VERSION "dbc-export 1 2026.26.6.5"

NS_ :

BS_:

BU_: ADSP APB APP APS APSB BB BMS CC CMP CMPD CP DAS DI DIF DIR DPB EPAS3P EPAS3S EPASTP EPASTS EPBL EPBR ESP EVSE FC GTW HCML HCMR HVP IBST ICR IDB LS OCS1P ODIN PARK PCS PCS2 PLG PM PMF PMR PNCD PTC RADC RCM RCM2 RCM3 RCU SCCM SCM SCS SDCR TAS TCU TCU2 TPMS TRCM UDS UI UIS UMC USM V2G VC VCBATT VCBATT0 VCBATT1 VCBATT2 VCCC VCFRONT VCFRONT1 VCFRONT2 VCLEFT VCRIGHT VCSEAT2L VCSEAT2R VCSEC VEH

BO_ 1513 APP_alertLog: 8 APP
 SG_ APP_alertID M : 0|14@1+ (1,0) [0|16383] "" Vector__XXX
 SG_ APP_sw456_reason1 m456 : 16|9@1+ (1,0) [0|511] "" Vector__XXX
 SG_ APP_sw456_reason2 m456 : 25|9@1+ (1,0) [0|511] "" Vector__XXX
 SG_ APP_sw456_reason3 m456 : 34|9@1+ (1,0) [0|511] "" Vector__XXX
 SG_ APP_sw457_reason1 m457 : 16|9@1+ (1,0) [0|511] "" Vector__XXX
 SG_ APP_sw457_reason2 m457 : 25|9@1+ (1,0) [0|511] "" Vector__XXX
 SG_ APP_sw457_reason3 m457 : 34|9@1+ (1,0) [0|511] "" Vector__XXX
 SG_ APP_sw457_safeStateManeuver m457 : 43|2@1+ (1,0) [0|3] "" Vector__XXX
 SG_ APP_sw458_fsdCollisionValue m458 : 16|7@1+ (1,0) [0|127] "%" Vector__XXX
 SG_ APP_sw458_aebCollisionValue m458 : 24|7@1+ (1,0) [0|127] "%" Vector__XXX
 SG_ APP_sw458_aebDurationAtAceOnset m458 : 32|7@1+ (0.05,0) [0|6.35] "s" Vector__XXX
 SG_ APP_sw458_targetDistance m458 : 40|8@1+ (0.5,0) [0|127.5] "m" Vector__XXX
 SG_ APP_sw458_targetRelativeSpeed m458 : 48|8@1+ (0.4,-51.2) [-51.2|50.8] "m/s" Vector__XXX
 SG_ APP_sw458_egoVehicleSpeed m458 : 56|8@1+ (0.25,0) [0|63.75] "m/s" Vector__XXX
 SG_ APP_sw459_status m459 : 16|1@1+ (1,0) [0|1] "" Vector__XXX
 SG_ APP_sw460_status m460 : 16|1@1+ (1,0) [0|1] "" Vector__XXX
 SG_ APP_sw461_rerouteRequest m461 : 16|2@1+ (1,0) [0|3] "" Vector__XXX
 SG_ APP_sw461_rerouteReason m461 : 18|9@1+ (1,0) [0|511] "" Vector__XXX
 SG_ APP_sw465_reason1 m465 : 16|9@1+ (1,0) [0|511] "" Vector__XXX
 SG_ APP_sw465_reason2 m465 : 25|9@1+ (1,0) [0|511] "" Vector__XXX
 SG_ APP_sw465_reason3 m465 : 34|9@1+ (1,0) [0|511] "" Vector__XXX
 SG_ APP_sw465_safeStateManeuver m465 : 43|2@1+ (1,0) [0|3] "" Vector__XXX

BO_ 1045 APP_backupDashCamStatus: 1 APP
 SG_ APP_backupDashCamFeedGood : 0|1@1+ (1,0) [0|1] "" Vector__XXX
 SG_ APP_backupDashCamFrameRate : 1|7@1+ (1,0) [0|127] "" Vector__XXX

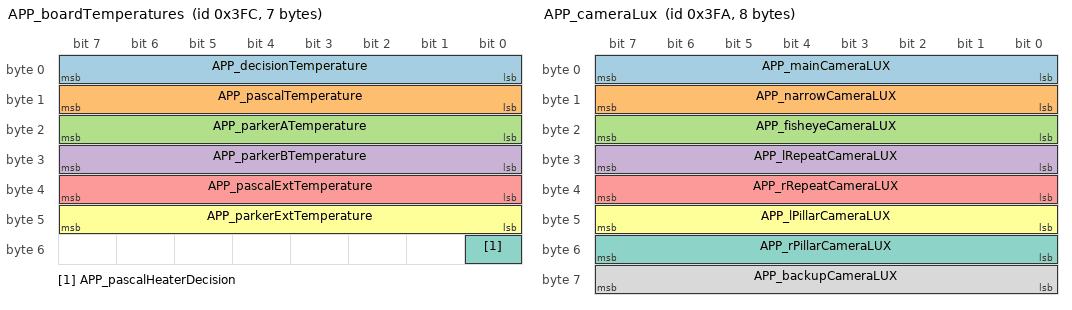
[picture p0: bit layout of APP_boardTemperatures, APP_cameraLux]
BO_ 1020 APP_boardTemperatures: 7 APP
 SG_ APP_decisionTemperature : 0|8@1+ (1,-128) [-128|127] "C" Vector__XXX
 SG_ APP_pascalTemperature : 8|8@1+ (1,-128) [-128|127] "C" Vector__XXX
 SG_ APP_parkerATemperature : 16|8@1+ (1,-128) [-128|127] "C" Vector__XXX
 SG_ APP_parkerBTemperature : 24|8@1+ (1,-128) [-128|127] "C" Vector__XXX
 SG_ APP_pascalExtTemperature : 32|8@1+ (1,-128) [-128|127] "C" Vector__XXX
 SG_ APP_parkerExtTemperature : 40|8@1+ (1,-128) [-128|127] "C" Vector__XXX
 SG_ APP_pascalHeaterDecision : 48|1@1+ (1,0) [0|1] "" Vector__XXX

BO_ 2046 APP_camCalibrationStatus: 6 APP
 SG_ APP_cameraPosition M : 0|4@1+ (1,0) [0|15] "" Vector__XXX
 SG_ APP_mainCamExtPitchCal m1 : 8|9@1+ (0.05,-12.5) [-12.5|12.5] "deg" Vector__XXX
 SG_ APP_mainCamExtYawCal m1 : 17|9@1+ (0.05,-12.5) [-12.5|12.5] "deg" Vector__XXX
 SG_ APP_mainCalibTime m1 : 26|7@1+ (1,0) [0|126] "min" Vector__XXX
 SG_ APP_mainCalibProgress m1 : 33|7@1+ (1,0) [0|100] "percent" Vector__XXX
 SG_ APP_mainCalibrated m1 : 40|1@1+ (1,0) [0|1] "" Vector__XXX
 SG_ APP_narrowCamExtPitchCal m2 : 8|9@1+ (0.05,-12.5) [-12.5|12.5] "deg" Vector__XXX
 SG_ APP_narrowCamExtYawCal m2 : 17|9@1+ (0.05,-12.5) [-12.5|12.5] "deg" Vector__XXX
 SG_ APP_narrowCalibTime m2 : 26|7@1+ (1,0) [0|126] "min" Vector__XXX
 SG_ APP_narrowCalibProgress m2 : 33|7@1+ (1,0) [0|100] "percent" Vector__XXX
 SG_ APP_narrowCalibrated m2 : 40|1@1+ (1,0) [0|1] "" Vector__XXX
 SG_ APP_fisheyeCamExtPitchCal m3 : 8|9@1+ (0.05,-12.5) [-12.5|12.5] "deg" Vector__XXX
 SG_ APP_fisheyeCamExtYawCal m3 : 17|9@1+ (0.05,-12.5) [-12.5|12.5] "deg" Vector__XXX
 SG_ APP_fisheyeCalibTime m3 : 26|7@1+ (1,0) [0|126] "min" Vector__XXX
 SG_ APP_fisheyeCalibProgress m3 : 33|7@1+ (1,0) [0|100] "percent" Vector__XXX
 SG_ APP_fisheyeCalibrated m3 : 40|1@1+ (1,0) [0|1] "" Vector__XXX
 SG_ APP_lPillarCamExtPitchCal m4 : 8|9@1+ (0.05,-12.5) [-12.5|12.5] "deg" Vector__XXX
 SG_ APP_lPillarCamExtYawCal m4 : 17|9@1+ (0.05,-12.5) [-12.5|12.5] "deg" Vector__XXX
 SG_ APP_lPillarCalibTime m4 : 26|7@1+ (1,0) [0|126] "min" Vector__XXX
 SG_ APP_lPillarCalibProgress m4 : 33|7@1+ (1,0) [0|100] "percent" Vector__XXX
 SG_ APP_lPillarCalibrated m4 : 40|1@1+ (1,0) [0|1] "" Vector__XXX
 SG_ APP_rPillarCamExtPitchCal m5 : 8|9@1+ (0.05,-12.5) [-12.5|12.5] "deg" Vector__XXX
 SG_ APP_rPillarCamExtYawCal m5 : 17|9@1+ (0.05,-12.5) [-12.5|12.5] "deg" Vector__XXX
 SG_ APP_rPillarCalibTime m5 : 26|7@1+ (1,0) [0|126] "min" Vector__XXX
 SG_ APP_rPillarCalibProgress m5 : 33|7@1+ (1,0) [0|100] "percent" Vector__XXX
 SG_ APP_rPillarCalibrated m5 : 40|1@1+ (1,0) [0|1] "" Vector__XXX
 SG_ APP_lRepeatCamExtPitchCal m6 : 8|9@1+ (0.05,-12.5) [-12.5|12.5] "deg" Vector__XXX
 SG_ APP_lRepeatCamExtYawCal m6 : 17|9@1+ (0.05,-12.5) [-12.5|12.5] "deg" Vector__XXX
 SG_ APP_lRepeatCalibTime m6 : 26|7@1+ (1,0) [0|126] "min" Vector__XXX
 SG_ APP_lRepeatCalibProgress m6 : 33|7@1+ (1,0) [0|100] "percent" Vector__XXX
 SG_ APP_lRepeatCalibrated m6 : 40|1@1+ (1,0) [0|1] "" Vector__XXX
 SG_ APP_rRepeatCamExtPitchCal m7 : 8|9@1+ (0.05,-12.5) [-12.5|12.5] "deg" Vector__XXX
 SG_ APP_rRepeatCamExtYawCal m7 : 17|9@1+ (0.05,-12.5) [-12.5|12.5] "deg" Vector__XXX
 SG_ APP_rRepeatCalibTime m7 : 26|7@1+ (1,0) [0|126] "min" Vector__XXX
 SG_ APP_rRepeatCalibProgress m7 : 33|7@1+ (1,0) [0|100] "percent" Vector__XXX
 SG_ APP_rRepeatCalibrated m7 : 40|1@1+ (1,0) [0|1] "" Vector__XXX
 SG_ APP_backupCamExtPitchCal m8 : 8|9@1+ (0.05,-12.5) [-12.5|12.5] "deg" Vector__XXX
 SG_ APP_backupCamExtYawCal m8 : 17|9@1+ (0.05,-12.5) [-12.5|12.5] "deg" Vector__XXX
 SG_ APP_backupCalibTime m8 : 26|7@1+ (1,0) [0|126] "min" Vector__XXX
 SG_ APP_backupCalibProgress m8 : 33|7@1+ (1,0) [0|100] "percent" Vector__XXX
 SG_ APP_backupCalibrated m8 : 40|1@1+ (1,0) [0|1] "" Vector__XXX
 SG_ APP_fasciaCamExtPitchCal m10 : 8|9@1+ (0.05,-12.5) [-12.5|12.5] "deg" Vector__XXX
 SG_ APP_fasciaCamExtYawCal m10 : 17|9@1+ (0.05,-12.5) [-12.5|12.5] "deg" Vector__XXX
 SG_ APP_fasciaCalibTime m10 : 26|7@1+ (1,0) [0|126] "min" Vector__XXX
 SG_ APP_fasciaCalibProgress m10 : 33|7@1+ (1,0) [0|100] "percent" Vector__XXX
 SG_ APP_fasciaCalibrated m10 : 40|1@1+ (1,0) [0|1] "" Vector__XXX

BO_ 1018 APP_cameraLux: 8 APP
 SG_ APP_mainCameraLUX : 0|8@1+ (0.5,0) [0|127] "lux^0.5" Vector__XXX
 SG_ APP_narrowCameraLUX : 8|8@1+ (0.5,0) [0|127] "lux^0.5" Vector__XXX
 SG_ APP_fisheyeCameraLUX : 16|8@1+ (0.5,0) [0|127] "lux^0.5" Vector__XXX
 SG_ APP_lRepeatCameraLUX : 24|8@1+ (0.5,0) [0|127] "lux^0.5" Vector__XXX
 SG_ APP_rRepeatCameraLUX : 32|8@1+ (0.5,0) [0|127] "lux^0.5" Vector__XXX
 SG_ APP_lPillarCameraLUX : 40|8@1+ (0.5,0) [0|127] "lux^0.5" Vector__XXX
 SG_ APP_rPillarCameraLUX : 48|8@1+ (0.5,0) [0|127] "lux^0.5" Vector__XXX
 SG_ APP_backupCameraLUX : 56|8@1+ (0.5,0) [0|127] "lux^0.5" Vector__XXX

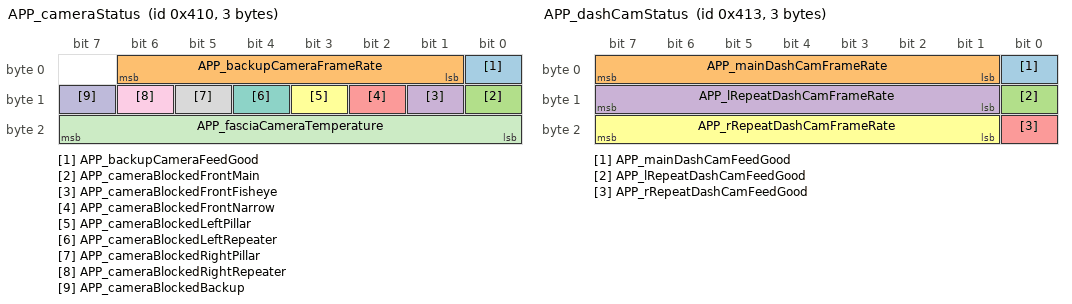
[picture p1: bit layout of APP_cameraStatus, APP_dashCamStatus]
BO_ 1040 APP_cameraStatus: 3 APP
 SG_ APP_backupCameraFeedGood : 0|1@1+ (1,0) [0|1] "" Vector__XXX
 SG_ APP_backupCameraFrameRate : 1|6@1+ (1,0) [0|63] "" Vector__XXX
 SG_ APP_cameraBlockedFrontMain : 8|1@1+ (1,0) [0|1] "" Vector__XXX
 SG_ APP_cameraBlockedFrontFisheye : 9|1@1+ (1,0) [0|1] "" Vector__XXX
 SG_ APP_cameraBlockedFrontNarrow : 10|1@1+ (1,0) [0|1] "" Vector__XXX
 SG_ APP_cameraBlockedLeftPillar : 11|1@1+ (1,0) [0|1] "" Vector__XXX
 SG_ APP_cameraBlockedLeftRepeater : 12|1@1+ (1,0) [0|1] "" Vector__XXX
 SG_ APP_cameraBlockedRightPillar : 13|1@1+ (1,0) [0|1] "" Vector__XXX
 SG_ APP_cameraBlockedRightRepeater : 14|1@1+ (1,0) [0|1] "" Vector__XXX
 SG_ APP_cameraBlockedBackup : 15|1@1+ (1,0) [0|1] "" Vector__XXX
 SG_ APP_fasciaCameraTemperature : 16|8@1+ (1,-60) [-60|194] "C" Vector__XXX

BO_ 1177 APP_cameraTemperatures: 8 APP
 SG_ APP_rRepeaterCameraTemperature : 24|8@1+ (1,-60) [-60|195] "C" Vector__XXX
 SG_ APP_lRepeaterCameraTemperature : 32|8@1+ (1,-60) [-60|195] "C" Vector__XXX

BO_ 1043 APP_dashCamStatus: 3 APP
 SG_ APP_mainDashCamFeedGood : 0|1@1+ (1,0) [0|1] "" Vector__XXX
 SG_ APP_mainDashCamFrameRate : 1|7@1+ (1,0) [0|127] "" Vector__XXX
 SG_ APP_lRepeatDashCamFeedGood : 8|1@1+ (1,0) [0|1] "" Vector__XXX
 SG_ APP_lRepeatDashCamFrameRate : 9|7@1+ (1,0) [0|127] "" Vector__XXX
 SG_ APP_rRepeatDashCamFeedGood : 16|1@1+ (1,0) [0|1] "" Vector__XXX
 SG_ APP_rRepeatDashCamFrameRate : 17|7@1+ (1,0) [0|127] "" Vector__XXX

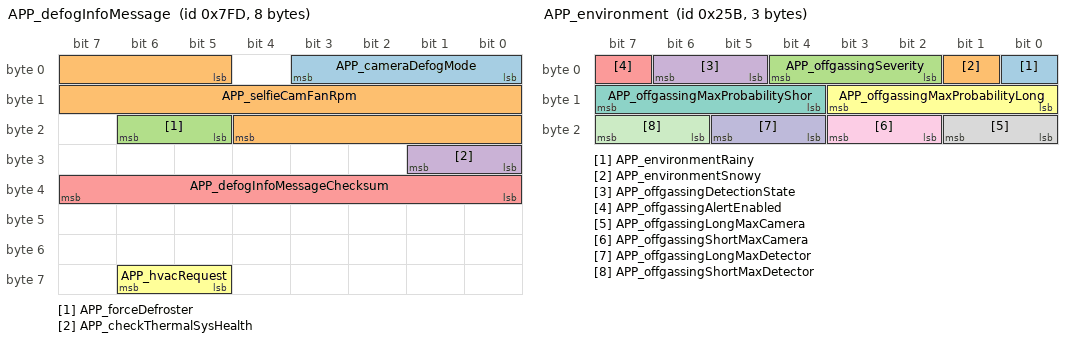
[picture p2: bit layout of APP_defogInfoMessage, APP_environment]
BO_ 2045 APP_defogInfoMessage: 8 APP
 SG_ APP_cameraDefogMode : 0|4@1+ (1,0) [1|15] "" Vector__XXX
 SG_ APP_selfieCamFanRpm : 5|16@1+ (1,0) [0|65534] "rpm" Vector__XXX
 SG_ APP_forceDefroster : 21|2@1+ (1,0) [1|3] "" Vector__XXX
 SG_ APP_checkThermalSysHealth : 24|2@1+ (1,0) [1|3] "" Vector__XXX
 SG_ APP_defogInfoMessageChecksum : 32|8@1+ (1,0) [0|255] "" Vector__XXX
 SG_ APP_hvacRequest : 61|2@1+ (1,0) [1|3] "" Vector__XXX

BO_ 939 APP_driverMonitorStatus: 5 APP
 SG_ APP_cabinCamTelemetryOn : 0|1@1+ (1,0) [0|1] "" Vector__XXX
 SG_ APP_attnMonitorVersion : 1|3@1+ (1,0) [0|6] "" Vector__XXX
 SG_ APP_attnBasedDriverMonitorOn : 4|1@1+ (1,0) [0|1] "" Vector__XXX
 SG_ APP_handsOnDetected : 5|1@1+ (1,0) [0|1] "" Vector__XXX
 SG_ APP_handsOnDetectedSource : 8|3@1+ (1,0) [0|6] "" Vector__XXX
 SG_ APP_cabinCamBlinded : 11|1@1+ (1,0) [0|1] "" Vector__XXX
 SG_ APP_cabinCamDark : 12|1@1+ (1,0) [0|1] "" Vector__XXX
 SG_ APP_driverStateUnknown : 13|1@1+ (1,0) [0|1] "" Vector__XXX
 SG_ APP_driverNotLively : 14|1@1+ (1,0) [0|1] "" Vector__XXX
 SG_ APP_driverStateUnknownHyst : 15|1@1+ (1,0) [0|1] "" Vector__XXX
 SG_ APP_driverLowNominal : 16|1@1+ (1,0) [0|1] "" Vector__XXX
 SG_ APP_driverHeadCappedHyst : 17|1@1+ (1,0) [0|1] "" Vector__XXX
 SG_ APP_driverSunglassesUseHyst : 18|1@1+ (1,0) [0|1] "" Vector__XXX
 SG_ APP_cabinLowLux : 19|1@1+ (1,0) [0|1] "" Vector__XXX
 SG_ APP_cabinCamInconsistent : 20|1@1+ (1,0) [0|1] "" Vector__XXX
 SG_ APP_driverLeaningBack : 21|1@1+ (1,0) [0|1] "" Vector__XXX
 SG_ APP_driverLowEyeVisibility : 22|1@1+ (1,0) [0|1] "" Vector__XXX
 SG_ APP_driverHandsNotReady : 23|1@1+ (1,0) [0|1] "" Vector__XXX
 SG_ APP_driverSeatUnoccupied : 24|1@1+ (1,0) [0|1] "" Vector__XXX
 SG_ APP_handsOnInputRequired : 25|1@1+ (1,0) [0|1] "" Vector__XXX
 SG_ APP_cabinCamDarkHyst : 26|1@1+ (1,0) [0|1] "" Vector__XXX
 SG_ APP_cabinLowLuxHyst : 27|1@1+ (1,0) [0|1] "" Vector__XXX
 SG_ APP_ADDWSystemStatus : 28|2@1+ (1,0) [0|3] "" Vector__XXX
 SG_ APP_dmStrictness : 30|2@1+ (1,0) [1|3] "" Vector__XXX
 SG_ APP_dmStrictnessReason : 32|6@1+ (1,0) [1|63] "" Vector__XXX

BO_ 603 APP_environment: 3 APP
 SG_ APP_environmentRainy : 0|1@1+ (1,0) [0|1] "" Vector__XXX
 SG_ APP_environmentSnowy : 1|1@1+ (1,0) [0|1] "" Vector__XXX
 SG_ APP_offgassingSeverity : 2|3@1+ (1,0) [1|7] "" Vector__XXX
 SG_ APP_offgassingDetectionState : 5|2@1+ (1,0) [1|3] "" Vector__XXX
 SG_ APP_offgassingAlertEnabled : 7|1@1+ (1,0) [0|1] "" Vector__XXX
 SG_ APP_offgassingMaxProbabilityLong : 8|4@1+ (1,0) [1|15] "" Vector__XXX
 SG_ APP_offgassingMaxProbabilityShor : 12|4@1+ (1,0) [1|15] "" Vector__XXX
 SG_ APP_offgassingLongMaxCamera : 16|2@1+ (1,0) [1|3] "" Vector__XXX
 SG_ APP_offgassingShortMaxCamera : 18|2@1+ (1,0) [1|3] "" Vector__XXX
 SG_ APP_offgassingLongMaxDetector : 20|2@1+ (1,0) [1|3] "" Vector__XXX
 SG_ APP_offgassingShortMaxDetector : 22|2@1+ (1,0) [1|3] "" Vector__XXX

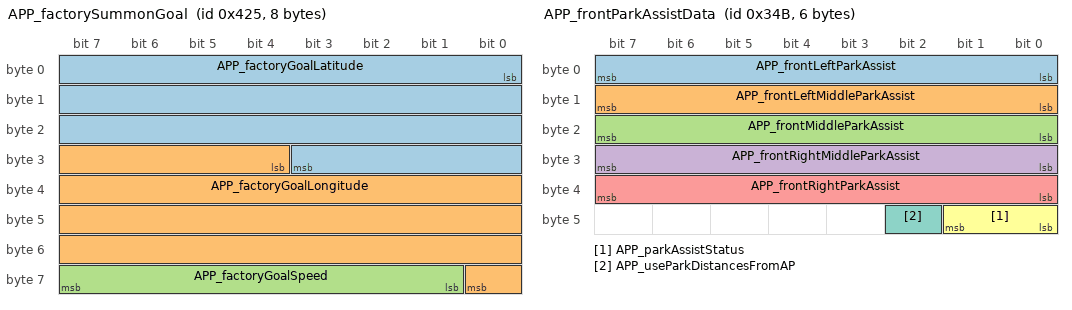
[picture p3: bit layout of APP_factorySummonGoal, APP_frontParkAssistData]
BO_ 1061 APP_factorySummonGoal: 8 APP
 SG_ APP_factoryGoalLatitude : 0|28@1- (1.0e-06,0) [-134.217728|134.217727] "deg" Vector__XXX
 SG_ APP_factoryGoalLongitude : 28|29@1- (1.0e-06,0) [-268.435456|268.435454] "deg" Vector__XXX
 SG_ APP_factoryGoalSpeed : 57|7@1+ (1,0) [0|100] "mph" Vector__XXX

BO_ 843 APP_frontParkAssistData: 6 APP
 SG_ APP_frontLeftParkAssist : 0|8@1+ (1,0) [0|254] "cm" Vector__XXX
 SG_ APP_frontLeftMiddleParkAssist : 8|8@1+ (1,0) [0|254] "cm" Vector__XXX
 SG_ APP_frontMiddleParkAssist : 16|8@1+ (1,0) [0|254] "cm" Vector__XXX
 SG_ APP_frontRightMiddleParkAssist : 24|8@1+ (1,0) [0|254] "cm" Vector__XXX
 SG_ APP_frontRightParkAssist : 32|8@1+ (1,0) [0|254] "cm" Vector__XXX
 SG_ APP_parkAssistStatus : 40|2@1+ (1,0) [0|2] "" Vector__XXX
 SG_ APP_useParkDistancesFromAP : 42|1@1+ (1,0) [0|1] "" Vector__XXX

BO_ 1353 APP_info: 8 APP
 SG_ APP_infoIndex M : 0|8@1+ (1,0) [0|255] "" Vector__XXX
 SG_ APP_buildType m0 : 8|8@1+ (1,0) [0|255] "" Vector__XXX

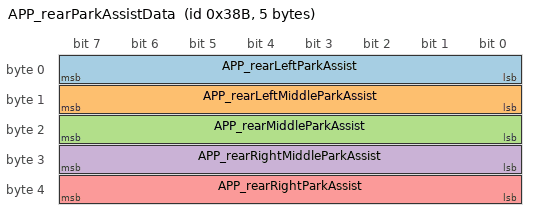
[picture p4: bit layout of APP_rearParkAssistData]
BO_ 907 APP_rearParkAssistData: 5 APP
 SG_ APP_rearLeftParkAssist : 0|8@1+ (1,0) [0|254] "cm" Vector__XXX
 SG_ APP_rearLeftMiddleParkAssist : 8|8@1+ (1,0) [0|254] "cm" Vector__XXX
 SG_ APP_rearMiddleParkAssist : 16|8@1+ (1,0) [0|254] "cm" Vector__XXX
 SG_ APP_rearRightMiddleParkAssist : 24|8@1+ (1,0) [0|254] "cm" Vector__XXX
 SG_ APP_rearRightParkAssist : 32|8@1+ (1,0) [0|254] "cm" Vector__XXX

BO_TX_BU_ 1045 : APP;
BO_TX_BU_ 1020 : APP;
BO_TX_BU_ 2046 : APP;
BO_TX_BU_ 1018 : APP;
BO_TX_BU_ 1040 : APP;
BO_TX_BU_ 1177 : APP;
BO_TX_BU_ 1043 : APP;
BO_TX_BU_ 2045 : APP;
BO_TX_BU_ 939 : APP;
BO_TX_BU_ 603 : APP;
BO_TX_BU_ 1061 : APP;
BO_TX_BU_ 843 : APP;
BO_TX_BU_ 1353 : APP;
BO_TX_BU_ 907 : APP;
CM_ SG_ 1513 APP_sw456_reason1 "Driver assistance computer (primary): sw456 reason1";
CM_ SG_ 1513 APP_sw456_reason2 "Driver assistance computer (primary): sw456 reason2";
CM_ SG_ 1513 APP_sw456_reason3 "Driver assistance computer (primary): sw456 reason3";
CM_ SG_ 1513 APP_sw457_reason1 "Driver assistance computer (primary): sw457 reason1";
CM_ SG_ 1513 APP_sw457_reason2 "Driver assistance computer (primary): sw457 reason2";
CM_ SG_ 1513 APP_sw457_reason3 "Driver assistance computer (primary): sw457 reason3";
CM_ SG_ 1513 APP_sw457_safeStateManeuver "Driver assistance computer (primary): sw457 safe state maneuver";
CM_ SG_ 1513 APP_sw458_fsdCollisionValue "Driver assistance computer (primary): sw458 fsd collision value";
CM_ SG_ 1513 APP_sw458_aebCollisionValue "Driver assistance computer (primary): sw458 aeb collision value";
CM_ SG_ 1513 APP_sw458_aebDurationAtAceOnset "Driver assistance computer (primary): sw458 aeb duration at ace onset";
CM_ SG_ 1513 APP_sw458_targetDistance "Driver assistance computer (primary): sw458 target distance";
CM_ SG_ 1513 APP_sw458_targetRelativeSpeed "Driver assistance computer (primary): sw458 target relative speed";
CM_ SG_ 1513 APP_sw458_egoVehicleSpeed "Driver assistance computer (primary): sw458 ego vehicle speed";
CM_ SG_ 1513 APP_sw459_status "Driver assistance computer (primary): sw459 status";
CM_ SG_ 1513 APP_sw460_status "Driver assistance computer (primary): sw460 status";
CM_ SG_ 1513 APP_sw461_rerouteRequest "Driver assistance computer (primary): sw461 reroute request";
CM_ SG_ 1513 APP_sw461_rerouteReason "Driver assistance computer (primary): sw461 reroute reason";
CM_ SG_ 1513 APP_sw465_reason1 "Driver assistance computer (primary): sw465 reason1";
CM_ SG_ 1513 APP_sw465_reason2 "Driver assistance computer (primary): sw465 reason2";
CM_ SG_ 1513 APP_sw465_reason3 "Driver assistance computer (primary): sw465 reason3";
CM_ SG_ 1513 APP_sw465_safeStateManeuver "Driver assistance computer (primary): sw465 safe state maneuver";
CM_ BO_ 1045 "Driver assistance computer (primary) message: backup dash cam status";
CM_ SG_ 1045 APP_backupDashCamFeedGood "Indicates if the backup dash cam stream is healthy.";
CM_ SG_ 1045 APP_backupDashCamFrameRate "The backup dash cam frame rate.";
CM_ BO_ 1020 "Driver assistance computer (primary) message: board temperatures";
CM_ SG_ 1020 APP_decisionTemperature "Rolling average of Parker and Pascal temperature.";
CM_ SG_ 1020 APP_pascalTemperature "Temperature of Autopilot GPU";
CM_ SG_ 1020 APP_parkerATemperature "Temperature of Autopilot CPU(1)";
CM_ SG_ 1020 APP_parkerBTemperature "Temperature of Autopilot CPU(1)";
CM_ SG_ 1020 APP_pascalExtTemperature "External temperature of Autopilot GPU";
CM_ SG_ 1020 APP_parkerExtTemperature "External temperature of Parker";
CM_ SG_ 1020 APP_pascalHeaterDecision "Pascal heater descision on/off";
CM_ BO_ 2046 "Driver assistance computer (primary) message: cam calibration status";
CM_ SG_ 2046 APP_cameraPosition "Driver assistance computer (primary): camera position";
CM_ SG_ 2046 APP_mainCamExtPitchCal "The calibration, pitch or yaw offset of a camera; raw 511 = signal not available (SNA)";
CM_ SG_ 2046 APP_mainCamExtYawCal "The calibration, pitch or yaw offset of a camera; raw 511 = signal not available (SNA)";
CM_ SG_ 2046 APP_mainCalibTime "Driver assistance computer (primary): main calib time; raw 127 = signal not available (SNA)";
CM_ SG_ 2046 APP_mainCalibProgress "The percent progress of the main camera calibration; raw 127 = signal not available (SNA)";
CM_ SG_ 2046 APP_mainCalibrated "Whether or not the main camera is calibrated.";
CM_ SG_ 2046 APP_narrowCamExtPitchCal "The calibration, pitch or yaw offset of a camera; raw 511 = signal not available (SNA)";
CM_ SG_ 2046 APP_narrowCamExtYawCal "The calibration, pitch or yaw offset of a camera; raw 511 = signal not available (SNA)";
CM_ SG_ 2046 APP_narrowCalibTime "Driver assistance computer (primary): narrow calib time; raw 127 = signal not available (SNA)";
CM_ SG_ 2046 APP_narrowCalibProgress "The percent progress of the narrow camera calibration; raw 127 = signal not available (SNA)";
CM_ SG_ 2046 APP_narrowCalibrated "Whether or not the narrow camera is calibrated.";
CM_ SG_ 2046 APP_fisheyeCamExtPitchCal "The calibration, pitch or yaw offset of a camera; raw 511 = signal not available (SNA)";
CM_ SG_ 2046 APP_fisheyeCamExtYawCal "The calibration, pitch or yaw offset of a camera; raw 511 = signal not available (SNA)";
CM_ SG_ 2046 APP_fisheyeCalibTime "Driver assistance computer (primary): fisheye calib time; raw 127 = signal not available (SNA)";
CM_ SG_ 2046 APP_fisheyeCalibProgress "The percent progress of the fisheye camera calibration; raw 127 = signal not available (SNA)";
CM_ SG_ 2046 APP_fisheyeCalibrated "Whether or not the fisheye camera is calibrated.";
CM_ SG_ 2046 APP_lPillarCamExtPitchCal "The calibration, pitch or yaw offset of a camera; raw 511 = signal not available (SNA)";
CM_ SG_ 2046 APP_lPillarCamExtYawCal "The calibration, pitch or yaw offset of a camera; raw 511 = signal not available (SNA)";
CM_ SG_ 2046 APP_lPillarCalibTime "Driver assistance computer (primary): l pillar calib time; raw 127 = signal not available (SNA)";
CM_ SG_ 2046 APP_lPillarCalibProgress "The percent progress of the left pillar camera calibration; raw 127 = signal not available (SNA)";
CM_ SG_ 2046 APP_lPillarCalibrated "Whether or not the left pillar camera is calibrated.";
CM_ SG_ 2046 APP_rPillarCamExtPitchCal "The calibration, pitch or yaw offset of a camera; raw 511 = signal not available (SNA)";
CM_ SG_ 2046 APP_rPillarCamExtYawCal "The calibration, pitch or yaw offset of a camera; raw 511 = signal not available (SNA)";
CM_ SG_ 2046 APP_rPillarCalibTime "Driver assistance computer (primary): r pillar calib time; raw 127 = signal not available (SNA)";
CM_ SG_ 2046 APP_rPillarCalibProgress "The percent progress of the right pillar camera calibration; raw 127 = signal not available (SNA)";
CM_ SG_ 2046 APP_rPillarCalibrated "Whether or not the right pillar camera is calibrated.";
CM_ SG_ 2046 APP_lRepeatCamExtPitchCal "The calibration, pitch or yaw offset of a camera; raw 511 = signal not available (SNA)";
CM_ SG_ 2046 APP_lRepeatCamExtYawCal "The calibration, pitch or yaw offset of a camera; raw 511 = signal not available (SNA)";
CM_ SG_ 2046 APP_lRepeatCalibTime "Driver assistance computer (primary): l repeat calib time; raw 127 = signal not available (SNA)";
CM_ SG_ 2046 APP_lRepeatCalibProgress "The percent progress of the left repeater camera calibration; raw 127 = signal not available (SNA)";
CM_ SG_ 2046 APP_lRepeatCalibrated "Whether or not the left repeater camera is calibrated.";
CM_ SG_ 2046 APP_rRepeatCamExtPitchCal "The calibration, pitch or yaw offset of a camera; raw 511 = signal not available (SNA)";
CM_ SG_ 2046 APP_rRepeatCamExtYawCal "The calibration, pitch or yaw offset of a camera; raw 511 = signal not available (SNA)";
CM_ SG_ 2046 APP_rRepeatCalibTime "Driver assistance computer (primary): r repeat calib time; raw 127 = signal not available (SNA)";
CM_ SG_ 2046 APP_rRepeatCalibProgress "The percent progress of the right repeater camera calibration; raw 127 = signal not available (SNA)";
CM_ SG_ 2046 APP_rRepeatCalibrated "Whether or not the right repeater camera is calibrated.";
CM_ SG_ 2046 APP_backupCamExtPitchCal "The calibration, pitch or yaw offset of a camera; raw 511 = signal not available (SNA)";
CM_ SG_ 2046 APP_backupCamExtYawCal "The calibration, pitch or yaw offset of a camera; raw 511 = signal not available (SNA)";
CM_ SG_ 2046 APP_backupCalibTime "Driver assistance computer (primary): backup calib time; raw 127 = signal not available (SNA)";
CM_ SG_ 2046 APP_backupCalibProgress "The percent progress of the backup calibration; raw 127 = signal not available (SNA)";
CM_ SG_ 2046 APP_backupCalibrated "Whether or not the backup camera is calibrated.";
CM_ SG_ 2046 APP_fasciaCamExtPitchCal "The calibration, pitch or yaw offset of a camera; raw 511 = signal not available (SNA)";
CM_ SG_ 2046 APP_fasciaCamExtYawCal "The calibration, pitch or yaw offset of a camera; raw 511 = signal not available (SNA)";
CM_ SG_ 2046 APP_fasciaCalibTime "Driver assistance computer (primary): fascia calib time; raw 127 = signal not available (SNA)";
CM_ SG_ 2046 APP_fasciaCalibProgress "The percent progress of the fascia calibration; raw 127 = signal not available (SNA)";
CM_ SG_ 2046 APP_fasciaCalibrated "Whether or not the fascia camera is calibrated.";
CM_ BO_ 1018 "Driver assistance computer (primary) message: camera lux";
CM_ SG_ 1018 APP_mainCameraLUX "Amount of illuminance seen by the main camera; raw 255 = signal not available (SNA)";
CM_ SG_ 1018 APP_narrowCameraLUX "Driver assistance computer (primary): narrow camera LUX; raw 255 = signal not available (SNA)";
CM_ SG_ 1018 APP_fisheyeCameraLUX "Driver assistance computer (primary): fisheye camera LUX; raw 255 = signal not available (SNA)";
CM_ SG_ 1018 APP_lRepeatCameraLUX "Driver assistance computer (primary): l repeat camera LUX; raw 255 = signal not available (SNA)";
CM_ SG_ 1018 APP_rRepeatCameraLUX "Driver assistance computer (primary): r repeat camera LUX; raw 255 = signal not available (SNA)";
CM_ SG_ 1018 APP_lPillarCameraLUX "Driver assistance computer (primary): l pillar camera LUX; raw 255 = signal not available (SNA)";
CM_ SG_ 1018 APP_rPillarCameraLUX "Driver assistance computer (primary): r pillar camera LUX; raw 255 = signal not available (SNA)";
CM_ SG_ 1018 APP_backupCameraLUX "Driver assistance computer (primary): backup camera LUX; raw 255 = signal not available (SNA)";
CM_ BO_ 1040 "Driver assistance computer (primary) message: camera status";
CM_ SG_ 1040 APP_backupCameraFeedGood "Indicates if the backup camera stream is healthy.";
CM_ SG_ 1040 APP_backupCameraFrameRate "The backup camera frame rate.";
CM_ SG_ 1040 APP_cameraBlockedFrontMain "Indicates that a blockage was detected by the main forward camera.";
CM_ SG_ 1040 APP_cameraBlockedFrontFisheye "Indicates that a blockage was detected by the fisheye camera.";
CM_ SG_ 1040 APP_cameraBlockedFrontNarrow "Indicates that a blockage was detected by the narrow camera.";
CM_ SG_ 1040 APP_cameraBlockedLeftPillar "Indicates that a blockage was detected by the left pillar camera.";
CM_ SG_ 1040 APP_cameraBlockedLeftRepeater "Indicates that a blockage was detected by the left repeater camera.";
CM_ SG_ 1040 APP_cameraBlockedRightPillar "Indicates that a blockage was detected by the right pillar camera.";
CM_ SG_ 1040 APP_cameraBlockedRightRepeater "Indicates that a blockage was detected by the right repeater camera.";
CM_ SG_ 1040 APP_cameraBlockedBackup "Indicates that a blockage was detected by the backup camera.";
CM_ SG_ 1040 APP_fasciaCameraTemperature "Die temperature of camera image sensor; raw 255 = signal not available (SNA)";
CM_ BO_ 1177 "Driver assistance computer (primary) message: camera temperatures";
CM_ SG_ 1177 APP_rRepeaterCameraTemperature "Driver assistance computer (primary): r repeater camera temperature";
CM_ SG_ 1177 APP_lRepeaterCameraTemperature "Driver assistance computer (primary): l repeater camera temperature";
CM_ BO_ 1043 "Driver assistance computer (primary) message: dash cam status";
CM_ SG_ 1043 APP_mainDashCamFeedGood "Indicates if the main dash cam stream is healthy.";
CM_ SG_ 1043 APP_mainDashCamFrameRate "The main dash cam frame rate.";
CM_ SG_ 1043 APP_lRepeatDashCamFeedGood "Indicates if the left repeater dash cam stream is healthy.";
CM_ SG_ 1043 APP_lRepeatDashCamFrameRate "The left repeater dash cam frame rate.";
CM_ SG_ 1043 APP_rRepeatDashCamFeedGood "Indicates if the right repeater dash cam stream is healthy.";
CM_ SG_ 1043 APP_rRepeatDashCamFrameRate "The right repeater dash cam frame rate.";
CM_ BO_ 2045 "Driver assistance computer (primary) message: defog info message";
CM_ SG_ 2045 APP_cameraDefogMode "Instructs SGK to activate or deactivate cameras when the vehicle is in a parked state; raw 0 = signal not available (SNA)";
CM_ SG_ 2045 APP_selfieCamFanRpm "Indicates the selfie camera fan rpm; raw 65535 = signal not available (SNA)";
CM_ SG_ 2045 APP_forceDefroster "Force Front Defroster mode instructs VC to activate defog/defrost when AP detects dew/fog; raw 0 = signal not available (SNA)";
CM_ SG_ 2045 APP_checkThermalSysHealth "Driver assistance computer (primary): check thermal sys health; raw 0 = signal not available (SNA)";
CM_ SG_ 2045 APP_defogInfoMessageChecksum "Driver assistance computer (primary): defog info message checksum";
CM_ SG_ 2045 APP_hvacRequest "Das request to turn on HVAC; raw 0 = signal not available (SNA)";
CM_ BO_ 939 "Driver assistance computer (primary) message: driver monitor status";
CM_ SG_ 939 APP_cabinCamTelemetryOn "Driver assistance computer (primary): cabin cam telemetry on";
CM_ SG_ 939 APP_attnMonitorVersion "Driver assistance computer (primary): attn monitor version; raw 7 = signal not available (SNA)";
CM_ SG_ 939 APP_attnBasedDriverMonitorOn "Indicates whether attention based Driver Monitor is currently enabled during Autosteer/Full Self-Driving (FSD).";
CM_ SG_ 939 APP_handsOnDetected "Indicates whether Driver Monitor detects that a user has their hands on the wheel during Autosteer/Full Self-Driving (FSD).";
CM_ SG_ 939 APP_handsOnDetectedSource "Reports the source of the hands on detection output from driver monitor; raw 7 = signal not available (SNA)";
CM_ SG_ 939 APP_cabinCamBlinded "Indicates that the cabin camera is detected as blinded.";
CM_ SG_ 939 APP_cabinCamDark "Indicates that the cabin camera is detected as dark.";
CM_ SG_ 939 APP_driverStateUnknown "Indicates that the cabin camera detects the driver state as unknown.";
CM_ SG_ 939 APP_driverNotLively "Reports that the cabin camera detects the driver as not lively.";
CM_ SG_ 939 APP_driverStateUnknownHyst "Indicates that the cabin camera detects the driver state as unknown, with a logging lag to reduce excess signal noise by briefly indicating 'unknown' even if 'unknown' is no longer detected.";
CM_ SG_ 939 APP_driverLowNominal "Indicates that the cabin camera detects the driver's forward eye gaze is low.";
CM_ SG_ 939 APP_driverHeadCappedHyst "Indicates that the cabin camera detects a driver head obstruction.";
CM_ SG_ 939 APP_driverSunglassesUseHyst "Indicates that the cabin camera detects driver is wearing sunglasses.";
CM_ SG_ 939 APP_cabinLowLux "Indicates that the cabin camera detects cabin illumination is low.";
CM_ SG_ 939 APP_cabinCamInconsistent "Indicates that Driver Monitor detects inconsistencies in cabin camera network signals.";
CM_ SG_ 939 APP_driverLeaningBack "Indicates that the cabin camera detects driver may be leaning back and not ready to take over.";
CM_ SG_ 939 APP_driverLowEyeVisibility "Indicates that the cabin camera detects degraded driver eye visibility.";
CM_ SG_ 939 APP_driverHandsNotReady "Indicates that the cabin camera detects driver hands may not be near steering wheel/yoke.";
CM_ SG_ 939 APP_driverSeatUnoccupied "Reports that the cabin camera detects that driver seat may not be occupied.";
CM_ SG_ 939 APP_handsOnInputRequired "Indicates that driver monitoring requires driver hands-on acknowledgement.";
CM_ SG_ 939 APP_cabinCamDarkHyst "Indicates that the cabin camera is detected as dark, with a logging lag to reduce excess signal noise by briefly indicating 'dark' even if 'dark' is no longer detected.";
CM_ SG_ 939 APP_cabinLowLuxHyst "Indicates that the cabin camera detects cabin illumination low, with a logging lag to reduce excess signal noise by briefly indicating 'low' even if 'low' is no longer detected.";
CM_ SG_ 939 APP_ADDWSystemStatus "Reports the Advanced Distracted Driver Warning (ADDW) system status.";
CM_ SG_ 939 APP_dmStrictness "Driver assistance computer (primary): dm strictness; raw 0 = signal not available (SNA)";
CM_ SG_ 939 APP_dmStrictnessReason "Driver assistance computer (primary): dm strictness reason; raw 0 = signal not available (SNA)";
CM_ BO_ 603 "Driver assistance computer (primary) message: environment";
CM_ SG_ 603 APP_environmentRainy "Driver assistance computer (primary): environment rainy";
CM_ SG_ 603 APP_environmentSnowy "Driver assistance computer (primary): environment snowy";
CM_ SG_ 603 APP_offgassingSeverity "Driver assistance computer (primary): offgassing severity; raw 0 = signal not available (SNA)";
CM_ SG_ 603 APP_offgassingDetectionState "Driver assistance computer (primary): offgassing detection state; raw 0 = signal not available (SNA)";
CM_ SG_ 603 APP_offgassingAlertEnabled "Driver assistance computer (primary): offgassing alert enabled";
CM_ SG_ 603 APP_offgassingMaxProbabilityLong "Driver assistance computer (primary): offgassing max probability long; raw 0 = signal not available (SNA)";
CM_ SG_ 603 APP_offgassingMaxProbabilityShor "Driver assistance computer (primary): offgassing max probability short; raw 0 = signal not available (SNA)";
CM_ SG_ 603 APP_offgassingLongMaxCamera "Driver assistance computer (primary): offgassing long max camera; raw 0 = signal not available (SNA)";
CM_ SG_ 603 APP_offgassingShortMaxCamera "Driver assistance computer (primary): offgassing short max camera; raw 0 = signal not available (SNA)";
CM_ SG_ 603 APP_offgassingLongMaxDetector "Driver assistance computer (primary): offgassing long max detector; raw 0 = signal not available (SNA)";
CM_ SG_ 603 APP_offgassingShortMaxDetector "Driver assistance computer (primary): offgassing short max detector; raw 0 = signal not available (SNA)";
CM_ BO_ 1061 "Driver assistance computer (primary) message: factory summon goal";
CM_ SG_ 1061 APP_factoryGoalLatitude "Driver assistance computer (primary): factory goal latitude";
CM_ SG_ 1061 APP_factoryGoalLongitude "Driver assistance computer (primary): factory goal longitude";
CM_ SG_ 1061 APP_factoryGoalSpeed "Driver assistance computer (primary): factory goal speed";
CM_ BO_ 843 "Driver assistance computer (primary) message: front park assist data";
CM_ SG_ 843 APP_frontLeftParkAssist "Driver assistance computer (primary): front left park assist; raw 255 = signal not available (SNA)";
CM_ SG_ 843 APP_frontLeftMiddleParkAssist "Driver assistance computer (primary): front left middle park assist; raw 255 = signal not available (SNA)";
CM_ SG_ 843 APP_frontMiddleParkAssist "Driver assistance computer (primary): front middle park assist; raw 255 = signal not available (SNA)";
CM_ SG_ 843 APP_frontRightMiddleParkAssist "Driver assistance computer (primary): front right middle park assist; raw 255 = signal not available (SNA)";
CM_ SG_ 843 APP_frontRightParkAssist "Driver assistance computer (primary): front right park assist; raw 255 = signal not available (SNA)";
CM_ SG_ 843 APP_parkAssistStatus "Driver assistance computer (primary): park assist status; raw 3 = signal not available (SNA)";
CM_ SG_ 843 APP_useParkDistancesFromAP "Driver assistance computer (primary): use park distances from AP";
CM_ BO_ 1353 "Driver assistance computer (primary) message: info";
CM_ SG_ 1353 APP_infoIndex "Driver assistance computer (primary): info index";
CM_ SG_ 1353 APP_buildType "Driver assistance computer (primary): build type";
CM_ BO_ 907 "Driver assistance computer (primary) message: rear park assist data";
CM_ SG_ 907 APP_rearLeftParkAssist "Driver assistance computer (primary): rear left park assist; raw 255 = signal not available (SNA)";
CM_ SG_ 907 APP_rearLeftMiddleParkAssist "Driver assistance computer (primary): rear left middle park assist; raw 255 = signal not available (SNA)";
CM_ SG_ 907 APP_rearMiddleParkAssist "Driver assistance computer (primary): rear middle park assist; raw 255 = signal not available (SNA)";
CM_ SG_ 907 APP_rearRightMiddleParkAssist "Driver assistance computer (primary): rear right middle park assist; raw 255 = signal not available (SNA)";
CM_ SG_ 907 APP_rearRightParkAssist "Driver assistance computer (primary): rear right park assist; raw 255 = signal not available (SNA)";
BA_DEF_ BO_ "GenMsgCycleTime" INT 0 3600000;
BA_DEF_ BO_ "GenMsgSendType" ENUM "Cyclic","NotUsed","NotUsed","NotUsed","NotUsed","NotUsed","NotUsed","IfActive","NoMsgSendType","NotUsed";
BA_DEF_ BO_ "VFrameFormat" ENUM "StandardCAN","ExtendedCAN","reserved","J1939PG","reserved","reserved","reserved","reserved","reserved","reserved","reserved","reserved","reserved","reserved","StandardCAN_FD","ExtendedCAN_FD";
BA_DEF_ BO_ "CANFD_BRS" ENUM "0","1";
BA_DEF_ SG_ "GenSigSNA" STRING;
BA_DEF_ SG_ "SystemSignalLongSymbol" STRING;
BA_DEF_ SG_ "Confidence" ENUM "validated","plausible","layout-only","contradicted";
BA_DEF_DEF_ "GenMsgCycleTime" 0;
BA_DEF_DEF_ "GenMsgSendType" "NoMsgSendType";
BA_DEF_DEF_ "VFrameFormat" "StandardCAN";
BA_DEF_DEF_ "CANFD_BRS" "1";
BA_DEF_DEF_ "GenSigSNA" "";
BA_DEF_DEF_ "SystemSignalLongSymbol" "";
BA_DEF_DEF_ "Confidence" "layout-only";
BA_ "GenMsgCycleTime" BO_ 1045 500;
BA_ "GenMsgSendType" BO_ 1045 0;
BA_ "GenMsgCycleTime" BO_ 1020 1000;
BA_ "GenMsgSendType" BO_ 1020 0;
BA_ "GenMsgCycleTime" BO_ 2046 1000;
BA_ "GenMsgSendType" BO_ 2046 0;
BA_ "GenMsgCycleTime" BO_ 1018 500;
BA_ "GenMsgSendType" BO_ 1018 0;
BA_ "GenMsgCycleTime" BO_ 1040 500;
BA_ "GenMsgSendType" BO_ 1040 0;
BA_ "GenMsgCycleTime" BO_ 1177 1000;
BA_ "GenMsgSendType" BO_ 1177 0;
BA_ "GenMsgCycleTime" BO_ 1043 500;
BA_ "GenMsgSendType" BO_ 1043 0;
BA_ "GenMsgCycleTime" BO_ 2045 1000;
BA_ "GenMsgSendType" BO_ 2045 0;
BA_ "GenMsgCycleTime" BO_ 939 500;
BA_ "GenMsgSendType" BO_ 939 0;
BA_ "GenMsgCycleTime" BO_ 603 1000;
BA_ "GenMsgSendType" BO_ 603 0;
BA_ "GenMsgCycleTime" BO_ 1061 1000;
BA_ "GenMsgSendType" BO_ 1061 0;
BA_ "GenMsgCycleTime" BO_ 843 100;
BA_ "GenMsgSendType" BO_ 843 0;
BA_ "GenMsgCycleTime" BO_ 1353 1000;
BA_ "GenMsgSendType" BO_ 1353 0;
BA_ "GenMsgCycleTime" BO_ 907 100;
BA_ "GenMsgSendType" BO_ 907 0;
BA_ "Confidence" SG_ 1513 APP_sw456_reason1 1;
BA_ "Confidence" SG_ 1513 APP_sw456_reason2 1;
BA_ "Confidence" SG_ 1513 APP_sw456_reason3 1;
BA_ "Confidence" SG_ 1513 APP_sw457_reason1 1;
BA_ "Confidence" SG_ 1513 APP_sw457_reason2 1;
BA_ "Confidence" SG_ 1513 APP_sw457_reason3 1;
BA_ "Confidence" SG_ 1513 APP_sw457_safeStateManeuver 1;
BA_ "Confidence" SG_ 1513 APP_sw458_fsdCollisionValue 1;
BA_ "Confidence" SG_ 1513 APP_sw458_aebCollisionValue 1;
BA_ "Confidence" SG_ 1513 APP_sw458_aebDurationAtAceOnset 1;
BA_ "Confidence" SG_ 1513 APP_sw458_targetDistance 1;
BA_ "Confidence" SG_ 1513 APP_sw458_targetRelativeSpeed 1;
BA_ "Confidence" SG_ 1513 APP_sw458_egoVehicleSpeed 1;
BA_ "Confidence" SG_ 1513 APP_sw461_rerouteRequest 1;
BA_ "Confidence" SG_ 1513 APP_sw461_rerouteReason 1;
BA_ "Confidence" SG_ 1513 APP_sw465_reason1 1;
BA_ "Confidence" SG_ 1513 APP_sw465_reason2 1;
BA_ "Confidence" SG_ 1513 APP_sw465_reason3 1;
BA_ "Confidence" SG_ 1513 APP_sw465_safeStateManeuver 1;
BA_ "Confidence" SG_ 1045 APP_backupDashCamFeedGood 0;
BA_ "Confidence" SG_ 1045 APP_backupDashCamFrameRate 0;
BA_ "Confidence" SG_ 1020 APP_decisionTemperature 0;
BA_ "Confidence" SG_ 1020 APP_pascalTemperature 0;
BA_ "Confidence" SG_ 1020 APP_parkerATemperature 0;
BA_ "Confidence" SG_ 1020 APP_parkerBTemperature 0;
BA_ "Confidence" SG_ 1020 APP_pascalExtTemperature 0;
BA_ "Confidence" SG_ 1020 APP_parkerExtTemperature 0;
BA_ "Confidence" SG_ 1020 APP_pascalHeaterDecision 0;
BA_ "Confidence" SG_ 2046 APP_cameraPosition 1;
BA_ "Confidence" SG_ 2046 APP_mainCamExtPitchCal 0;
BA_ "GenSigSNA" SG_ 2046 APP_mainCamExtPitchCal "511";
BA_ "Confidence" SG_ 2046 APP_mainCamExtYawCal 0;
BA_ "GenSigSNA" SG_ 2046 APP_mainCamExtYawCal "511";
BA_ "Confidence" SG_ 2046 APP_mainCalibTime 0;
BA_ "GenSigSNA" SG_ 2046 APP_mainCalibTime "127";
BA_ "Confidence" SG_ 2046 APP_mainCalibProgress 0;
BA_ "GenSigSNA" SG_ 2046 APP_mainCalibProgress "127";
BA_ "Confidence" SG_ 2046 APP_mainCalibrated 0;
BA_ "Confidence" SG_ 2046 APP_narrowCamExtPitchCal 0;
BA_ "GenSigSNA" SG_ 2046 APP_narrowCamExtPitchCal "511";
BA_ "Confidence" SG_ 2046 APP_narrowCamExtYawCal 0;
BA_ "GenSigSNA" SG_ 2046 APP_narrowCamExtYawCal "511";
BA_ "Confidence" SG_ 2046 APP_narrowCalibTime 0;
BA_ "GenSigSNA" SG_ 2046 APP_narrowCalibTime "127";
BA_ "Confidence" SG_ 2046 APP_narrowCalibProgress 0;
BA_ "GenSigSNA" SG_ 2046 APP_narrowCalibProgress "127";
BA_ "Confidence" SG_ 2046 APP_narrowCalibrated 0;
BA_ "Confidence" SG_ 2046 APP_fisheyeCamExtPitchCal 0;
BA_ "GenSigSNA" SG_ 2046 APP_fisheyeCamExtPitchCal "511";
BA_ "Confidence" SG_ 2046 APP_fisheyeCamExtYawCal 0;
BA_ "GenSigSNA" SG_ 2046 APP_fisheyeCamExtYawCal "511";
BA_ "Confidence" SG_ 2046 APP_fisheyeCalibTime 0;
BA_ "GenSigSNA" SG_ 2046 APP_fisheyeCalibTime "127";
BA_ "Confidence" SG_ 2046 APP_fisheyeCalibProgress 0;
BA_ "GenSigSNA" SG_ 2046 APP_fisheyeCalibProgress "127";
BA_ "Confidence" SG_ 2046 APP_fisheyeCalibrated 0;
BA_ "Confidence" SG_ 2046 APP_lPillarCamExtPitchCal 0;
BA_ "GenSigSNA" SG_ 2046 APP_lPillarCamExtPitchCal "511";
BA_ "Confidence" SG_ 2046 APP_lPillarCamExtYawCal 0;
BA_ "GenSigSNA" SG_ 2046 APP_lPillarCamExtYawCal "511";
BA_ "Confidence" SG_ 2046 APP_lPillarCalibTime 0;
BA_ "GenSigSNA" SG_ 2046 APP_lPillarCalibTime "127";
BA_ "Confidence" SG_ 2046 APP_lPillarCalibProgress 0;
BA_ "GenSigSNA" SG_ 2046 APP_lPillarCalibProgress "127";
BA_ "Confidence" SG_ 2046 APP_lPillarCalibrated 0;
BA_ "Confidence" SG_ 2046 APP_rPillarCamExtPitchCal 0;
BA_ "GenSigSNA" SG_ 2046 APP_rPillarCamExtPitchCal "511";
BA_ "Confidence" SG_ 2046 APP_rPillarCamExtYawCal 0;
BA_ "GenSigSNA" SG_ 2046 APP_rPillarCamExtYawCal "511";
BA_ "Confidence" SG_ 2046 APP_rPillarCalibTime 0;
BA_ "GenSigSNA" SG_ 2046 APP_rPillarCalibTime "127";
BA_ "Confidence" SG_ 2046 APP_rPillarCalibProgress 0;
BA_ "GenSigSNA" SG_ 2046 APP_rPillarCalibProgress "127";
BA_ "Confidence" SG_ 2046 APP_rPillarCalibrated 0;
BA_ "Confidence" SG_ 2046 APP_lRepeatCamExtPitchCal 0;
BA_ "GenSigSNA" SG_ 2046 APP_lRepeatCamExtPitchCal "511";
BA_ "Confidence" SG_ 2046 APP_lRepeatCamExtYawCal 0;
BA_ "GenSigSNA" SG_ 2046 APP_lRepeatCamExtYawCal "511";
BA_ "Confidence" SG_ 2046 APP_lRepeatCalibTime 0;
BA_ "GenSigSNA" SG_ 2046 APP_lRepeatCalibTime "127";
BA_ "Confidence" SG_ 2046 APP_lRepeatCalibProgress 0;
BA_ "GenSigSNA" SG_ 2046 APP_lRepeatCalibProgress "127";
BA_ "Confidence" SG_ 2046 APP_lRepeatCalibrated 0;
BA_ "Confidence" SG_ 2046 APP_rRepeatCamExtPitchCal 0;
BA_ "GenSigSNA" SG_ 2046 APP_rRepeatCamExtPitchCal "511";
BA_ "Confidence" SG_ 2046 APP_rRepeatCamExtYawCal 0;
BA_ "GenSigSNA" SG_ 2046 APP_rRepeatCamExtYawCal "511";
BA_ "Confidence" SG_ 2046 APP_rRepeatCalibTime 0;
BA_ "GenSigSNA" SG_ 2046 APP_rRepeatCalibTime "127";
BA_ "Confidence" SG_ 2046 APP_rRepeatCalibProgress 0;
BA_ "GenSigSNA" SG_ 2046 APP_rRepeatCalibProgress "127";
BA_ "Confidence" SG_ 2046 APP_rRepeatCalibrated 0;
BA_ "Confidence" SG_ 2046 APP_backupCamExtPitchCal 0;
BA_ "GenSigSNA" SG_ 2046 APP_backupCamExtPitchCal "511";
BA_ "Confidence" SG_ 2046 APP_backupCamExtYawCal 0;
BA_ "GenSigSNA" SG_ 2046 APP_backupCamExtYawCal "511";
BA_ "Confidence" SG_ 2046 APP_backupCalibTime 0;
BA_ "GenSigSNA" SG_ 2046 APP_backupCalibTime "127";
BA_ "Confidence" SG_ 2046 APP_backupCalibProgress 0;
BA_ "GenSigSNA" SG_ 2046 APP_backupCalibProgress "127";
BA_ "Confidence" SG_ 2046 APP_backupCalibrated 0;
BA_ "Confidence" SG_ 2046 APP_fasciaCamExtPitchCal 0;
BA_ "GenSigSNA" SG_ 2046 APP_fasciaCamExtPitchCal "511";
BA_ "Confidence" SG_ 2046 APP_fasciaCamExtYawCal 0;
BA_ "GenSigSNA" SG_ 2046 APP_fasciaCamExtYawCal "511";
BA_ "Confidence" SG_ 2046 APP_fasciaCalibTime 0;
BA_ "GenSigSNA" SG_ 2046 APP_fasciaCalibTime "127";
BA_ "Confidence" SG_ 2046 APP_fasciaCalibProgress 0;
BA_ "GenSigSNA" SG_ 2046 APP_fasciaCalibProgress "127";
BA_ "Confidence" SG_ 2046 APP_fasciaCalibrated 0;
BA_ "Confidence" SG_ 1018 APP_mainCameraLUX 0;
BA_ "GenSigSNA" SG_ 1018 APP_mainCameraLUX "255";
BA_ "Confidence" SG_ 1018 APP_narrowCameraLUX 0;
BA_ "GenSigSNA" SG_ 1018 APP_narrowCameraLUX "255";
BA_ "Confidence" SG_ 1018 APP_fisheyeCameraLUX 0;
BA_ "GenSigSNA" SG_ 1018 APP_fisheyeCameraLUX "255";
BA_ "Confidence" SG_ 1018 APP_lRepeatCameraLUX 0;
BA_ "GenSigSNA" SG_ 1018 APP_lRepeatCameraLUX "255";
BA_ "Confidence" SG_ 1018 APP_rRepeatCameraLUX 0;
BA_ "GenSigSNA" SG_ 1018 APP_rRepeatCameraLUX "255";
BA_ "Confidence" SG_ 1018 APP_lPillarCameraLUX 0;
BA_ "GenSigSNA" SG_ 1018 APP_lPillarCameraLUX "255";
BA_ "Confidence" SG_ 1018 APP_rPillarCameraLUX 0;
BA_ "GenSigSNA" SG_ 1018 APP_rPillarCameraLUX "255";
BA_ "Confidence" SG_ 1018 APP_backupCameraLUX 0;
BA_ "GenSigSNA" SG_ 1018 APP_backupCameraLUX "255";
BA_ "Confidence" SG_ 1040 APP_backupCameraFeedGood 0;
BA_ "Confidence" SG_ 1040 APP_backupCameraFrameRate 0;
BA_ "Confidence" SG_ 1040 APP_cameraBlockedFrontMain 0;
BA_ "Confidence" SG_ 1040 APP_cameraBlockedFrontFisheye 0;
BA_ "Confidence" SG_ 1040 APP_cameraBlockedFrontNarrow 0;
BA_ "Confidence" SG_ 1040 APP_cameraBlockedLeftPillar 0;
BA_ "Confidence" SG_ 1040 APP_cameraBlockedLeftRepeater 0;
BA_ "Confidence" SG_ 1040 APP_cameraBlockedRightPillar 0;
BA_ "Confidence" SG_ 1040 APP_cameraBlockedRightRepeater 0;
BA_ "Confidence" SG_ 1040 APP_cameraBlockedBackup 0;
BA_ "Confidence" SG_ 1040 APP_fasciaCameraTemperature 0;
BA_ "GenSigSNA" SG_ 1040 APP_fasciaCameraTemperature "255";
BA_ "Confidence" SG_ 1177 APP_rRepeaterCameraTemperature 1;
BA_ "Confidence" SG_ 1177 APP_lRepeaterCameraTemperature 1;
BA_ "Confidence" SG_ 1043 APP_mainDashCamFeedGood 0;
BA_ "Confidence" SG_ 1043 APP_mainDashCamFrameRate 0;
BA_ "Confidence" SG_ 1043 APP_lRepeatDashCamFeedGood 0;
BA_ "Confidence" SG_ 1043 APP_lRepeatDashCamFrameRate 0;
BA_ "Confidence" SG_ 1043 APP_rRepeatDashCamFeedGood 0;
BA_ "Confidence" SG_ 1043 APP_rRepeatDashCamFrameRate 0;
BA_ "Confidence" SG_ 2045 APP_cameraDefogMode 0;
BA_ "GenSigSNA" SG_ 2045 APP_cameraDefogMode "0";
BA_ "Confidence" SG_ 2045 APP_selfieCamFanRpm 0;
BA_ "GenSigSNA" SG_ 2045 APP_selfieCamFanRpm "65535";
BA_ "Confidence" SG_ 2045 APP_forceDefroster 0;
BA_ "GenSigSNA" SG_ 2045 APP_forceDefroster "0";
BA_ "Confidence" SG_ 2045 APP_checkThermalSysHealth 0;
BA_ "GenSigSNA" SG_ 2045 APP_checkThermalSysHealth "0";
BA_ "Confidence" SG_ 2045 APP_defogInfoMessageChecksum 0;
BA_ "Confidence" SG_ 2045 APP_hvacRequest 0;
BA_ "GenSigSNA" SG_ 2045 APP_hvacRequest "0";
BA_ "Confidence" SG_ 939 APP_cabinCamTelemetryOn 0;
BA_ "Confidence" SG_ 939 APP_attnMonitorVersion 0;
BA_ "GenSigSNA" SG_ 939 APP_attnMonitorVersion "7";
BA_ "Confidence" SG_ 939 APP_attnBasedDriverMonitorOn 0;
BA_ "Confidence" SG_ 939 APP_handsOnDetected 0;
BA_ "Confidence" SG_ 939 APP_handsOnDetectedSource 0;
BA_ "GenSigSNA" SG_ 939 APP_handsOnDetectedSource "7";
BA_ "Confidence" SG_ 939 APP_cabinCamBlinded 0;
BA_ "Confidence" SG_ 939 APP_cabinCamDark 0;
BA_ "Confidence" SG_ 939 APP_driverStateUnknown 0;
BA_ "Confidence" SG_ 939 APP_driverNotLively 0;
BA_ "Confidence" SG_ 939 APP_driverStateUnknownHyst 0;
BA_ "Confidence" SG_ 939 APP_driverLowNominal 0;
BA_ "Confidence" SG_ 939 APP_driverHeadCappedHyst 0;
BA_ "Confidence" SG_ 939 APP_driverSunglassesUseHyst 0;
BA_ "Confidence" SG_ 939 APP_cabinLowLux 0;
BA_ "Confidence" SG_ 939 APP_cabinCamInconsistent 0;
BA_ "Confidence" SG_ 939 APP_driverLeaningBack 0;
BA_ "Confidence" SG_ 939 APP_driverLowEyeVisibility 0;
BA_ "Confidence" SG_ 939 APP_driverHandsNotReady 0;
BA_ "Confidence" SG_ 939 APP_driverSeatUnoccupied 0;
BA_ "Confidence" SG_ 939 APP_handsOnInputRequired 0;
BA_ "Confidence" SG_ 939 APP_cabinCamDarkHyst 0;
BA_ "Confidence" SG_ 939 APP_cabinLowLuxHyst 0;
BA_ "Confidence" SG_ 939 APP_ADDWSystemStatus 0;
BA_ "Confidence" SG_ 939 APP_dmStrictness 0;
BA_ "GenSigSNA" SG_ 939 APP_dmStrictness "0";
BA_ "Confidence" SG_ 939 APP_dmStrictnessReason 0;
BA_ "GenSigSNA" SG_ 939 APP_dmStrictnessReason "0";
BA_ "Confidence" SG_ 603 APP_environmentRainy 0;
BA_ "Confidence" SG_ 603 APP_environmentSnowy 0;
BA_ "Confidence" SG_ 603 APP_offgassingSeverity 0;
BA_ "GenSigSNA" SG_ 603 APP_offgassingSeverity "0";
BA_ "Confidence" SG_ 603 APP_offgassingDetectionState 0;
BA_ "GenSigSNA" SG_ 603 APP_offgassingDetectionState "0";
BA_ "Confidence" SG_ 603 APP_offgassingAlertEnabled 0;
BA_ "Confidence" SG_ 603 APP_offgassingMaxProbabilityLong 0;
BA_ "GenSigSNA" SG_ 603 APP_offgassingMaxProbabilityLong "0";
BA_ "Confidence" SG_ 603 APP_offgassingMaxProbabilityShor 0;
BA_ "GenSigSNA" SG_ 603 APP_offgassingMaxProbabilityShor "0";
BA_ "SystemSignalLongSymbol" SG_ 603 APP_offgassingMaxProbabilityShor "APP_offgassingMaxProbabilityShort";
BA_ "Confidence" SG_ 603 APP_offgassingLongMaxCamera 0;
BA_ "GenSigSNA" SG_ 603 APP_offgassingLongMaxCamera "0";
BA_ "Confidence" SG_ 603 APP_offgassingShortMaxCamera 0;
BA_ "GenSigSNA" SG_ 603 APP_offgassingShortMaxCamera "0";
BA_ "Confidence" SG_ 603 APP_offgassingLongMaxDetector 0;
BA_ "GenSigSNA" SG_ 603 APP_offgassingLongMaxDetector "0";
BA_ "Confidence" SG_ 603 APP_offgassingShortMaxDetector 0;
BA_ "GenSigSNA" SG_ 603 APP_offgassingShortMaxDetector "0";
BA_ "Confidence" SG_ 1061 APP_factoryGoalLatitude 0;
BA_ "Confidence" SG_ 1061 APP_factoryGoalLongitude 0;
BA_ "Confidence" SG_ 1061 APP_factoryGoalSpeed 0;
BA_ "Confidence" SG_ 843 APP_frontLeftParkAssist 0;
BA_ "GenSigSNA" SG_ 843 APP_frontLeftParkAssist "255";
BA_ "Confidence" SG_ 843 APP_frontLeftMiddleParkAssist 0;
BA_ "GenSigSNA" SG_ 843 APP_frontLeftMiddleParkAssist "255";
BA_ "Confidence" SG_ 843 APP_frontMiddleParkAssist 0;
BA_ "GenSigSNA" SG_ 843 APP_frontMiddleParkAssist "255";
BA_ "Confidence" SG_ 843 APP_frontRightMiddleParkAssist 0;
BA_ "GenSigSNA" SG_ 843 APP_frontRightMiddleParkAssist "255";
BA_ "Confidence" SG_ 843 APP_frontRightParkAssist 0;
BA_ "GenSigSNA" SG_ 843 APP_frontRightParkAssist "255";
BA_ "Confidence" SG_ 843 APP_parkAssistStatus 0;
BA_ "GenSigSNA" SG_ 843 APP_parkAssistStatus "3";
BA_ "Confidence" SG_ 843 APP_useParkDistancesFromAP 0;
BA_ "Confidence" SG_ 1353 APP_infoIndex 1;
BA_ "Confidence" SG_ 1353 APP_buildType 0;
BA_ "Confidence" SG_ 907 APP_rearLeftParkAssist 0;
BA_ "GenSigSNA" SG_ 907 APP_rearLeftParkAssist "255";
BA_ "Confidence" SG_ 907 APP_rearLeftMiddleParkAssist 0;
BA_ "GenSigSNA" SG_ 907 APP_rearLeftMiddleParkAssist "255";
BA_ "Confidence" SG_ 907 APP_rearMiddleParkAssist 0;
BA_ "GenSigSNA" SG_ 907 APP_rearMiddleParkAssist "255";
BA_ "Confidence" SG_ 907 APP_rearRightMiddleParkAssist 0;
BA_ "GenSigSNA" SG_ 907 APP_rearRightMiddleParkAssist "255";
BA_ "Confidence" SG_ 907 APP_rearRightParkAssist 0;
BA_ "GenSigSNA" SG_ 907 APP_rearRightParkAssist "255";
VAL_ 1513 APP_sw456_reason1 414 "TRAJECTORY_ON_PUBLIC_ROAD_NOT_INDOORS" 413 "STOP_IN_LANE_NOT_HONORED" 412 "SIMPLE_SUMMON_OBSTACLE_BLOCKED" 411 "SEVERE_SINGLE_FRONT_VISION_OCCLUSION_AFTER_WIPE" 410 "PHONE_TOO_FAR_TO_START" 409 "MAX_SPEED_LIMIT_FOR_MODE_EXCEEDED" 408 "EPB_REDUNDANT_BRAKING_UNAVAILABLE" 407 "EGO_GEAR_NOT_ALLOWED" 406 "EGO_EXCEEDED_MAX_SUMMON_DISTANCE" 405 "DUAL_EPB_UNAVAILABLE" 404 "COMPRESSOR_FRAME_DROP_RATE_HIGH" 403 "CAN_RX_VALIDATION_ERROR" 402 "BRAKE_APPLIED_PARKED" 401 "ALARM_ACTIVE" 400 "SAFETY_DRIVER_UNBUCKLED_PRE_ACTIVATION" 399 "NOT_FACTORY_SCHEDULE" 398 "FSD_REGION_NOT_ALLOWED" 397 "FSD_QUIZ_REQUIRED" 396 "EPAS_EAC_NOT_ACTIVE_OTHER" 395 "EPAS_EAC_NOT_ACTIVE_HANDS_ON" 394 "DI_CONTROL_INTEGRATOR_WINDUP" 393 "SEVERE_SINGLE_FRONT_VISION_OCCLUSION_HIGH_FOGGING_RISK" 392 "EGO_NEAR_SUMMON_MAP_BOUNDARY_NOT_INDOORS" 391 "GOAL_NEAR_SUMMON_MAP_BOUNDARY_NOT_INDOORS" 390 "GRADE_TOO_HIGH_WITHOUT_REDUNDANT_BRAKING_LOW_MU" 389 "NAV_DESTINATION_OUTSIDE_GEOFENCE" 388 "RCM_COLLISION_SEVERITY_TRIGGERED" 387 "EPB_PARKING_AVAILABILITY_TOO_STEEP" 386 "REVERSE_GEAR_NOT_AVAILABLE" 385 "DESTINATION_OUTSIDE_GEOFENCE_AP" 384 "SSD_CLIP_LOGGING_CRITICAL" 383 "DRIVE_GEAR_NOT_AVAILABLE" 382 "SIDE_VISIBILITY_DEGRADED_PARKED_DOORS_CLOSED" 381 "PERSISTENT_FRAME_DROPS" 380 "PERSISTENT_HANDS_ON_NOT_ALLOWED" 379 "NAV_ROUTE_EXCEEDS_GEOFENCE_BUFFER" 378 "RANKER_OUTPUT_STALE" 377 "VISION_PLANNER_STALE" 376 "AUTO_WIPERS_OFF" 375 "COUNTRY_NOT_ALLOWED_FOR_OPERATION" 374 "OUTSIDE_TRACK_TEST_GEOFENCE" 373 "TEMPERATURE_EXCEEDS_ODD" 372 "RIDESHARE_NAV_GOAL_NOT_IN_SYNC" 371 "HV_BATTERY_AC_CHARGING_UNHEALTHY" 370 "HV_BATTERY_DC_CHARGING_UNHEALTHY" 369 "UI_RIDE_SETUP_IN_PROGRESS" 368 "AUTO_HEADLIGHTS_OFF" 367 "IMMOBILIZER_AUTH_AUTONOMY" 366 "DI_RESTRICTED_DRIVING_MANUAL_RECOVERY" 365 "SUMMON_ACTIVE_DURATION_EXCEEDED" 364 "ESKF_SPEED_SOURCE_ACTIVE" 363 "IMU_DATA_NOT_RELIABLE_WITH_FLEET_CONFIG_ENABLED" 362 "FASCIA_VISION_OCCLUSION_AT_LONG_STOP" 361 "HIGH_SPEED_ROAD_ON_ROUTE" 360 "EGO_ON_HIGH_SPEED_ROAD" 359 "UNACCOMPANIED_UNDERAGE_RIDER_DETECTED" 358 "AEB_FAULTED" 357 "AUDIO_HARDWARE_ODIN_FAILED" 356 "FASCIA_VISION_FAILSAFE_PARKED" 355 "APS_B_EPLANNER_NO_VALID_TRAJECTORY" 354 "APS_A_EPLANNER_NO_VALID_TRAJECTORY" 353 "FASCIA_CAM_INTEGRATED_HEATER_FAULT" 352 "BACKUP_CAM_INTEGRATED_HEATER_FAULT" 351 "RIGHT_REPEATER_CAM_INTEGRATED_HEATER_FAULT" 350 "LEFT_REPEATER_CAM_INTEGRATED_HEATER_FAULT" 349 "RIGHT_PILLAR_CAM_INTEGRATED_HEATER_FAULT" 348 "LEFT_PILLAR_CAM_INTEGRATED_HEATER_FAULT" 347 "RIGHT_PILLAR_CAM_WIRE_HEATER_FAULT" 346 "LEFT_PILLAR_CAM_WIRE_HEATER_FAULT" 345 "WINDSHIELD_CAM_WIRE_HEATER_FAULT" 344 "CONTROLLER_EPLANNER_UNHEALTHY" 343 "VEHICLE_COLLISION_DETECTED" 342 "VRU_COLLISION_DETECTED" 341 "MAJOR_COLLISION_DETECTED" 340 "ONGOING_COLLISION_DETECTED" 339 "INTEGRATOR_ACCELERATION_INVALID" 338 "CABIN_CAM_DRIVER_MONITORING_SYSTEM_UNAVAILABLE" 337 "DCAS_DRIVER_ATTENTION_STATE_DETERMINATION_DEGRADED" 336 "NON_MAIN_FRONT_CAMERAS_STREAM_LOST" 335 "MAIN_CAMERA_STREAM_LOST" 334 "DRIVER_WIPER_WASH_HEALTH_DEGRADED" 333 "EPB_AUTONOMY_BEHAVIOR_MISMATCH" 332 "DI_AUTONOMY_BEHAVIOR_MISMATCH" 331 "VC_AUTONOMY_BEHAVIOR_MISMATCH" 330 "DCAS_EXITED_REGION_TIMEOUT" 329 "WASHER_PUMP_NOT_HEALTHY" 328 "AP_B_SOC_UNHEALTHY" 327 "RCM_AIR_BAG_DEPLOY" 326 "RCM_NEAR_DEPLOY" 325 "AP_A_SOC_UNHEALTHY" 324 "ROUTE_EXCEEDS_SPEED_LIMIT" 323 "PERSISTENT_INVALID_NAV_ROUTE" 322 "NAV_ROUTE_EXITS_GEOFENCE" 321 "NAV_AVOID_HIGH_SPEED_ROADS_DISABLED" 320 "NAV_WHITELIST_ROUTING_DISABLED" 319 "NAV_ROUTE_RANKER_DISABLED" 318 "NAV_AVOID_SHORT_LANE_CHANGE_DISABLED" 317 "NAV_AVOID_UNPROTECTED_TURN_DISABLED" 316 "HIGHWAY_ON_ROUTE" 315 "EGO_ON_HIGHWAY" 314 "INVALID_VEHICLE_OPERATION_MODE" 313 "STEERING_ANGLE_OFFSET_HIGH" 312 "SAFETY_DRIVER_INATTENTIVE" 311 "TRACK_MODE_ACTIVE" 310 "EXT_TEMP_LOW_CERAMIC_BRAKES" 309 "GOAL_NEAR_SUMMON_MAP_BOUNDARY" 308 "SUMMON_HEARTBEAT_MISSING" 307 "EGO_NEAR_SUMMON_MAP_BOUNDARY" 306 "EGO_OUTSIDE_SUMMON_MAP_RADIUS" 305 "SUMMON_MAP_INVALID" 304 "RAW_UI_SUMMON_GOAL_INVALID" 303 "SUMMON_GOAL_INVALID" 302 "SYSTEM_CDP_UNAVAILABLE" 301 "SUMMON_COLLISION_DETECTION_ACTIVE" 300 "PHONE_TOO_FAR" 299 "PHONE_GPS_INVALID" 298 "GRADE_TOO_HIGH_WITHOUT_REDUNDANT_BRAKING" 297 "CABIN_CAM_DRIVER_MONITORING_UNAVAILABLE" 296 "CABIN_CAMERA_STREAM_FAILURE" 295 "DRIVER_PRESENCE_VISION_UNAVAILABLE" 294 "PEDAL_OVERRIDE_EXCEEDS_CONTROLLER_LIMITS" 293 "UPCOMING_FERRY_CROSSING" 292 "DRIVER_PARTIALLY_OCCLUDED" 291 "DRIVER_REQUIREMENTS_NOT_MET_VC" 290 "DRIVER_AGE_REQUIREMENTS_NOT_MET_VISION" 289 "GPS_DEGRADED" 288 "PILLARS_SWAP_DETECTED" 287 "NARROW_FISHEYE_SWAP_DETECTED" 286 "SCCM_MIA" 285 "RECENT_STALK_GEAR_SHIFT" 284 "IBOOSTER_MIA" 283 "PARKING_SPOT_SELECTED" 282 "SCROLL_WHEEL_INTERACTION" 281 "PEDAL_OVERRIDE_STRIKEOUT_FOR_DRIVE" 280 "PEDAL_OVERRIDE_STRIKEOUT" 279 "ABOVE_MAX_ACTIVATION_SPEED" 278 "DRIVER_MONITOR_SUSPENSION_ACTIVE" 277 "DRIVER_MONITOR_STRUCK_OUT_FOR_DRIVE" 276 "VC_CAMERA_AIR_CLEANING_STATUS_MIA" 275 "VC_CAMERA_FLUID_CLEANING_STATUS_MIA" 274 "INVALID_DI_PEDAL_POS" 273 "CABIN_CAMERA_FAN_RPM_FAULT" 272 "SELF_NETWORK_DECRYPTION_NOT_READY" 271 "OFF_ROAD_MODE_ACTIVE" 270 "SSD_CLIP_LOGGING_INACTIVE" 269 "CAMERA_EXPOSURE_INACTIVE" 268 "CAMERA_EXPOSURE_MISMATCH" 267 "CABIN_CAMERA_IR_LED_FAULTED" 266 "TAMPERING_DETECTED" 265 "NO_IMU_SOURCES_AVAILABLE" 264 "IMU_REDUNDANCY_LOST" 263 "DI_AUTONOMY_HEALTH_CAN_MESSAGE_MIA" 262 "ALL_WHEEL_SPEEDS_SENSORS_FAULTED" 261 "WHEEL_SPEEDS_CAN_MESSAGE_MIA" 260 "AP_THERMAL_MODEL_FAULT_DETECTED" 259 "SGK_AUTONOMY_MODE_NOT_IN_SYNC" 258 "SGK_AUTONOMY_STATE_NOT_IN_SYNC" 257 "ANY_RIGHT_DOOR_OPEN_BUTTON_FAULTED" 256 "ANY_LEFT_DOOR_OPEN_BUTTON_FAULTED" 255 "VCRIGHT_DOOR_STATUS_CAN_MESSAGE_MIA" 254 "VCLEFT_DOOR_STATUS_CAN_MESSAGE_MIA" 253 "BB_STATUS_CAN_MESSAGE_MIA" 252 "GTW_CAR_CONFIG_CAN_MESSAGE_MIA" 251 "TRAILER_MODE_ACTIVE" 250 "UI_LIMIT_MODE_ACTIVE" 249 "UI_QT_CAR_UNAVAILABLE" 248 "UI_CONNECTIVITY_HW_UNHEALTHY" 247 "UI_CONNECTIVITY_OFFLINE" 246 "UI_CENTER_DISPLAY_UNAVAILABLE" 245 "UI_HEALTH_STATUS_CAN_MESSAGE_MIA" 244 "ANY_LV_HEALTH_CAN_MESSAGE_INVALID" 243 "ANY_LV_HEALTH_CAN_MESSAGE_MIA" 242 "AP_SYSTEM_ISSUE_PENDING_REBOOT" 241 "AP_TASK_PENDING_REBOOT" 240 "APS_DUAL_CAMERA_POWER_FAILURE" 239 "APS_SINGLE_CAMERA_POWER_FAILURE" 238 "APS_ETH_BRIDGE_DOWN" 237 "APS_PEER_PMIC_FAULTED" 236 "APS_SELF_PMIC_FAULTED" 235 "APS_PEER_VRM_FAULTED" 234 "APS_SELF_VRM_FAULTED" 233 "APS_PEER_IMEM_FAULTED" 232 "APS_SELF_IMEM_FAULTED" 231 "APS_PEER_CAN_FAULTED" 230 "APS_SELF_CAN_FAULTED" 229 "APS_B_UNHEALTHY" 228 "APS_A_UNHEALTHY" 227 "PEER_VISION_FAILOVER_ACTIVE" 226 "ARBITER_SELECTED_BEHAVIOR_OUT_OF_DATE" 225 "ARBITER_SELECTED_BEHAVIOR_NOT_E2E" 224 "MISSION_PLANNER_DESIRED_BEHAVIOR_NOT_E2E" 223 "AUTONOMY_CONTROLLING_AND_NOT_PARKED" 222 "NO_VALID_SGK_STATUS" 221 "AUTONOMOUS_BEHAVIORS_LINK_NOT_ESTABLISHED" 220 "GNSS_PPS_MIA" 219 "GNSS_ANTENNA_DISCONNECTED" 218 "GNSS_UART_FAULTED" 217 "AP_THERMAL_DEGRADED_PULLOVER_REQ" 216 "AP_THERMAL_DEGRADED_BLOCK_ACTIVATION" 215 "DRIVER_PRESENT_NOT_ALLOWED" 214 "UNSUPERVISED_OPERATION_NOT_ALLOWED" 213 "NOT_IN_RT_NO_TAKEOVER_FLEET" 212 "SAFETY_OPERATOR_NOT_PRESENT" 211 "CAMERA_PRECONDITIONING_REQUIRED" 210 "BMS_CAN_MESSAGES_MIA" 209 "VEHICLE_LOSING_HV" 208 "HV_DRIVE_NO_RESTART" 207 "AUTONOMOUS_BEHAVIORS_TASK_SUSPENDING" 206 "AUDIO_BUS_DOWN" 205 "CAMERA_REDUNDANCY_NOT_READY" 204 "NO_VEHICLE_SPEED_SOURCE_AVAILABLE" 203 "DI_PRIMARY_SPEED_SOURCE_UNAVAILABLE" 202 "DI_SPEED_CAN_MESSAGE_MIA" 201 "DEFOG_SYSTEM_UNHEALTHY" 200 "COOLANT_SYSTEM_UNHEALTHY" 199 "DEFOG_SYSTEM_NOT_READY" 198 "COOLANT_SYSTEM_NOT_READY" 197 "NOT_AUTHENTICATED_FOR_DRIVE" 196 "UNASSIGNED_PASSENGER_UNBUCKLED" 195 "WAITING_FOR_PASSENGER_EGRESS" 194 "PASSENGER_UNEXPECTED_RIDE_INACTIVE" 193 "DRIVER_NOT_PRESENT_PRE_ACTIVATION" 192 "NARROW_WASH_NOT_AVAILABLE" 191 "REDUNDANT_IMU_CAN_MESSAGES_MIA" 190 "IMU_CAN_MESSAGES_MIA" 189 "BRAKING_CAN_MESSAGES_MIA" 188 "EPB_AUTONOMY_CAN_MESSAGES_MIA" 187 "PARK_BRAKE_CAN_MESSAGES_MIA" 186 "STEERING_CAN_MESSAGES_MIA" 185 "DI_SYSTEM_STATUS_CAN_MESSAGES_MIA" 184 "DI_CHASSIS_CONTROL_CAN_MESSAGE_MIA" 183 "APS_CAN_MESSAGES_MIA" 182 "POOR_LOCALIZATION_ACCURACY" 181 "VISION_FAILOVER_ACTIVE" 180 "SEAT_OCCUPANCY_STATUS_UNHEALTHY" 179 "TO_STREAMS_UNHEALTHY" 178 "SEATBELT_STATUS_UNHEALTHY" 177 "RCM_WARNING_INDICATOR_ON" 176 "REDUNDANT_BRAKES_FAIL_OPERATIONAL" 175 "REDUNDANT_BRAKES_REDUNDANCY_LOST" 174 "REDUNDANT_BRAKES_NOT_ARMED" 173 "REDUNDANT_BRAKES_NOT_READY" 172 "REDUNDANT_BRAKE_PATH_ACTIVE" 171 "RANKER_NOT_HEALTHY" 170 "PARKED_A_PEDAL_PRESSED" 169 "ANY_CANCEL_ACTIVE" 168 "BRAKE_CONFIRM_PENDING_PARK" 167 "BRAKE_APPLIED_D_R_N" 166 "BRAKE_RELEASE_PENDING_PARK" 165 "ENFORCED_UNPARK_DELAY_ACTIVE" 164 "WIPER_NOT_HEALTHY" 163 "RIGHT_PILLAR_CAM_HEATER_FAULT" 162 "LEFT_PILLAR_CAM_HEATER_FAULT" 161 "WINDSHIELD_CAM_HEATER_FAULT" 160 "ALL_TAIL_LIGHTS_FAULTED_IN_LOW_VIS" 159 "TAIL_LIGHT_FAULTED" 158 "REVERSE_LIGHT_FAULTED" 157 "RIGHT_TURN_LIGHT_FAULTED" 156 "LEFT_TURN_LIGHT_FAULTED" 155 "ALL_BRAKE_LIGHTS_FAULTED" 154 "BRAKE_LIGHT_FAULTED" 153 "HIGH_BEAM_LIGHT_FAULTED_IN_LOW_VIS" 152 "LOW_BEAM_LIGHT_FAULTED_IN_LOW_VIS" 151 "HIGH_BEAM_LIGHT_FAULTED" 150 "LOW_BEAM_LIGHT_FAULTED" 149 "HEADLIGHTS_NOT_AIMED" 148 "HEADLIGHTS_OFF_AT_NIGHT" 147 "AP_REDUNDANCY_UNAVAILABLE" 146 "DI_BRAKING_DECELERATION_UNAVAILABLE" 145 "DI_VDC_ACTIVE" 144 "DI_TC_ACTIVE" 143 "DI_VDC_STATE_NOT_NORMAL" 142 "DI_LOSING_PROPULSION" 141 "EPB_STATUS_NOT_PARKED" 140 "EPB_PARKING_AVAILABILITY_UNKNOWN" 139 "EPB_PARKING_AVAILABILITY_REQUEST_PATH_DEGRADED" 138 "EPB_PARKING_AVAILABILITY_SPEED_INVALID" 137 "EPB_PARKING_AVAILABILITY_FAULTED" 136 "TIRE_PRESSURE_SENSOR_FAULT" 135 "FLAT_TIRE" 134 "INTEGRATOR_HEALTH_CRITICAL" 133 "IMU_DATA_NOT_RELIABLE" 132 "FASCIA_FLUID_CLEAN_CRITICAL" 131 "BACKUP_FLUID_CLEAN_CRITICAL" 130 "RIGHT_REPEATER_FLUID_CLEAN_CRITICAL" 129 "LEFT_REPEATER_FLUID_CLEAN_CRITICAL" 128 "FASCIA_AIR_CLEAN_CRITICAL" 127 "BACKUP_AIR_CLEAN_CRITICAL" 126 "RIGHT_REPEATER_AIR_CLEAN_CRITICAL" 125 "LEFT_REPEATER_AIR_CLEAN_CRITICAL" 124 "FASCIA_FLUID_CLEAN_DEGRADED" 123 "BACKUP_FLUID_CLEAN_DEGRADED" 122 "RIGHT_REPEATER_FLUID_CLEAN_DEGRADED" 121 "LEFT_REPEATER_FLUID_CLEAN_DEGRADED" 120 "FASCIA_AIR_CLEAN_DEGRADED" 119 "BACKUP_AIR_CLEAN_DEGRADED" 118 "RIGHT_REPEATER_AIR_CLEAN_DEGRADED" 117 "LEFT_REPEATER_AIR_CLEAN_DEGRADED" 116 "TERTIARY_WASHER_FLUID_LOW" 115 "SECONDARY_WASHER_FLUID_LOW" 114 "WASHER_FLUID_LOW" 113 "ELEVATED_TIRE_PRESSURE_READING" 112 "LOW_TIRE_PRESSURE_READING" 111 "VISION_CABIN_OCCUPANCY_UNAVAILABLE" 110 "SGK_AUTOSTEER_MONITOR_ACTIVE" 109 "SGK_PLANNER_ACTIVE_D_R_N" 108 "FLEET_MAINTENANCE_EXPIRING_SOON" 107 "FLEET_MAINTENANCE_REQUIRED" 106 "CHARGE_CABLE_CONNECTED_OR_STATUS_UNKNOWN" 105 "PASSENGER_UNBUCKLED_ACTIVE_RIDE" 104 "PASSENGER_UNBUCKLED" 103 "SYSTEM_UNHEALTHY_DEV_OVERRIDE" 102 "SINGLE_SOC_HEALTHY_EXCEPTION" 101 "IMU_REPLICATION_NOT_READY" 100 "STATE_MACHINE_DISABLED" 99 "INCOMPATIBLE_SYSTEM_HEALTH" 98 "CABIN_CAM_BLINDED" 97 "RIDESHARE_INGRESS_NO_NAV_ROUTE" 96 "PASSENGER_EXPECTED" 95 "DRIVER_MONITOR_STRIKEOUT" 94 "DRIVER_NOT_PRESENT" 93 "CONTROLLER_SOLVER_CRITICAL" 92 "CONTROLLER_SOLVER_DEGRADED" 91 "CONTROLLER_DEGRADED_PEDAL_OVERRIDE" 90 "CONTROLLER_SOLVER_FAILURE" 89 "LV_CRITICAL_STATE" 88 "LV_DEGRADED_STATE" 87 "VEHICLE_AUTONOMY_BEHAVIOR_MISMATCH" 86 "CRUISE_STACK_MISMATCH" 85 "EPB_REDUNDANT_BRAKING_STATUS" 84 "EXTENDED_COMPUTE_INACTIVE_OTHER" 83 "EXTENDED_COMPUTE_TIME_SYNC_CRITICAL_DEGRADED" 82 "EXTENDED_COMPUTE_OTHER_SOC_STATE_UNKNOWN" 81 "EXTENDED_COMPUTE_OTHER_SOC_STATE_INACTIVE" 80 "EXTENDED_COMPUTE_PCIE_LINK_HEALTH" 79 "EXTENDED_COMPUTE_ETHERNET_LINK_HEALTH" 78 "EXTENDED_COMPUTE_OTHER_SOC_HEALTH_CRITICAL" 77 "EXTENDED_COMPUTE_OTHER_SOC_HEALTH_UNKNOWN" 76 "EXTENDED_COMPUTE_SOC_HEALTH_CRITICAL" 75 "EXTENDED_COMPUTE_SOC_HEALTH_UNKNOWN" 74 "FSD_FROM_PARK_DISABLED" 73 "NOT_IN_PARK_NO_TAKEOVER" 72 "NO_FIXED_ROUTE" 71 "NAV_GOAL_INVALID" 70 "ANY_EPAS_FAULT" 69 "EPAS_SYSTEM_TORQUE_REDUCED" 68 "EPAS_SECONDARY_MASTER" 67 "EPAS_REDUNDANCY_LOST" 66 "EPAS_DRIVERLESS_MODE_NOT_ACTIVE" 65 "EPAS_EAC_NOT_ACTIVE" 64 "EPAS_EAC_UNAVAILABLE" 63 "STEERING_ANGLE_INVALID" 62 "CRUISE_FAULT" 61 "CRUISE_NOT_ACTIVE_OTHER" 60 "CRUISE_NOT_ACTIVE_ESTOP" 59 "CRUISE_UNAVAILABLE_OTHER" 58 "CRUISE_UNAVAILABLE_BRAKE_APPLIED" 57 "NOT_POWER_STATE_DRIVE" 56 "FRUNK_OPEN" 55 "TRUNK_OPEN" 54 "PASSENGER_DOOR_OPEN" 53 "DRIVER_DOOR_OPEN" 52 "VISION_FPS_LOW_CAMERA_DROPS" 51 "VISION_LATENCY_HIGH" 50 "SAFETY_DRIVER_UNBUCKLED" 49 "FASCIA_VISION_OCCLUSION_AT_STOP" 48 "SEVERE_RIGHT_VISION_OCCLUSION_REVERSE" 47 "SEVERE_LEFT_VISION_OCCLUSION_REVERSE" 46 "SEVERE_BACKUP_VISION_OCCLUSION_REVERSE" 45 "SEVERE_RIGHT_VISION_OCCLUSION_MANEUVER" 44 "SEVERE_LEFT_VISION_OCCLUSION_MANEUVER" 43 "SEVERE_RIGHT_VISION_OCCLUSION" 42 "SEVERE_LEFT_VISION_OCCLUSION" 41 "SEVERE_MULTIPLE_FRONT_VISION_OCCLUSION" 40 "SEVERE_SINGLE_FRONT_VISION_OCCLUSION" 39 "CAMERA_HEALTH_METRICS_UNHEALTHY" 38 "VISION_SCENETAGS_UNHEALTHY" 37 "VISION_AUTOWIPER_UNHEALTHY" 36 "VISION_AUTOHIGHBEAM_UNHEALTHY" 35 "VISION_FAILSAFES_UNHEALTHY" 34 "RIGHT_VISION_FAILSAFE_PARKED" 33 "LEFT_VISION_FAILSAFE_PARKED" 32 "FRONT_VISION_FAILSAFE_PARKED" 31 "REAR_VISION_FAILSAFE_PARKED" 30 "CAMERA_OFFGASSING" 29 "CAMERA_OFFGASSING_PRE_ALERT" 28 "INTERMITTENT_FRAME_DROPS" 27 "CAMERA_AUTOEXPOSURE_LOST" 26 "OUT_OF_SYNC_CAMERA_STREAMS" 25 "FASCIA_CAMERA_STREAM_LOST" 24 "BACKUP_CAMERA_STREAM_LOST" 23 "RIGHT_CAMERAS_STREAM_LOST" 22 "LEFT_CAMERAS_STREAM_LOST" 21 "FRONT_CAMERAS_STREAM_LOST" 20 "CAMERA_MCU_FW_MISMATCH" 19 "FACTORY_CALIBRATION" 18 "CAMERA_PITCH_OUT_OF_BOUNDS" 17 "CAMERA_CALIBRATION" 16 "GNSS_DEGRADED_SIGNAL_STRENGTH" 15 "AP_POWER_REQUEST_NOT_NOMINAL" 14 "SENTRY_ACTIVE" 13 "NO_REDUNDANT_BRAKING" 12 "HK_RESTRICTED" 11 "OUTSIDE_GEOFENCE" 10 "RUN_MODE_NOT_FSD" 9 "AEB_ACTIVE" 8 "SUMMON_ACTIVE" 7 "AUTOPARK_ACTIVE" 6 "FSD_DISABLED" 5 "CAR_WASH_MODE" 4 "DELIVERED" 3 "NO_AUTONOMY_MODE_ACTIVE" 2 "NEUTRAL_GEAR" 1 "NONE" 0 "UNKNOWN" ;
VAL_ 1513 APP_sw456_reason2 414 "TRAJECTORY_ON_PUBLIC_ROAD_NOT_INDOORS" 413 "STOP_IN_LANE_NOT_HONORED" 412 "SIMPLE_SUMMON_OBSTACLE_BLOCKED" 411 "SEVERE_SINGLE_FRONT_VISION_OCCLUSION_AFTER_WIPE" 410 "PHONE_TOO_FAR_TO_START" 409 "MAX_SPEED_LIMIT_FOR_MODE_EXCEEDED" 408 "EPB_REDUNDANT_BRAKING_UNAVAILABLE" 407 "EGO_GEAR_NOT_ALLOWED" 406 "EGO_EXCEEDED_MAX_SUMMON_DISTANCE" 405 "DUAL_EPB_UNAVAILABLE" 404 "COMPRESSOR_FRAME_DROP_RATE_HIGH" 403 "CAN_RX_VALIDATION_ERROR" 402 "BRAKE_APPLIED_PARKED" 401 "ALARM_ACTIVE" 400 "SAFETY_DRIVER_UNBUCKLED_PRE_ACTIVATION" 399 "NOT_FACTORY_SCHEDULE" 398 "FSD_REGION_NOT_ALLOWED" 397 "FSD_QUIZ_REQUIRED" 396 "EPAS_EAC_NOT_ACTIVE_OTHER" 395 "EPAS_EAC_NOT_ACTIVE_HANDS_ON" 394 "DI_CONTROL_INTEGRATOR_WINDUP" 393 "SEVERE_SINGLE_FRONT_VISION_OCCLUSION_HIGH_FOGGING_RISK" 392 "EGO_NEAR_SUMMON_MAP_BOUNDARY_NOT_INDOORS" 391 "GOAL_NEAR_SUMMON_MAP_BOUNDARY_NOT_INDOORS" 390 "GRADE_TOO_HIGH_WITHOUT_REDUNDANT_BRAKING_LOW_MU" 389 "NAV_DESTINATION_OUTSIDE_GEOFENCE" 388 "RCM_COLLISION_SEVERITY_TRIGGERED" 387 "EPB_PARKING_AVAILABILITY_TOO_STEEP" 386 "REVERSE_GEAR_NOT_AVAILABLE" 385 "DESTINATION_OUTSIDE_GEOFENCE_AP" 384 "SSD_CLIP_LOGGING_CRITICAL" 383 "DRIVE_GEAR_NOT_AVAILABLE" 382 "SIDE_VISIBILITY_DEGRADED_PARKED_DOORS_CLOSED" 381 "PERSISTENT_FRAME_DROPS" 380 "PERSISTENT_HANDS_ON_NOT_ALLOWED" 379 "NAV_ROUTE_EXCEEDS_GEOFENCE_BUFFER" 378 "RANKER_OUTPUT_STALE" 377 "VISION_PLANNER_STALE" 376 "AUTO_WIPERS_OFF" 375 "COUNTRY_NOT_ALLOWED_FOR_OPERATION" 374 "OUTSIDE_TRACK_TEST_GEOFENCE" 373 "TEMPERATURE_EXCEEDS_ODD" 372 "RIDESHARE_NAV_GOAL_NOT_IN_SYNC" 371 "HV_BATTERY_AC_CHARGING_UNHEALTHY" 370 "HV_BATTERY_DC_CHARGING_UNHEALTHY" 369 "UI_RIDE_SETUP_IN_PROGRESS" 368 "AUTO_HEADLIGHTS_OFF" 367 "IMMOBILIZER_AUTH_AUTONOMY" 366 "DI_RESTRICTED_DRIVING_MANUAL_RECOVERY" 365 "SUMMON_ACTIVE_DURATION_EXCEEDED" 364 "ESKF_SPEED_SOURCE_ACTIVE" 363 "IMU_DATA_NOT_RELIABLE_WITH_FLEET_CONFIG_ENABLED" 362 "FASCIA_VISION_OCCLUSION_AT_LONG_STOP" 361 "HIGH_SPEED_ROAD_ON_ROUTE" 360 "EGO_ON_HIGH_SPEED_ROAD" 359 "UNACCOMPANIED_UNDERAGE_RIDER_DETECTED" 358 "AEB_FAULTED" 357 "AUDIO_HARDWARE_ODIN_FAILED" 356 "FASCIA_VISION_FAILSAFE_PARKED" 355 "APS_B_EPLANNER_NO_VALID_TRAJECTORY" 354 "APS_A_EPLANNER_NO_VALID_TRAJECTORY" 353 "FASCIA_CAM_INTEGRATED_HEATER_FAULT" 352 "BACKUP_CAM_INTEGRATED_HEATER_FAULT" 351 "RIGHT_REPEATER_CAM_INTEGRATED_HEATER_FAULT" 350 "LEFT_REPEATER_CAM_INTEGRATED_HEATER_FAULT" 349 "RIGHT_PILLAR_CAM_INTEGRATED_HEATER_FAULT" 348 "LEFT_PILLAR_CAM_INTEGRATED_HEATER_FAULT" 347 "RIGHT_PILLAR_CAM_WIRE_HEATER_FAULT" 346 "LEFT_PILLAR_CAM_WIRE_HEATER_FAULT" 345 "WINDSHIELD_CAM_WIRE_HEATER_FAULT" 344 "CONTROLLER_EPLANNER_UNHEALTHY" 343 "VEHICLE_COLLISION_DETECTED" 342 "VRU_COLLISION_DETECTED" 341 "MAJOR_COLLISION_DETECTED" 340 "ONGOING_COLLISION_DETECTED" 339 "INTEGRATOR_ACCELERATION_INVALID" 338 "CABIN_CAM_DRIVER_MONITORING_SYSTEM_UNAVAILABLE" 337 "DCAS_DRIVER_ATTENTION_STATE_DETERMINATION_DEGRADED" 336 "NON_MAIN_FRONT_CAMERAS_STREAM_LOST" 335 "MAIN_CAMERA_STREAM_LOST" 334 "DRIVER_WIPER_WASH_HEALTH_DEGRADED" 333 "EPB_AUTONOMY_BEHAVIOR_MISMATCH" 332 "DI_AUTONOMY_BEHAVIOR_MISMATCH" 331 "VC_AUTONOMY_BEHAVIOR_MISMATCH" 330 "DCAS_EXITED_REGION_TIMEOUT" 329 "WASHER_PUMP_NOT_HEALTHY" 328 "AP_B_SOC_UNHEALTHY" 327 "RCM_AIR_BAG_DEPLOY" 326 "RCM_NEAR_DEPLOY" 325 "AP_A_SOC_UNHEALTHY" 324 "ROUTE_EXCEEDS_SPEED_LIMIT" 323 "PERSISTENT_INVALID_NAV_ROUTE" 322 "NAV_ROUTE_EXITS_GEOFENCE" 321 "NAV_AVOID_HIGH_SPEED_ROADS_DISABLED" 320 "NAV_WHITELIST_ROUTING_DISABLED" 319 "NAV_ROUTE_RANKER_DISABLED" 318 "NAV_AVOID_SHORT_LANE_CHANGE_DISABLED" 317 "NAV_AVOID_UNPROTECTED_TURN_DISABLED" 316 "HIGHWAY_ON_ROUTE" 315 "EGO_ON_HIGHWAY" 314 "INVALID_VEHICLE_OPERATION_MODE" 313 "STEERING_ANGLE_OFFSET_HIGH" 312 "SAFETY_DRIVER_INATTENTIVE" 311 "TRACK_MODE_ACTIVE" 310 "EXT_TEMP_LOW_CERAMIC_BRAKES" 309 "GOAL_NEAR_SUMMON_MAP_BOUNDARY" 308 "SUMMON_HEARTBEAT_MISSING" 307 "EGO_NEAR_SUMMON_MAP_BOUNDARY" 306 "EGO_OUTSIDE_SUMMON_MAP_RADIUS" 305 "SUMMON_MAP_INVALID" 304 "RAW_UI_SUMMON_GOAL_INVALID" 303 "SUMMON_GOAL_INVALID" 302 "SYSTEM_CDP_UNAVAILABLE" 301 "SUMMON_COLLISION_DETECTION_ACTIVE" 300 "PHONE_TOO_FAR" 299 "PHONE_GPS_INVALID" 298 "GRADE_TOO_HIGH_WITHOUT_REDUNDANT_BRAKING" 297 "CABIN_CAM_DRIVER_MONITORING_UNAVAILABLE" 296 "CABIN_CAMERA_STREAM_FAILURE" 295 "DRIVER_PRESENCE_VISION_UNAVAILABLE" 294 "PEDAL_OVERRIDE_EXCEEDS_CONTROLLER_LIMITS" 293 "UPCOMING_FERRY_CROSSING" 292 "DRIVER_PARTIALLY_OCCLUDED" 291 "DRIVER_REQUIREMENTS_NOT_MET_VC" 290 "DRIVER_AGE_REQUIREMENTS_NOT_MET_VISION" 289 "GPS_DEGRADED" 288 "PILLARS_SWAP_DETECTED" 287 "NARROW_FISHEYE_SWAP_DETECTED" 286 "SCCM_MIA" 285 "RECENT_STALK_GEAR_SHIFT" 284 "IBOOSTER_MIA" 283 "PARKING_SPOT_SELECTED" 282 "SCROLL_WHEEL_INTERACTION" 281 "PEDAL_OVERRIDE_STRIKEOUT_FOR_DRIVE" 280 "PEDAL_OVERRIDE_STRIKEOUT" 279 "ABOVE_MAX_ACTIVATION_SPEED" 278 "DRIVER_MONITOR_SUSPENSION_ACTIVE" 277 "DRIVER_MONITOR_STRUCK_OUT_FOR_DRIVE" 276 "VC_CAMERA_AIR_CLEANING_STATUS_MIA" 275 "VC_CAMERA_FLUID_CLEANING_STATUS_MIA" 274 "INVALID_DI_PEDAL_POS" 273 "CABIN_CAMERA_FAN_RPM_FAULT" 272 "SELF_NETWORK_DECRYPTION_NOT_READY" 271 "OFF_ROAD_MODE_ACTIVE" 270 "SSD_CLIP_LOGGING_INACTIVE" 269 "CAMERA_EXPOSURE_INACTIVE" 268 "CAMERA_EXPOSURE_MISMATCH" 267 "CABIN_CAMERA_IR_LED_FAULTED" 266 "TAMPERING_DETECTED" 265 "NO_IMU_SOURCES_AVAILABLE" 264 "IMU_REDUNDANCY_LOST" 263 "DI_AUTONOMY_HEALTH_CAN_MESSAGE_MIA" 262 "ALL_WHEEL_SPEEDS_SENSORS_FAULTED" 261 "WHEEL_SPEEDS_CAN_MESSAGE_MIA" 260 "AP_THERMAL_MODEL_FAULT_DETECTED" 259 "SGK_AUTONOMY_MODE_NOT_IN_SYNC" 258 "SGK_AUTONOMY_STATE_NOT_IN_SYNC" 257 "ANY_RIGHT_DOOR_OPEN_BUTTON_FAULTED" 256 "ANY_LEFT_DOOR_OPEN_BUTTON_FAULTED" 255 "VCRIGHT_DOOR_STATUS_CAN_MESSAGE_MIA" 254 "VCLEFT_DOOR_STATUS_CAN_MESSAGE_MIA" 253 "BB_STATUS_CAN_MESSAGE_MIA" 252 "GTW_CAR_CONFIG_CAN_MESSAGE_MIA" 251 "TRAILER_MODE_ACTIVE" 250 "UI_LIMIT_MODE_ACTIVE" 249 "UI_QT_CAR_UNAVAILABLE" 248 "UI_CONNECTIVITY_HW_UNHEALTHY" 247 "UI_CONNECTIVITY_OFFLINE" 246 "UI_CENTER_DISPLAY_UNAVAILABLE" 245 "UI_HEALTH_STATUS_CAN_MESSAGE_MIA" 244 "ANY_LV_HEALTH_CAN_MESSAGE_INVALID" 243 "ANY_LV_HEALTH_CAN_MESSAGE_MIA" 242 "AP_SYSTEM_ISSUE_PENDING_REBOOT" 241 "AP_TASK_PENDING_REBOOT" 240 "APS_DUAL_CAMERA_POWER_FAILURE" 239 "APS_SINGLE_CAMERA_POWER_FAILURE" 238 "APS_ETH_BRIDGE_DOWN" 237 "APS_PEER_PMIC_FAULTED" 236 "APS_SELF_PMIC_FAULTED" 235 "APS_PEER_VRM_FAULTED" 234 "APS_SELF_VRM_FAULTED" 233 "APS_PEER_IMEM_FAULTED" 232 "APS_SELF_IMEM_FAULTED" 231 "APS_PEER_CAN_FAULTED" 230 "APS_SELF_CAN_FAULTED" 229 "APS_B_UNHEALTHY" 228 "APS_A_UNHEALTHY" 227 "PEER_VISION_FAILOVER_ACTIVE" 226 "ARBITER_SELECTED_BEHAVIOR_OUT_OF_DATE" 225 "ARBITER_SELECTED_BEHAVIOR_NOT_E2E" 224 "MISSION_PLANNER_DESIRED_BEHAVIOR_NOT_E2E" 223 "AUTONOMY_CONTROLLING_AND_NOT_PARKED" 222 "NO_VALID_SGK_STATUS" 221 "AUTONOMOUS_BEHAVIORS_LINK_NOT_ESTABLISHED" 220 "GNSS_PPS_MIA" 219 "GNSS_ANTENNA_DISCONNECTED" 218 "GNSS_UART_FAULTED" 217 "AP_THERMAL_DEGRADED_PULLOVER_REQ" 216 "AP_THERMAL_DEGRADED_BLOCK_ACTIVATION" 215 "DRIVER_PRESENT_NOT_ALLOWED" 214 "UNSUPERVISED_OPERATION_NOT_ALLOWED" 213 "NOT_IN_RT_NO_TAKEOVER_FLEET" 212 "SAFETY_OPERATOR_NOT_PRESENT" 211 "CAMERA_PRECONDITIONING_REQUIRED" 210 "BMS_CAN_MESSAGES_MIA" 209 "VEHICLE_LOSING_HV" 208 "HV_DRIVE_NO_RESTART" 207 "AUTONOMOUS_BEHAVIORS_TASK_SUSPENDING" 206 "AUDIO_BUS_DOWN" 205 "CAMERA_REDUNDANCY_NOT_READY" 204 "NO_VEHICLE_SPEED_SOURCE_AVAILABLE" 203 "DI_PRIMARY_SPEED_SOURCE_UNAVAILABLE" 202 "DI_SPEED_CAN_MESSAGE_MIA" 201 "DEFOG_SYSTEM_UNHEALTHY" 200 "COOLANT_SYSTEM_UNHEALTHY" 199 "DEFOG_SYSTEM_NOT_READY" 198 "COOLANT_SYSTEM_NOT_READY" 197 "NOT_AUTHENTICATED_FOR_DRIVE" 196 "UNASSIGNED_PASSENGER_UNBUCKLED" 195 "WAITING_FOR_PASSENGER_EGRESS" 194 "PASSENGER_UNEXPECTED_RIDE_INACTIVE" 193 "DRIVER_NOT_PRESENT_PRE_ACTIVATION" 192 "NARROW_WASH_NOT_AVAILABLE" 191 "REDUNDANT_IMU_CAN_MESSAGES_MIA" 190 "IMU_CAN_MESSAGES_MIA" 189 "BRAKING_CAN_MESSAGES_MIA" 188 "EPB_AUTONOMY_CAN_MESSAGES_MIA" 187 "PARK_BRAKE_CAN_MESSAGES_MIA" 186 "STEERING_CAN_MESSAGES_MIA" 185 "DI_SYSTEM_STATUS_CAN_MESSAGES_MIA" 184 "DI_CHASSIS_CONTROL_CAN_MESSAGE_MIA" 183 "APS_CAN_MESSAGES_MIA" 182 "POOR_LOCALIZATION_ACCURACY" 181 "VISION_FAILOVER_ACTIVE" 180 "SEAT_OCCUPANCY_STATUS_UNHEALTHY" 179 "TO_STREAMS_UNHEALTHY" 178 "SEATBELT_STATUS_UNHEALTHY" 177 "RCM_WARNING_INDICATOR_ON" 176 "REDUNDANT_BRAKES_FAIL_OPERATIONAL" 175 "REDUNDANT_BRAKES_REDUNDANCY_LOST" 174 "REDUNDANT_BRAKES_NOT_ARMED" 173 "REDUNDANT_BRAKES_NOT_READY" 172 "REDUNDANT_BRAKE_PATH_ACTIVE" 171 "RANKER_NOT_HEALTHY" 170 "PARKED_A_PEDAL_PRESSED" 169 "ANY_CANCEL_ACTIVE" 168 "BRAKE_CONFIRM_PENDING_PARK" 167 "BRAKE_APPLIED_D_R_N" 166 "BRAKE_RELEASE_PENDING_PARK" 165 "ENFORCED_UNPARK_DELAY_ACTIVE" 164 "WIPER_NOT_HEALTHY" 163 "RIGHT_PILLAR_CAM_HEATER_FAULT" 162 "LEFT_PILLAR_CAM_HEATER_FAULT" 161 "WINDSHIELD_CAM_HEATER_FAULT" 160 "ALL_TAIL_LIGHTS_FAULTED_IN_LOW_VIS" 159 "TAIL_LIGHT_FAULTED" 158 "REVERSE_LIGHT_FAULTED" 157 "RIGHT_TURN_LIGHT_FAULTED" 156 "LEFT_TURN_LIGHT_FAULTED" 155 "ALL_BRAKE_LIGHTS_FAULTED" 154 "BRAKE_LIGHT_FAULTED" 153 "HIGH_BEAM_LIGHT_FAULTED_IN_LOW_VIS" 152 "LOW_BEAM_LIGHT_FAULTED_IN_LOW_VIS" 151 "HIGH_BEAM_LIGHT_FAULTED" 150 "LOW_BEAM_LIGHT_FAULTED" 149 "HEADLIGHTS_NOT_AIMED" 148 "HEADLIGHTS_OFF_AT_NIGHT" 147 "AP_REDUNDANCY_UNAVAILABLE" 146 "DI_BRAKING_DECELERATION_UNAVAILABLE" 145 "DI_VDC_ACTIVE" 144 "DI_TC_ACTIVE" 143 "DI_VDC_STATE_NOT_NORMAL" 142 "DI_LOSING_PROPULSION" 141 "EPB_STATUS_NOT_PARKED" 140 "EPB_PARKING_AVAILABILITY_UNKNOWN" 139 "EPB_PARKING_AVAILABILITY_REQUEST_PATH_DEGRADED" 138 "EPB_PARKING_AVAILABILITY_SPEED_INVALID" 137 "EPB_PARKING_AVAILABILITY_FAULTED" 136 "TIRE_PRESSURE_SENSOR_FAULT" 135 "FLAT_TIRE" 134 "INTEGRATOR_HEALTH_CRITICAL" 133 "IMU_DATA_NOT_RELIABLE" 132 "FASCIA_FLUID_CLEAN_CRITICAL" 131 "BACKUP_FLUID_CLEAN_CRITICAL" 130 "RIGHT_REPEATER_FLUID_CLEAN_CRITICAL" 129 "LEFT_REPEATER_FLUID_CLEAN_CRITICAL" 128 "FASCIA_AIR_CLEAN_CRITICAL" 127 "BACKUP_AIR_CLEAN_CRITICAL" 126 "RIGHT_REPEATER_AIR_CLEAN_CRITICAL" 125 "LEFT_REPEATER_AIR_CLEAN_CRITICAL" 124 "FASCIA_FLUID_CLEAN_DEGRADED" 123 "BACKUP_FLUID_CLEAN_DEGRADED" 122 "RIGHT_REPEATER_FLUID_CLEAN_DEGRADED" 121 "LEFT_REPEATER_FLUID_CLEAN_DEGRADED" 120 "FASCIA_AIR_CLEAN_DEGRADED" 119 "BACKUP_AIR_CLEAN_DEGRADED" 118 "RIGHT_REPEATER_AIR_CLEAN_DEGRADED" 117 "LEFT_REPEATER_AIR_CLEAN_DEGRADED" 116 "TERTIARY_WASHER_FLUID_LOW" 115 "SECONDARY_WASHER_FLUID_LOW" 114 "WASHER_FLUID_LOW" 113 "ELEVATED_TIRE_PRESSURE_READING" 112 "LOW_TIRE_PRESSURE_READING" 111 "VISION_CABIN_OCCUPANCY_UNAVAILABLE" 110 "SGK_AUTOSTEER_MONITOR_ACTIVE" 109 "SGK_PLANNER_ACTIVE_D_R_N" 108 "FLEET_MAINTENANCE_EXPIRING_SOON" 107 "FLEET_MAINTENANCE_REQUIRED" 106 "CHARGE_CABLE_CONNECTED_OR_STATUS_UNKNOWN" 105 "PASSENGER_UNBUCKLED_ACTIVE_RIDE" 104 "PASSENGER_UNBUCKLED" 103 "SYSTEM_UNHEALTHY_DEV_OVERRIDE" 102 "SINGLE_SOC_HEALTHY_EXCEPTION" 101 "IMU_REPLICATION_NOT_READY" 100 "STATE_MACHINE_DISABLED" 99 "INCOMPATIBLE_SYSTEM_HEALTH" 98 "CABIN_CAM_BLINDED" 97 "RIDESHARE_INGRESS_NO_NAV_ROUTE" 96 "PASSENGER_EXPECTED" 95 "DRIVER_MONITOR_STRIKEOUT" 94 "DRIVER_NOT_PRESENT" 93 "CONTROLLER_SOLVER_CRITICAL" 92 "CONTROLLER_SOLVER_DEGRADED" 91 "CONTROLLER_DEGRADED_PEDAL_OVERRIDE" 90 "CONTROLLER_SOLVER_FAILURE" 89 "LV_CRITICAL_STATE" 88 "LV_DEGRADED_STATE" 87 "VEHICLE_AUTONOMY_BEHAVIOR_MISMATCH" 86 "CRUISE_STACK_MISMATCH" 85 "EPB_REDUNDANT_BRAKING_STATUS" 84 "EXTENDED_COMPUTE_INACTIVE_OTHER" 83 "EXTENDED_COMPUTE_TIME_SYNC_CRITICAL_DEGRADED" 82 "EXTENDED_COMPUTE_OTHER_SOC_STATE_UNKNOWN" 81 "EXTENDED_COMPUTE_OTHER_SOC_STATE_INACTIVE" 80 "EXTENDED_COMPUTE_PCIE_LINK_HEALTH" 79 "EXTENDED_COMPUTE_ETHERNET_LINK_HEALTH" 78 "EXTENDED_COMPUTE_OTHER_SOC_HEALTH_CRITICAL" 77 "EXTENDED_COMPUTE_OTHER_SOC_HEALTH_UNKNOWN" 76 "EXTENDED_COMPUTE_SOC_HEALTH_CRITICAL" 75 "EXTENDED_COMPUTE_SOC_HEALTH_UNKNOWN" 74 "FSD_FROM_PARK_DISABLED" 73 "NOT_IN_PARK_NO_TAKEOVER" 72 "NO_FIXED_ROUTE" 71 "NAV_GOAL_INVALID" 70 "ANY_EPAS_FAULT" 69 "EPAS_SYSTEM_TORQUE_REDUCED" 68 "EPAS_SECONDARY_MASTER" 67 "EPAS_REDUNDANCY_LOST" 66 "EPAS_DRIVERLESS_MODE_NOT_ACTIVE" 65 "EPAS_EAC_NOT_ACTIVE" 64 "EPAS_EAC_UNAVAILABLE" 63 "STEERING_ANGLE_INVALID" 62 "CRUISE_FAULT" 61 "CRUISE_NOT_ACTIVE_OTHER" 60 "CRUISE_NOT_ACTIVE_ESTOP" 59 "CRUISE_UNAVAILABLE_OTHER" 58 "CRUISE_UNAVAILABLE_BRAKE_APPLIED" 57 "NOT_POWER_STATE_DRIVE" 56 "FRUNK_OPEN" 55 "TRUNK_OPEN" 54 "PASSENGER_DOOR_OPEN" 53 "DRIVER_DOOR_OPEN" 52 "VISION_FPS_LOW_CAMERA_DROPS" 51 "VISION_LATENCY_HIGH" 50 "SAFETY_DRIVER_UNBUCKLED" 49 "FASCIA_VISION_OCCLUSION_AT_STOP" 48 "SEVERE_RIGHT_VISION_OCCLUSION_REVERSE" 47 "SEVERE_LEFT_VISION_OCCLUSION_REVERSE" 46 "SEVERE_BACKUP_VISION_OCCLUSION_REVERSE" 45 "SEVERE_RIGHT_VISION_OCCLUSION_MANEUVER" 44 "SEVERE_LEFT_VISION_OCCLUSION_MANEUVER" 43 "SEVERE_RIGHT_VISION_OCCLUSION" 42 "SEVERE_LEFT_VISION_OCCLUSION" 41 "SEVERE_MULTIPLE_FRONT_VISION_OCCLUSION" 40 "SEVERE_SINGLE_FRONT_VISION_OCCLUSION" 39 "CAMERA_HEALTH_METRICS_UNHEALTHY" 38 "VISION_SCENETAGS_UNHEALTHY" 37 "VISION_AUTOWIPER_UNHEALTHY" 36 "VISION_AUTOHIGHBEAM_UNHEALTHY" 35 "VISION_FAILSAFES_UNHEALTHY" 34 "RIGHT_VISION_FAILSAFE_PARKED" 33 "LEFT_VISION_FAILSAFE_PARKED" 32 "FRONT_VISION_FAILSAFE_PARKED" 31 "REAR_VISION_FAILSAFE_PARKED" 30 "CAMERA_OFFGASSING" 29 "CAMERA_OFFGASSING_PRE_ALERT" 28 "INTERMITTENT_FRAME_DROPS" 27 "CAMERA_AUTOEXPOSURE_LOST" 26 "OUT_OF_SYNC_CAMERA_STREAMS" 25 "FASCIA_CAMERA_STREAM_LOST" 24 "BACKUP_CAMERA_STREAM_LOST" 23 "RIGHT_CAMERAS_STREAM_LOST" 22 "LEFT_CAMERAS_STREAM_LOST" 21 "FRONT_CAMERAS_STREAM_LOST" 20 "CAMERA_MCU_FW_MISMATCH" 19 "FACTORY_CALIBRATION" 18 "CAMERA_PITCH_OUT_OF_BOUNDS" 17 "CAMERA_CALIBRATION" 16 "GNSS_DEGRADED_SIGNAL_STRENGTH" 15 "AP_POWER_REQUEST_NOT_NOMINAL" 14 "SENTRY_ACTIVE" 13 "NO_REDUNDANT_BRAKING" 12 "HK_RESTRICTED" 11 "OUTSIDE_GEOFENCE" 10 "RUN_MODE_NOT_FSD" 9 "AEB_ACTIVE" 8 "SUMMON_ACTIVE" 7 "AUTOPARK_ACTIVE" 6 "FSD_DISABLED" 5 "CAR_WASH_MODE" 4 "DELIVERED" 3 "NO_AUTONOMY_MODE_ACTIVE" 2 "NEUTRAL_GEAR" 1 "NONE" 0 "UNKNOWN" ;
VAL_ 1513 APP_sw456_reason3 414 "TRAJECTORY_ON_PUBLIC_ROAD_NOT_INDOORS" 413 "STOP_IN_LANE_NOT_HONORED" 412 "SIMPLE_SUMMON_OBSTACLE_BLOCKED" 411 "SEVERE_SINGLE_FRONT_VISION_OCCLUSION_AFTER_WIPE" 410 "PHONE_TOO_FAR_TO_START" 409 "MAX_SPEED_LIMIT_FOR_MODE_EXCEEDED" 408 "EPB_REDUNDANT_BRAKING_UNAVAILABLE" 407 "EGO_GEAR_NOT_ALLOWED" 406 "EGO_EXCEEDED_MAX_SUMMON_DISTANCE" 405 "DUAL_EPB_UNAVAILABLE" 404 "COMPRESSOR_FRAME_DROP_RATE_HIGH" 403 "CAN_RX_VALIDATION_ERROR" 402 "BRAKE_APPLIED_PARKED" 401 "ALARM_ACTIVE" 400 "SAFETY_DRIVER_UNBUCKLED_PRE_ACTIVATION" 399 "NOT_FACTORY_SCHEDULE" 398 "FSD_REGION_NOT_ALLOWED" 397 "FSD_QUIZ_REQUIRED" 396 "EPAS_EAC_NOT_ACTIVE_OTHER" 395 "EPAS_EAC_NOT_ACTIVE_HANDS_ON" 394 "DI_CONTROL_INTEGRATOR_WINDUP" 393 "SEVERE_SINGLE_FRONT_VISION_OCCLUSION_HIGH_FOGGING_RISK" 392 "EGO_NEAR_SUMMON_MAP_BOUNDARY_NOT_INDOORS" 391 "GOAL_NEAR_SUMMON_MAP_BOUNDARY_NOT_INDOORS" 390 "GRADE_TOO_HIGH_WITHOUT_REDUNDANT_BRAKING_LOW_MU" 389 "NAV_DESTINATION_OUTSIDE_GEOFENCE" 388 "RCM_COLLISION_SEVERITY_TRIGGERED" 387 "EPB_PARKING_AVAILABILITY_TOO_STEEP" 386 "REVERSE_GEAR_NOT_AVAILABLE" 385 "DESTINATION_OUTSIDE_GEOFENCE_AP" 384 "SSD_CLIP_LOGGING_CRITICAL" 383 "DRIVE_GEAR_NOT_AVAILABLE" 382 "SIDE_VISIBILITY_DEGRADED_PARKED_DOORS_CLOSED" 381 "PERSISTENT_FRAME_DROPS" 380 "PERSISTENT_HANDS_ON_NOT_ALLOWED" 379 "NAV_ROUTE_EXCEEDS_GEOFENCE_BUFFER" 378 "RANKER_OUTPUT_STALE" 377 "VISION_PLANNER_STALE" 376 "AUTO_WIPERS_OFF" 375 "COUNTRY_NOT_ALLOWED_FOR_OPERATION" 374 "OUTSIDE_TRACK_TEST_GEOFENCE" 373 "TEMPERATURE_EXCEEDS_ODD" 372 "RIDESHARE_NAV_GOAL_NOT_IN_SYNC" 371 "HV_BATTERY_AC_CHARGING_UNHEALTHY" 370 "HV_BATTERY_DC_CHARGING_UNHEALTHY" 369 "UI_RIDE_SETUP_IN_PROGRESS" 368 "AUTO_HEADLIGHTS_OFF" 367 "IMMOBILIZER_AUTH_AUTONOMY" 366 "DI_RESTRICTED_DRIVING_MANUAL_RECOVERY" 365 "SUMMON_ACTIVE_DURATION_EXCEEDED" 364 "ESKF_SPEED_SOURCE_ACTIVE" 363 "IMU_DATA_NOT_RELIABLE_WITH_FLEET_CONFIG_ENABLED" 362 "FASCIA_VISION_OCCLUSION_AT_LONG_STOP" 361 "HIGH_SPEED_ROAD_ON_ROUTE" 360 "EGO_ON_HIGH_SPEED_ROAD" 359 "UNACCOMPANIED_UNDERAGE_RIDER_DETECTED" 358 "AEB_FAULTED" 357 "AUDIO_HARDWARE_ODIN_FAILED" 356 "FASCIA_VISION_FAILSAFE_PARKED" 355 "APS_B_EPLANNER_NO_VALID_TRAJECTORY" 354 "APS_A_EPLANNER_NO_VALID_TRAJECTORY" 353 "FASCIA_CAM_INTEGRATED_HEATER_FAULT" 352 "BACKUP_CAM_INTEGRATED_HEATER_FAULT" 351 "RIGHT_REPEATER_CAM_INTEGRATED_HEATER_FAULT" 350 "LEFT_REPEATER_CAM_INTEGRATED_HEATER_FAULT" 349 "RIGHT_PILLAR_CAM_INTEGRATED_HEATER_FAULT" 348 "LEFT_PILLAR_CAM_INTEGRATED_HEATER_FAULT" 347 "RIGHT_PILLAR_CAM_WIRE_HEATER_FAULT" 346 "LEFT_PILLAR_CAM_WIRE_HEATER_FAULT" 345 "WINDSHIELD_CAM_WIRE_HEATER_FAULT" 344 "CONTROLLER_EPLANNER_UNHEALTHY" 343 "VEHICLE_COLLISION_DETECTED" 342 "VRU_COLLISION_DETECTED" 341 "MAJOR_COLLISION_DETECTED" 340 "ONGOING_COLLISION_DETECTED" 339 "INTEGRATOR_ACCELERATION_INVALID" 338 "CABIN_CAM_DRIVER_MONITORING_SYSTEM_UNAVAILABLE" 337 "DCAS_DRIVER_ATTENTION_STATE_DETERMINATION_DEGRADED" 336 "NON_MAIN_FRONT_CAMERAS_STREAM_LOST" 335 "MAIN_CAMERA_STREAM_LOST" 334 "DRIVER_WIPER_WASH_HEALTH_DEGRADED" 333 "EPB_AUTONOMY_BEHAVIOR_MISMATCH" 332 "DI_AUTONOMY_BEHAVIOR_MISMATCH" 331 "VC_AUTONOMY_BEHAVIOR_MISMATCH" 330 "DCAS_EXITED_REGION_TIMEOUT" 329 "WASHER_PUMP_NOT_HEALTHY" 328 "AP_B_SOC_UNHEALTHY" 327 "RCM_AIR_BAG_DEPLOY" 326 "RCM_NEAR_DEPLOY" 325 "AP_A_SOC_UNHEALTHY" 324 "ROUTE_EXCEEDS_SPEED_LIMIT" 323 "PERSISTENT_INVALID_NAV_ROUTE" 322 "NAV_ROUTE_EXITS_GEOFENCE" 321 "NAV_AVOID_HIGH_SPEED_ROADS_DISABLED" 320 "NAV_WHITELIST_ROUTING_DISABLED" 319 "NAV_ROUTE_RANKER_DISABLED" 318 "NAV_AVOID_SHORT_LANE_CHANGE_DISABLED" 317 "NAV_AVOID_UNPROTECTED_TURN_DISABLED" 316 "HIGHWAY_ON_ROUTE" 315 "EGO_ON_HIGHWAY" 314 "INVALID_VEHICLE_OPERATION_MODE" 313 "STEERING_ANGLE_OFFSET_HIGH" 312 "SAFETY_DRIVER_INATTENTIVE" 311 "TRACK_MODE_ACTIVE" 310 "EXT_TEMP_LOW_CERAMIC_BRAKES" 309 "GOAL_NEAR_SUMMON_MAP_BOUNDARY" 308 "SUMMON_HEARTBEAT_MISSING" 307 "EGO_NEAR_SUMMON_MAP_BOUNDARY" 306 "EGO_OUTSIDE_SUMMON_MAP_RADIUS" 305 "SUMMON_MAP_INVALID" 304 "RAW_UI_SUMMON_GOAL_INVALID" 303 "SUMMON_GOAL_INVALID" 302 "SYSTEM_CDP_UNAVAILABLE" 301 "SUMMON_COLLISION_DETECTION_ACTIVE" 300 "PHONE_TOO_FAR" 299 "PHONE_GPS_INVALID" 298 "GRADE_TOO_HIGH_WITHOUT_REDUNDANT_BRAKING" 297 "CABIN_CAM_DRIVER_MONITORING_UNAVAILABLE" 296 "CABIN_CAMERA_STREAM_FAILURE" 295 "DRIVER_PRESENCE_VISION_UNAVAILABLE" 294 "PEDAL_OVERRIDE_EXCEEDS_CONTROLLER_LIMITS" 293 "UPCOMING_FERRY_CROSSING" 292 "DRIVER_PARTIALLY_OCCLUDED" 291 "DRIVER_REQUIREMENTS_NOT_MET_VC" 290 "DRIVER_AGE_REQUIREMENTS_NOT_MET_VISION" 289 "GPS_DEGRADED" 288 "PILLARS_SWAP_DETECTED" 287 "NARROW_FISHEYE_SWAP_DETECTED" 286 "SCCM_MIA" 285 "RECENT_STALK_GEAR_SHIFT" 284 "IBOOSTER_MIA" 283 "PARKING_SPOT_SELECTED" 282 "SCROLL_WHEEL_INTERACTION" 281 "PEDAL_OVERRIDE_STRIKEOUT_FOR_DRIVE" 280 "PEDAL_OVERRIDE_STRIKEOUT" 279 "ABOVE_MAX_ACTIVATION_SPEED" 278 "DRIVER_MONITOR_SUSPENSION_ACTIVE" 277 "DRIVER_MONITOR_STRUCK_OUT_FOR_DRIVE" 276 "VC_CAMERA_AIR_CLEANING_STATUS_MIA" 275 "VC_CAMERA_FLUID_CLEANING_STATUS_MIA" 274 "INVALID_DI_PEDAL_POS" 273 "CABIN_CAMERA_FAN_RPM_FAULT" 272 "SELF_NETWORK_DECRYPTION_NOT_READY" 271 "OFF_ROAD_MODE_ACTIVE" 270 "SSD_CLIP_LOGGING_INACTIVE" 269 "CAMERA_EXPOSURE_INACTIVE" 268 "CAMERA_EXPOSURE_MISMATCH" 267 "CABIN_CAMERA_IR_LED_FAULTED" 266 "TAMPERING_DETECTED" 265 "NO_IMU_SOURCES_AVAILABLE" 264 "IMU_REDUNDANCY_LOST" 263 "DI_AUTONOMY_HEALTH_CAN_MESSAGE_MIA" 262 "ALL_WHEEL_SPEEDS_SENSORS_FAULTED" 261 "WHEEL_SPEEDS_CAN_MESSAGE_MIA" 260 "AP_THERMAL_MODEL_FAULT_DETECTED" 259 "SGK_AUTONOMY_MODE_NOT_IN_SYNC" 258 "SGK_AUTONOMY_STATE_NOT_IN_SYNC" 257 "ANY_RIGHT_DOOR_OPEN_BUTTON_FAULTED" 256 "ANY_LEFT_DOOR_OPEN_BUTTON_FAULTED" 255 "VCRIGHT_DOOR_STATUS_CAN_MESSAGE_MIA" 254 "VCLEFT_DOOR_STATUS_CAN_MESSAGE_MIA" 253 "BB_STATUS_CAN_MESSAGE_MIA" 252 "GTW_CAR_CONFIG_CAN_MESSAGE_MIA" 251 "TRAILER_MODE_ACTIVE" 250 "UI_LIMIT_MODE_ACTIVE" 249 "UI_QT_CAR_UNAVAILABLE" 248 "UI_CONNECTIVITY_HW_UNHEALTHY" 247 "UI_CONNECTIVITY_OFFLINE" 246 "UI_CENTER_DISPLAY_UNAVAILABLE" 245 "UI_HEALTH_STATUS_CAN_MESSAGE_MIA" 244 "ANY_LV_HEALTH_CAN_MESSAGE_INVALID" 243 "ANY_LV_HEALTH_CAN_MESSAGE_MIA" 242 "AP_SYSTEM_ISSUE_PENDING_REBOOT" 241 "AP_TASK_PENDING_REBOOT" 240 "APS_DUAL_CAMERA_POWER_FAILURE" 239 "APS_SINGLE_CAMERA_POWER_FAILURE" 238 "APS_ETH_BRIDGE_DOWN" 237 "APS_PEER_PMIC_FAULTED" 236 "APS_SELF_PMIC_FAULTED" 235 "APS_PEER_VRM_FAULTED" 234 "APS_SELF_VRM_FAULTED" 233 "APS_PEER_IMEM_FAULTED" 232 "APS_SELF_IMEM_FAULTED" 231 "APS_PEER_CAN_FAULTED" 230 "APS_SELF_CAN_FAULTED" 229 "APS_B_UNHEALTHY" 228 "APS_A_UNHEALTHY" 227 "PEER_VISION_FAILOVER_ACTIVE" 226 "ARBITER_SELECTED_BEHAVIOR_OUT_OF_DATE" 225 "ARBITER_SELECTED_BEHAVIOR_NOT_E2E" 224 "MISSION_PLANNER_DESIRED_BEHAVIOR_NOT_E2E" 223 "AUTONOMY_CONTROLLING_AND_NOT_PARKED" 222 "NO_VALID_SGK_STATUS" 221 "AUTONOMOUS_BEHAVIORS_LINK_NOT_ESTABLISHED" 220 "GNSS_PPS_MIA" 219 "GNSS_ANTENNA_DISCONNECTED" 218 "GNSS_UART_FAULTED" 217 "AP_THERMAL_DEGRADED_PULLOVER_REQ" 216 "AP_THERMAL_DEGRADED_BLOCK_ACTIVATION" 215 "DRIVER_PRESENT_NOT_ALLOWED" 214 "UNSUPERVISED_OPERATION_NOT_ALLOWED" 213 "NOT_IN_RT_NO_TAKEOVER_FLEET" 212 "SAFETY_OPERATOR_NOT_PRESENT" 211 "CAMERA_PRECONDITIONING_REQUIRED" 210 "BMS_CAN_MESSAGES_MIA" 209 "VEHICLE_LOSING_HV" 208 "HV_DRIVE_NO_RESTART" 207 "AUTONOMOUS_BEHAVIORS_TASK_SUSPENDING" 206 "AUDIO_BUS_DOWN" 205 "CAMERA_REDUNDANCY_NOT_READY" 204 "NO_VEHICLE_SPEED_SOURCE_AVAILABLE" 203 "DI_PRIMARY_SPEED_SOURCE_UNAVAILABLE" 202 "DI_SPEED_CAN_MESSAGE_MIA" 201 "DEFOG_SYSTEM_UNHEALTHY" 200 "COOLANT_SYSTEM_UNHEALTHY" 199 "DEFOG_SYSTEM_NOT_READY" 198 "COOLANT_SYSTEM_NOT_READY" 197 "NOT_AUTHENTICATED_FOR_DRIVE" 196 "UNASSIGNED_PASSENGER_UNBUCKLED" 195 "WAITING_FOR_PASSENGER_EGRESS" 194 "PASSENGER_UNEXPECTED_RIDE_INACTIVE" 193 "DRIVER_NOT_PRESENT_PRE_ACTIVATION" 192 "NARROW_WASH_NOT_AVAILABLE" 191 "REDUNDANT_IMU_CAN_MESSAGES_MIA" 190 "IMU_CAN_MESSAGES_MIA" 189 "BRAKING_CAN_MESSAGES_MIA" 188 "EPB_AUTONOMY_CAN_MESSAGES_MIA" 187 "PARK_BRAKE_CAN_MESSAGES_MIA" 186 "STEERING_CAN_MESSAGES_MIA" 185 "DI_SYSTEM_STATUS_CAN_MESSAGES_MIA" 184 "DI_CHASSIS_CONTROL_CAN_MESSAGE_MIA" 183 "APS_CAN_MESSAGES_MIA" 182 "POOR_LOCALIZATION_ACCURACY" 181 "VISION_FAILOVER_ACTIVE" 180 "SEAT_OCCUPANCY_STATUS_UNHEALTHY" 179 "TO_STREAMS_UNHEALTHY" 178 "SEATBELT_STATUS_UNHEALTHY" 177 "RCM_WARNING_INDICATOR_ON" 176 "REDUNDANT_BRAKES_FAIL_OPERATIONAL" 175 "REDUNDANT_BRAKES_REDUNDANCY_LOST" 174 "REDUNDANT_BRAKES_NOT_ARMED" 173 "REDUNDANT_BRAKES_NOT_READY" 172 "REDUNDANT_BRAKE_PATH_ACTIVE" 171 "RANKER_NOT_HEALTHY" 170 "PARKED_A_PEDAL_PRESSED" 169 "ANY_CANCEL_ACTIVE" 168 "BRAKE_CONFIRM_PENDING_PARK" 167 "BRAKE_APPLIED_D_R_N" 166 "BRAKE_RELEASE_PENDING_PARK" 165 "ENFORCED_UNPARK_DELAY_ACTIVE" 164 "WIPER_NOT_HEALTHY" 163 "RIGHT_PILLAR_CAM_HEATER_FAULT" 162 "LEFT_PILLAR_CAM_HEATER_FAULT" 161 "WINDSHIELD_CAM_HEATER_FAULT" 160 "ALL_TAIL_LIGHTS_FAULTED_IN_LOW_VIS" 159 "TAIL_LIGHT_FAULTED" 158 "REVERSE_LIGHT_FAULTED" 157 "RIGHT_TURN_LIGHT_FAULTED" 156 "LEFT_TURN_LIGHT_FAULTED" 155 "ALL_BRAKE_LIGHTS_FAULTED" 154 "BRAKE_LIGHT_FAULTED" 153 "HIGH_BEAM_LIGHT_FAULTED_IN_LOW_VIS" 152 "LOW_BEAM_LIGHT_FAULTED_IN_LOW_VIS" 151 "HIGH_BEAM_LIGHT_FAULTED" 150 "LOW_BEAM_LIGHT_FAULTED" 149 "HEADLIGHTS_NOT_AIMED" 148 "HEADLIGHTS_OFF_AT_NIGHT" 147 "AP_REDUNDANCY_UNAVAILABLE" 146 "DI_BRAKING_DECELERATION_UNAVAILABLE" 145 "DI_VDC_ACTIVE" 144 "DI_TC_ACTIVE" 143 "DI_VDC_STATE_NOT_NORMAL" 142 "DI_LOSING_PROPULSION" 141 "EPB_STATUS_NOT_PARKED" 140 "EPB_PARKING_AVAILABILITY_UNKNOWN" 139 "EPB_PARKING_AVAILABILITY_REQUEST_PATH_DEGRADED" 138 "EPB_PARKING_AVAILABILITY_SPEED_INVALID" 137 "EPB_PARKING_AVAILABILITY_FAULTED" 136 "TIRE_PRESSURE_SENSOR_FAULT" 135 "FLAT_TIRE" 134 "INTEGRATOR_HEALTH_CRITICAL" 133 "IMU_DATA_NOT_RELIABLE" 132 "FASCIA_FLUID_CLEAN_CRITICAL" 131 "BACKUP_FLUID_CLEAN_CRITICAL" 130 "RIGHT_REPEATER_FLUID_CLEAN_CRITICAL" 129 "LEFT_REPEATER_FLUID_CLEAN_CRITICAL" 128 "FASCIA_AIR_CLEAN_CRITICAL" 127 "BACKUP_AIR_CLEAN_CRITICAL" 126 "RIGHT_REPEATER_AIR_CLEAN_CRITICAL" 125 "LEFT_REPEATER_AIR_CLEAN_CRITICAL" 124 "FASCIA_FLUID_CLEAN_DEGRADED" 123 "BACKUP_FLUID_CLEAN_DEGRADED" 122 "RIGHT_REPEATER_FLUID_CLEAN_DEGRADED" 121 "LEFT_REPEATER_FLUID_CLEAN_DEGRADED" 120 "FASCIA_AIR_CLEAN_DEGRADED" 119 "BACKUP_AIR_CLEAN_DEGRADED" 118 "RIGHT_REPEATER_AIR_CLEAN_DEGRADED" 117 "LEFT_REPEATER_AIR_CLEAN_DEGRADED" 116 "TERTIARY_WASHER_FLUID_LOW" 115 "SECONDARY_WASHER_FLUID_LOW" 114 "WASHER_FLUID_LOW" 113 "ELEVATED_TIRE_PRESSURE_READING" 112 "LOW_TIRE_PRESSURE_READING" 111 "VISION_CABIN_OCCUPANCY_UNAVAILABLE" 110 "SGK_AUTOSTEER_MONITOR_ACTIVE" 109 "SGK_PLANNER_ACTIVE_D_R_N" 108 "FLEET_MAINTENANCE_EXPIRING_SOON" 107 "FLEET_MAINTENANCE_REQUIRED" 106 "CHARGE_CABLE_CONNECTED_OR_STATUS_UNKNOWN" 105 "PASSENGER_UNBUCKLED_ACTIVE_RIDE" 104 "PASSENGER_UNBUCKLED" 103 "SYSTEM_UNHEALTHY_DEV_OVERRIDE" 102 "SINGLE_SOC_HEALTHY_EXCEPTION" 101 "IMU_REPLICATION_NOT_READY" 100 "STATE_MACHINE_DISABLED" 99 "INCOMPATIBLE_SYSTEM_HEALTH" 98 "CABIN_CAM_BLINDED" 97 "RIDESHARE_INGRESS_NO_NAV_ROUTE" 96 "PASSENGER_EXPECTED" 95 "DRIVER_MONITOR_STRIKEOUT" 94 "DRIVER_NOT_PRESENT" 93 "CONTROLLER_SOLVER_CRITICAL" 92 "CONTROLLER_SOLVER_DEGRADED" 91 "CONTROLLER_DEGRADED_PEDAL_OVERRIDE" 90 "CONTROLLER_SOLVER_FAILURE" 89 "LV_CRITICAL_STATE" 88 "LV_DEGRADED_STATE" 87 "VEHICLE_AUTONOMY_BEHAVIOR_MISMATCH" 86 "CRUISE_STACK_MISMATCH" 85 "EPB_REDUNDANT_BRAKING_STATUS" 84 "EXTENDED_COMPUTE_INACTIVE_OTHER" 83 "EXTENDED_COMPUTE_TIME_SYNC_CRITICAL_DEGRADED" 82 "EXTENDED_COMPUTE_OTHER_SOC_STATE_UNKNOWN" 81 "EXTENDED_COMPUTE_OTHER_SOC_STATE_INACTIVE" 80 "EXTENDED_COMPUTE_PCIE_LINK_HEALTH" 79 "EXTENDED_COMPUTE_ETHERNET_LINK_HEALTH" 78 "EXTENDED_COMPUTE_OTHER_SOC_HEALTH_CRITICAL" 77 "EXTENDED_COMPUTE_OTHER_SOC_HEALTH_UNKNOWN" 76 "EXTENDED_COMPUTE_SOC_HEALTH_CRITICAL" 75 "EXTENDED_COMPUTE_SOC_HEALTH_UNKNOWN" 74 "FSD_FROM_PARK_DISABLED" 73 "NOT_IN_PARK_NO_TAKEOVER" 72 "NO_FIXED_ROUTE" 71 "NAV_GOAL_INVALID" 70 "ANY_EPAS_FAULT" 69 "EPAS_SYSTEM_TORQUE_REDUCED" 68 "EPAS_SECONDARY_MASTER" 67 "EPAS_REDUNDANCY_LOST" 66 "EPAS_DRIVERLESS_MODE_NOT_ACTIVE" 65 "EPAS_EAC_NOT_ACTIVE" 64 "EPAS_EAC_UNAVAILABLE" 63 "STEERING_ANGLE_INVALID" 62 "CRUISE_FAULT" 61 "CRUISE_NOT_ACTIVE_OTHER" 60 "CRUISE_NOT_ACTIVE_ESTOP" 59 "CRUISE_UNAVAILABLE_OTHER" 58 "CRUISE_UNAVAILABLE_BRAKE_APPLIED" 57 "NOT_POWER_STATE_DRIVE" 56 "FRUNK_OPEN" 55 "TRUNK_OPEN" 54 "PASSENGER_DOOR_OPEN" 53 "DRIVER_DOOR_OPEN" 52 "VISION_FPS_LOW_CAMERA_DROPS" 51 "VISION_LATENCY_HIGH" 50 "SAFETY_DRIVER_UNBUCKLED" 49 "FASCIA_VISION_OCCLUSION_AT_STOP" 48 "SEVERE_RIGHT_VISION_OCCLUSION_REVERSE" 47 "SEVERE_LEFT_VISION_OCCLUSION_REVERSE" 46 "SEVERE_BACKUP_VISION_OCCLUSION_REVERSE" 45 "SEVERE_RIGHT_VISION_OCCLUSION_MANEUVER" 44 "SEVERE_LEFT_VISION_OCCLUSION_MANEUVER" 43 "SEVERE_RIGHT_VISION_OCCLUSION" 42 "SEVERE_LEFT_VISION_OCCLUSION" 41 "SEVERE_MULTIPLE_FRONT_VISION_OCCLUSION" 40 "SEVERE_SINGLE_FRONT_VISION_OCCLUSION" 39 "CAMERA_HEALTH_METRICS_UNHEALTHY" 38 "VISION_SCENETAGS_UNHEALTHY" 37 "VISION_AUTOWIPER_UNHEALTHY" 36 "VISION_AUTOHIGHBEAM_UNHEALTHY" 35 "VISION_FAILSAFES_UNHEALTHY" 34 "RIGHT_VISION_FAILSAFE_PARKED" 33 "LEFT_VISION_FAILSAFE_PARKED" 32 "FRONT_VISION_FAILSAFE_PARKED" 31 "REAR_VISION_FAILSAFE_PARKED" 30 "CAMERA_OFFGASSING" 29 "CAMERA_OFFGASSING_PRE_ALERT" 28 "INTERMITTENT_FRAME_DROPS" 27 "CAMERA_AUTOEXPOSURE_LOST" 26 "OUT_OF_SYNC_CAMERA_STREAMS" 25 "FASCIA_CAMERA_STREAM_LOST" 24 "BACKUP_CAMERA_STREAM_LOST" 23 "RIGHT_CAMERAS_STREAM_LOST" 22 "LEFT_CAMERAS_STREAM_LOST" 21 "FRONT_CAMERAS_STREAM_LOST" 20 "CAMERA_MCU_FW_MISMATCH" 19 "FACTORY_CALIBRATION" 18 "CAMERA_PITCH_OUT_OF_BOUNDS" 17 "CAMERA_CALIBRATION" 16 "GNSS_DEGRADED_SIGNAL_STRENGTH" 15 "AP_POWER_REQUEST_NOT_NOMINAL" 14 "SENTRY_ACTIVE" 13 "NO_REDUNDANT_BRAKING" 12 "HK_RESTRICTED" 11 "OUTSIDE_GEOFENCE" 10 "RUN_MODE_NOT_FSD" 9 "AEB_ACTIVE" 8 "SUMMON_ACTIVE" 7 "AUTOPARK_ACTIVE" 6 "FSD_DISABLED" 5 "CAR_WASH_MODE" 4 "DELIVERED" 3 "NO_AUTONOMY_MODE_ACTIVE" 2 "NEUTRAL_GEAR" 1 "NONE" 0 "UNKNOWN" ;
VAL_ 1513 APP_sw457_reason1 414 "TRAJECTORY_ON_PUBLIC_ROAD_NOT_INDOORS" 413 "STOP_IN_LANE_NOT_HONORED" 412 "SIMPLE_SUMMON_OBSTACLE_BLOCKED" 411 "SEVERE_SINGLE_FRONT_VISION_OCCLUSION_AFTER_WIPE" 410 "PHONE_TOO_FAR_TO_START" 409 "MAX_SPEED_LIMIT_FOR_MODE_EXCEEDED" 408 "EPB_REDUNDANT_BRAKING_UNAVAILABLE" 407 "EGO_GEAR_NOT_ALLOWED" 406 "EGO_EXCEEDED_MAX_SUMMON_DISTANCE" 405 "DUAL_EPB_UNAVAILABLE" 404 "COMPRESSOR_FRAME_DROP_RATE_HIGH" 403 "CAN_RX_VALIDATION_ERROR" 402 "BRAKE_APPLIED_PARKED" 401 "ALARM_ACTIVE" 400 "SAFETY_DRIVER_UNBUCKLED_PRE_ACTIVATION" 399 "NOT_FACTORY_SCHEDULE" 398 "FSD_REGION_NOT_ALLOWED" 397 "FSD_QUIZ_REQUIRED" 396 "EPAS_EAC_NOT_ACTIVE_OTHER" 395 "EPAS_EAC_NOT_ACTIVE_HANDS_ON" 394 "DI_CONTROL_INTEGRATOR_WINDUP" 393 "SEVERE_SINGLE_FRONT_VISION_OCCLUSION_HIGH_FOGGING_RISK" 392 "EGO_NEAR_SUMMON_MAP_BOUNDARY_NOT_INDOORS" 391 "GOAL_NEAR_SUMMON_MAP_BOUNDARY_NOT_INDOORS" 390 "GRADE_TOO_HIGH_WITHOUT_REDUNDANT_BRAKING_LOW_MU" 389 "NAV_DESTINATION_OUTSIDE_GEOFENCE" 388 "RCM_COLLISION_SEVERITY_TRIGGERED" 387 "EPB_PARKING_AVAILABILITY_TOO_STEEP" 386 "REVERSE_GEAR_NOT_AVAILABLE" 385 "DESTINATION_OUTSIDE_GEOFENCE_AP" 384 "SSD_CLIP_LOGGING_CRITICAL" 383 "DRIVE_GEAR_NOT_AVAILABLE" 382 "SIDE_VISIBILITY_DEGRADED_PARKED_DOORS_CLOSED" 381 "PERSISTENT_FRAME_DROPS" 380 "PERSISTENT_HANDS_ON_NOT_ALLOWED" 379 "NAV_ROUTE_EXCEEDS_GEOFENCE_BUFFER" 378 "RANKER_OUTPUT_STALE" 377 "VISION_PLANNER_STALE" 376 "AUTO_WIPERS_OFF" 375 "COUNTRY_NOT_ALLOWED_FOR_OPERATION" 374 "OUTSIDE_TRACK_TEST_GEOFENCE" 373 "TEMPERATURE_EXCEEDS_ODD" 372 "RIDESHARE_NAV_GOAL_NOT_IN_SYNC" 371 "HV_BATTERY_AC_CHARGING_UNHEALTHY" 370 "HV_BATTERY_DC_CHARGING_UNHEALTHY" 369 "UI_RIDE_SETUP_IN_PROGRESS" 368 "AUTO_HEADLIGHTS_OFF" 367 "IMMOBILIZER_AUTH_AUTONOMY" 366 "DI_RESTRICTED_DRIVING_MANUAL_RECOVERY" 365 "SUMMON_ACTIVE_DURATION_EXCEEDED" 364 "ESKF_SPEED_SOURCE_ACTIVE" 363 "IMU_DATA_NOT_RELIABLE_WITH_FLEET_CONFIG_ENABLED" 362 "FASCIA_VISION_OCCLUSION_AT_LONG_STOP" 361 "HIGH_SPEED_ROAD_ON_ROUTE" 360 "EGO_ON_HIGH_SPEED_ROAD" 359 "UNACCOMPANIED_UNDERAGE_RIDER_DETECTED" 358 "AEB_FAULTED" 357 "AUDIO_HARDWARE_ODIN_FAILED" 356 "FASCIA_VISION_FAILSAFE_PARKED" 355 "APS_B_EPLANNER_NO_VALID_TRAJECTORY" 354 "APS_A_EPLANNER_NO_VALID_TRAJECTORY" 353 "FASCIA_CAM_INTEGRATED_HEATER_FAULT" 352 "BACKUP_CAM_INTEGRATED_HEATER_FAULT" 351 "RIGHT_REPEATER_CAM_INTEGRATED_HEATER_FAULT" 350 "LEFT_REPEATER_CAM_INTEGRATED_HEATER_FAULT" 349 "RIGHT_PILLAR_CAM_INTEGRATED_HEATER_FAULT" 348 "LEFT_PILLAR_CAM_INTEGRATED_HEATER_FAULT" 347 "RIGHT_PILLAR_CAM_WIRE_HEATER_FAULT" 346 "LEFT_PILLAR_CAM_WIRE_HEATER_FAULT" 345 "WINDSHIELD_CAM_WIRE_HEATER_FAULT" 344 "CONTROLLER_EPLANNER_UNHEALTHY" 343 "VEHICLE_COLLISION_DETECTED" 342 "VRU_COLLISION_DETECTED" 341 "MAJOR_COLLISION_DETECTED" 340 "ONGOING_COLLISION_DETECTED" 339 "INTEGRATOR_ACCELERATION_INVALID" 338 "CABIN_CAM_DRIVER_MONITORING_SYSTEM_UNAVAILABLE" 337 "DCAS_DRIVER_ATTENTION_STATE_DETERMINATION_DEGRADED" 336 "NON_MAIN_FRONT_CAMERAS_STREAM_LOST" 335 "MAIN_CAMERA_STREAM_LOST" 334 "DRIVER_WIPER_WASH_HEALTH_DEGRADED" 333 "EPB_AUTONOMY_BEHAVIOR_MISMATCH" 332 "DI_AUTONOMY_BEHAVIOR_MISMATCH" 331 "VC_AUTONOMY_BEHAVIOR_MISMATCH" 330 "DCAS_EXITED_REGION_TIMEOUT" 329 "WASHER_PUMP_NOT_HEALTHY" 328 "AP_B_SOC_UNHEALTHY" 327 "RCM_AIR_BAG_DEPLOY" 326 "RCM_NEAR_DEPLOY" 325 "AP_A_SOC_UNHEALTHY" 324 "ROUTE_EXCEEDS_SPEED_LIMIT" 323 "PERSISTENT_INVALID_NAV_ROUTE" 322 "NAV_ROUTE_EXITS_GEOFENCE" 321 "NAV_AVOID_HIGH_SPEED_ROADS_DISABLED" 320 "NAV_WHITELIST_ROUTING_DISABLED" 319 "NAV_ROUTE_RANKER_DISABLED" 318 "NAV_AVOID_SHORT_LANE_CHANGE_DISABLED" 317 "NAV_AVOID_UNPROTECTED_TURN_DISABLED" 316 "HIGHWAY_ON_ROUTE" 315 "EGO_ON_HIGHWAY" 314 "INVALID_VEHICLE_OPERATION_MODE" 313 "STEERING_ANGLE_OFFSET_HIGH" 312 "SAFETY_DRIVER_INATTENTIVE" 311 "TRACK_MODE_ACTIVE" 310 "EXT_TEMP_LOW_CERAMIC_BRAKES" 309 "GOAL_NEAR_SUMMON_MAP_BOUNDARY" 308 "SUMMON_HEARTBEAT_MISSING" 307 "EGO_NEAR_SUMMON_MAP_BOUNDARY" 306 "EGO_OUTSIDE_SUMMON_MAP_RADIUS" 305 "SUMMON_MAP_INVALID" 304 "RAW_UI_SUMMON_GOAL_INVALID" 303 "SUMMON_GOAL_INVALID" 302 "SYSTEM_CDP_UNAVAILABLE" 301 "SUMMON_COLLISION_DETECTION_ACTIVE" 300 "PHONE_TOO_FAR" 299 "PHONE_GPS_INVALID" 298 "GRADE_TOO_HIGH_WITHOUT_REDUNDANT_BRAKING" 297 "CABIN_CAM_DRIVER_MONITORING_UNAVAILABLE" 296 "CABIN_CAMERA_STREAM_FAILURE" 295 "DRIVER_PRESENCE_VISION_UNAVAILABLE" 294 "PEDAL_OVERRIDE_EXCEEDS_CONTROLLER_LIMITS" 293 "UPCOMING_FERRY_CROSSING" 292 "DRIVER_PARTIALLY_OCCLUDED" 291 "DRIVER_REQUIREMENTS_NOT_MET_VC" 290 "DRIVER_AGE_REQUIREMENTS_NOT_MET_VISION" 289 "GPS_DEGRADED" 288 "PILLARS_SWAP_DETECTED" 287 "NARROW_FISHEYE_SWAP_DETECTED" 286 "SCCM_MIA" 285 "RECENT_STALK_GEAR_SHIFT" 284 "IBOOSTER_MIA" 283 "PARKING_SPOT_SELECTED" 282 "SCROLL_WHEEL_INTERACTION" 281 "PEDAL_OVERRIDE_STRIKEOUT_FOR_DRIVE" 280 "PEDAL_OVERRIDE_STRIKEOUT" 279 "ABOVE_MAX_ACTIVATION_SPEED" 278 "DRIVER_MONITOR_SUSPENSION_ACTIVE" 277 "DRIVER_MONITOR_STRUCK_OUT_FOR_DRIVE" 276 "VC_CAMERA_AIR_CLEANING_STATUS_MIA" 275 "VC_CAMERA_FLUID_CLEANING_STATUS_MIA" 274 "INVALID_DI_PEDAL_POS" 273 "CABIN_CAMERA_FAN_RPM_FAULT" 272 "SELF_NETWORK_DECRYPTION_NOT_READY" 271 "OFF_ROAD_MODE_ACTIVE" 270 "SSD_CLIP_LOGGING_INACTIVE" 269 "CAMERA_EXPOSURE_INACTIVE" 268 "CAMERA_EXPOSURE_MISMATCH" 267 "CABIN_CAMERA_IR_LED_FAULTED" 266 "TAMPERING_DETECTED" 265 "NO_IMU_SOURCES_AVAILABLE" 264 "IMU_REDUNDANCY_LOST" 263 "DI_AUTONOMY_HEALTH_CAN_MESSAGE_MIA" 262 "ALL_WHEEL_SPEEDS_SENSORS_FAULTED" 261 "WHEEL_SPEEDS_CAN_MESSAGE_MIA" 260 "AP_THERMAL_MODEL_FAULT_DETECTED" 259 "SGK_AUTONOMY_MODE_NOT_IN_SYNC" 258 "SGK_AUTONOMY_STATE_NOT_IN_SYNC" 257 "ANY_RIGHT_DOOR_OPEN_BUTTON_FAULTED" 256 "ANY_LEFT_DOOR_OPEN_BUTTON_FAULTED" 255 "VCRIGHT_DOOR_STATUS_CAN_MESSAGE_MIA" 254 "VCLEFT_DOOR_STATUS_CAN_MESSAGE_MIA" 253 "BB_STATUS_CAN_MESSAGE_MIA" 252 "GTW_CAR_CONFIG_CAN_MESSAGE_MIA" 251 "TRAILER_MODE_ACTIVE" 250 "UI_LIMIT_MODE_ACTIVE" 249 "UI_QT_CAR_UNAVAILABLE" 248 "UI_CONNECTIVITY_HW_UNHEALTHY" 247 "UI_CONNECTIVITY_OFFLINE" 246 "UI_CENTER_DISPLAY_UNAVAILABLE" 245 "UI_HEALTH_STATUS_CAN_MESSAGE_MIA" 244 "ANY_LV_HEALTH_CAN_MESSAGE_INVALID" 243 "ANY_LV_HEALTH_CAN_MESSAGE_MIA" 242 "AP_SYSTEM_ISSUE_PENDING_REBOOT" 241 "AP_TASK_PENDING_REBOOT" 240 "APS_DUAL_CAMERA_POWER_FAILURE" 239 "APS_SINGLE_CAMERA_POWER_FAILURE" 238 "APS_ETH_BRIDGE_DOWN" 237 "APS_PEER_PMIC_FAULTED" 236 "APS_SELF_PMIC_FAULTED" 235 "APS_PEER_VRM_FAULTED" 234 "APS_SELF_VRM_FAULTED" 233 "APS_PEER_IMEM_FAULTED" 232 "APS_SELF_IMEM_FAULTED" 231 "APS_PEER_CAN_FAULTED" 230 "APS_SELF_CAN_FAULTED" 229 "APS_B_UNHEALTHY" 228 "APS_A_UNHEALTHY" 227 "PEER_VISION_FAILOVER_ACTIVE" 226 "ARBITER_SELECTED_BEHAVIOR_OUT_OF_DATE" 225 "ARBITER_SELECTED_BEHAVIOR_NOT_E2E" 224 "MISSION_PLANNER_DESIRED_BEHAVIOR_NOT_E2E" 223 "AUTONOMY_CONTROLLING_AND_NOT_PARKED" 222 "NO_VALID_SGK_STATUS" 221 "AUTONOMOUS_BEHAVIORS_LINK_NOT_ESTABLISHED" 220 "GNSS_PPS_MIA" 219 "GNSS_ANTENNA_DISCONNECTED" 218 "GNSS_UART_FAULTED" 217 "AP_THERMAL_DEGRADED_PULLOVER_REQ" 216 "AP_THERMAL_DEGRADED_BLOCK_ACTIVATION" 215 "DRIVER_PRESENT_NOT_ALLOWED" 214 "UNSUPERVISED_OPERATION_NOT_ALLOWED" 213 "NOT_IN_RT_NO_TAKEOVER_FLEET" 212 "SAFETY_OPERATOR_NOT_PRESENT" 211 "CAMERA_PRECONDITIONING_REQUIRED" 210 "BMS_CAN_MESSAGES_MIA" 209 "VEHICLE_LOSING_HV" 208 "HV_DRIVE_NO_RESTART" 207 "AUTONOMOUS_BEHAVIORS_TASK_SUSPENDING" 206 "AUDIO_BUS_DOWN" 205 "CAMERA_REDUNDANCY_NOT_READY" 204 "NO_VEHICLE_SPEED_SOURCE_AVAILABLE" 203 "DI_PRIMARY_SPEED_SOURCE_UNAVAILABLE" 202 "DI_SPEED_CAN_MESSAGE_MIA" 201 "DEFOG_SYSTEM_UNHEALTHY" 200 "COOLANT_SYSTEM_UNHEALTHY" 199 "DEFOG_SYSTEM_NOT_READY" 198 "COOLANT_SYSTEM_NOT_READY" 197 "NOT_AUTHENTICATED_FOR_DRIVE" 196 "UNASSIGNED_PASSENGER_UNBUCKLED" 195 "WAITING_FOR_PASSENGER_EGRESS" 194 "PASSENGER_UNEXPECTED_RIDE_INACTIVE" 193 "DRIVER_NOT_PRESENT_PRE_ACTIVATION" 192 "NARROW_WASH_NOT_AVAILABLE" 191 "REDUNDANT_IMU_CAN_MESSAGES_MIA" 190 "IMU_CAN_MESSAGES_MIA" 189 "BRAKING_CAN_MESSAGES_MIA" 188 "EPB_AUTONOMY_CAN_MESSAGES_MIA" 187 "PARK_BRAKE_CAN_MESSAGES_MIA" 186 "STEERING_CAN_MESSAGES_MIA" 185 "DI_SYSTEM_STATUS_CAN_MESSAGES_MIA" 184 "DI_CHASSIS_CONTROL_CAN_MESSAGE_MIA" 183 "APS_CAN_MESSAGES_MIA" 182 "POOR_LOCALIZATION_ACCURACY" 181 "VISION_FAILOVER_ACTIVE" 180 "SEAT_OCCUPANCY_STATUS_UNHEALTHY" 179 "TO_STREAMS_UNHEALTHY" 178 "SEATBELT_STATUS_UNHEALTHY" 177 "RCM_WARNING_INDICATOR_ON" 176 "REDUNDANT_BRAKES_FAIL_OPERATIONAL" 175 "REDUNDANT_BRAKES_REDUNDANCY_LOST" 174 "REDUNDANT_BRAKES_NOT_ARMED" 173 "REDUNDANT_BRAKES_NOT_READY" 172 "REDUNDANT_BRAKE_PATH_ACTIVE" 171 "RANKER_NOT_HEALTHY" 170 "PARKED_A_PEDAL_PRESSED" 169 "ANY_CANCEL_ACTIVE" 168 "BRAKE_CONFIRM_PENDING_PARK" 167 "BRAKE_APPLIED_D_R_N" 166 "BRAKE_RELEASE_PENDING_PARK" 165 "ENFORCED_UNPARK_DELAY_ACTIVE" 164 "WIPER_NOT_HEALTHY" 163 "RIGHT_PILLAR_CAM_HEATER_FAULT" 162 "LEFT_PILLAR_CAM_HEATER_FAULT" 161 "WINDSHIELD_CAM_HEATER_FAULT" 160 "ALL_TAIL_LIGHTS_FAULTED_IN_LOW_VIS" 159 "TAIL_LIGHT_FAULTED" 158 "REVERSE_LIGHT_FAULTED" 157 "RIGHT_TURN_LIGHT_FAULTED" 156 "LEFT_TURN_LIGHT_FAULTED" 155 "ALL_BRAKE_LIGHTS_FAULTED" 154 "BRAKE_LIGHT_FAULTED" 153 "HIGH_BEAM_LIGHT_FAULTED_IN_LOW_VIS" 152 "LOW_BEAM_LIGHT_FAULTED_IN_LOW_VIS" 151 "HIGH_BEAM_LIGHT_FAULTED" 150 "LOW_BEAM_LIGHT_FAULTED" 149 "HEADLIGHTS_NOT_AIMED" 148 "HEADLIGHTS_OFF_AT_NIGHT" 147 "AP_REDUNDANCY_UNAVAILABLE" 146 "DI_BRAKING_DECELERATION_UNAVAILABLE" 145 "DI_VDC_ACTIVE" 144 "DI_TC_ACTIVE" 143 "DI_VDC_STATE_NOT_NORMAL" 142 "DI_LOSING_PROPULSION" 141 "EPB_STATUS_NOT_PARKED" 140 "EPB_PARKING_AVAILABILITY_UNKNOWN" 139 "EPB_PARKING_AVAILABILITY_REQUEST_PATH_DEGRADED" 138 "EPB_PARKING_AVAILABILITY_SPEED_INVALID" 137 "EPB_PARKING_AVAILABILITY_FAULTED" 136 "TIRE_PRESSURE_SENSOR_FAULT" 135 "FLAT_TIRE" 134 "INTEGRATOR_HEALTH_CRITICAL" 133 "IMU_DATA_NOT_RELIABLE" 132 "FASCIA_FLUID_CLEAN_CRITICAL" 131 "BACKUP_FLUID_CLEAN_CRITICAL" 130 "RIGHT_REPEATER_FLUID_CLEAN_CRITICAL" 129 "LEFT_REPEATER_FLUID_CLEAN_CRITICAL" 128 "FASCIA_AIR_CLEAN_CRITICAL" 127 "BACKUP_AIR_CLEAN_CRITICAL" 126 "RIGHT_REPEATER_AIR_CLEAN_CRITICAL" 125 "LEFT_REPEATER_AIR_CLEAN_CRITICAL" 124 "FASCIA_FLUID_CLEAN_DEGRADED" 123 "BACKUP_FLUID_CLEAN_DEGRADED" 122 "RIGHT_REPEATER_FLUID_CLEAN_DEGRADED" 121 "LEFT_REPEATER_FLUID_CLEAN_DEGRADED" 120 "FASCIA_AIR_CLEAN_DEGRADED" 119 "BACKUP_AIR_CLEAN_DEGRADED" 118 "RIGHT_REPEATER_AIR_CLEAN_DEGRADED" 117 "LEFT_REPEATER_AIR_CLEAN_DEGRADED" 116 "TERTIARY_WASHER_FLUID_LOW" 115 "SECONDARY_WASHER_FLUID_LOW" 114 "WASHER_FLUID_LOW" 113 "ELEVATED_TIRE_PRESSURE_READING" 112 "LOW_TIRE_PRESSURE_READING" 111 "VISION_CABIN_OCCUPANCY_UNAVAILABLE" 110 "SGK_AUTOSTEER_MONITOR_ACTIVE" 109 "SGK_PLANNER_ACTIVE_D_R_N" 108 "FLEET_MAINTENANCE_EXPIRING_SOON" 107 "FLEET_MAINTENANCE_REQUIRED" 106 "CHARGE_CABLE_CONNECTED_OR_STATUS_UNKNOWN" 105 "PASSENGER_UNBUCKLED_ACTIVE_RIDE" 104 "PASSENGER_UNBUCKLED" 103 "SYSTEM_UNHEALTHY_DEV_OVERRIDE" 102 "SINGLE_SOC_HEALTHY_EXCEPTION" 101 "IMU_REPLICATION_NOT_READY" 100 "STATE_MACHINE_DISABLED" 99 "INCOMPATIBLE_SYSTEM_HEALTH" 98 "CABIN_CAM_BLINDED" 97 "RIDESHARE_INGRESS_NO_NAV_ROUTE" 96 "PASSENGER_EXPECTED" 95 "DRIVER_MONITOR_STRIKEOUT" 94 "DRIVER_NOT_PRESENT" 93 "CONTROLLER_SOLVER_CRITICAL" 92 "CONTROLLER_SOLVER_DEGRADED" 91 "CONTROLLER_DEGRADED_PEDAL_OVERRIDE" 90 "CONTROLLER_SOLVER_FAILURE" 89 "LV_CRITICAL_STATE" 88 "LV_DEGRADED_STATE" 87 "VEHICLE_AUTONOMY_BEHAVIOR_MISMATCH" 86 "CRUISE_STACK_MISMATCH" 85 "EPB_REDUNDANT_BRAKING_STATUS" 84 "EXTENDED_COMPUTE_INACTIVE_OTHER" 83 "EXTENDED_COMPUTE_TIME_SYNC_CRITICAL_DEGRADED" 82 "EXTENDED_COMPUTE_OTHER_SOC_STATE_UNKNOWN" 81 "EXTENDED_COMPUTE_OTHER_SOC_STATE_INACTIVE" 80 "EXTENDED_COMPUTE_PCIE_LINK_HEALTH" 79 "EXTENDED_COMPUTE_ETHERNET_LINK_HEALTH" 78 "EXTENDED_COMPUTE_OTHER_SOC_HEALTH_CRITICAL" 77 "EXTENDED_COMPUTE_OTHER_SOC_HEALTH_UNKNOWN" 76 "EXTENDED_COMPUTE_SOC_HEALTH_CRITICAL" 75 "EXTENDED_COMPUTE_SOC_HEALTH_UNKNOWN" 74 "FSD_FROM_PARK_DISABLED" 73 "NOT_IN_PARK_NO_TAKEOVER" 72 "NO_FIXED_ROUTE" 71 "NAV_GOAL_INVALID" 70 "ANY_EPAS_FAULT" 69 "EPAS_SYSTEM_TORQUE_REDUCED" 68 "EPAS_SECONDARY_MASTER" 67 "EPAS_REDUNDANCY_LOST" 66 "EPAS_DRIVERLESS_MODE_NOT_ACTIVE" 65 "EPAS_EAC_NOT_ACTIVE" 64 "EPAS_EAC_UNAVAILABLE" 63 "STEERING_ANGLE_INVALID" 62 "CRUISE_FAULT" 61 "CRUISE_NOT_ACTIVE_OTHER" 60 "CRUISE_NOT_ACTIVE_ESTOP" 59 "CRUISE_UNAVAILABLE_OTHER" 58 "CRUISE_UNAVAILABLE_BRAKE_APPLIED" 57 "NOT_POWER_STATE_DRIVE" 56 "FRUNK_OPEN" 55 "TRUNK_OPEN" 54 "PASSENGER_DOOR_OPEN" 53 "DRIVER_DOOR_OPEN" 52 "VISION_FPS_LOW_CAMERA_DROPS" 51 "VISION_LATENCY_HIGH" 50 "SAFETY_DRIVER_UNBUCKLED" 49 "FASCIA_VISION_OCCLUSION_AT_STOP" 48 "SEVERE_RIGHT_VISION_OCCLUSION_REVERSE" 47 "SEVERE_LEFT_VISION_OCCLUSION_REVERSE" 46 "SEVERE_BACKUP_VISION_OCCLUSION_REVERSE" 45 "SEVERE_RIGHT_VISION_OCCLUSION_MANEUVER" 44 "SEVERE_LEFT_VISION_OCCLUSION_MANEUVER" 43 "SEVERE_RIGHT_VISION_OCCLUSION" 42 "SEVERE_LEFT_VISION_OCCLUSION" 41 "SEVERE_MULTIPLE_FRONT_VISION_OCCLUSION" 40 "SEVERE_SINGLE_FRONT_VISION_OCCLUSION" 39 "CAMERA_HEALTH_METRICS_UNHEALTHY" 38 "VISION_SCENETAGS_UNHEALTHY" 37 "VISION_AUTOWIPER_UNHEALTHY" 36 "VISION_AUTOHIGHBEAM_UNHEALTHY" 35 "VISION_FAILSAFES_UNHEALTHY" 34 "RIGHT_VISION_FAILSAFE_PARKED" 33 "LEFT_VISION_FAILSAFE_PARKED" 32 "FRONT_VISION_FAILSAFE_PARKED" 31 "REAR_VISION_FAILSAFE_PARKED" 30 "CAMERA_OFFGASSING" 29 "CAMERA_OFFGASSING_PRE_ALERT" 28 "INTERMITTENT_FRAME_DROPS" 27 "CAMERA_AUTOEXPOSURE_LOST" 26 "OUT_OF_SYNC_CAMERA_STREAMS" 25 "FASCIA_CAMERA_STREAM_LOST" 24 "BACKUP_CAMERA_STREAM_LOST" 23 "RIGHT_CAMERAS_STREAM_LOST" 22 "LEFT_CAMERAS_STREAM_LOST" 21 "FRONT_CAMERAS_STREAM_LOST" 20 "CAMERA_MCU_FW_MISMATCH" 19 "FACTORY_CALIBRATION" 18 "CAMERA_PITCH_OUT_OF_BOUNDS" 17 "CAMERA_CALIBRATION" 16 "GNSS_DEGRADED_SIGNAL_STRENGTH" 15 "AP_POWER_REQUEST_NOT_NOMINAL" 14 "SENTRY_ACTIVE" 13 "NO_REDUNDANT_BRAKING" 12 "HK_RESTRICTED" 11 "OUTSIDE_GEOFENCE" 10 "RUN_MODE_NOT_FSD" 9 "AEB_ACTIVE" 8 "SUMMON_ACTIVE" 7 "AUTOPARK_ACTIVE" 6 "FSD_DISABLED" 5 "CAR_WASH_MODE" 4 "DELIVERED" 3 "NO_AUTONOMY_MODE_ACTIVE" 2 "NEUTRAL_GEAR" 1 "NONE" 0 "UNKNOWN" ;
VAL_ 1513 APP_sw457_reason2 414 "TRAJECTORY_ON_PUBLIC_ROAD_NOT_INDOORS" 413 "STOP_IN_LANE_NOT_HONORED" 412 "SIMPLE_SUMMON_OBSTACLE_BLOCKED" 411 "SEVERE_SINGLE_FRONT_VISION_OCCLUSION_AFTER_WIPE" 410 "PHONE_TOO_FAR_TO_START" 409 "MAX_SPEED_LIMIT_FOR_MODE_EXCEEDED" 408 "EPB_REDUNDANT_BRAKING_UNAVAILABLE" 407 "EGO_GEAR_NOT_ALLOWED" 406 "EGO_EXCEEDED_MAX_SUMMON_DISTANCE" 405 "DUAL_EPB_UNAVAILABLE" 404 "COMPRESSOR_FRAME_DROP_RATE_HIGH" 403 "CAN_RX_VALIDATION_ERROR" 402 "BRAKE_APPLIED_PARKED" 401 "ALARM_ACTIVE" 400 "SAFETY_DRIVER_UNBUCKLED_PRE_ACTIVATION" 399 "NOT_FACTORY_SCHEDULE" 398 "FSD_REGION_NOT_ALLOWED" 397 "FSD_QUIZ_REQUIRED" 396 "EPAS_EAC_NOT_ACTIVE_OTHER" 395 "EPAS_EAC_NOT_ACTIVE_HANDS_ON" 394 "DI_CONTROL_INTEGRATOR_WINDUP" 393 "SEVERE_SINGLE_FRONT_VISION_OCCLUSION_HIGH_FOGGING_RISK" 392 "EGO_NEAR_SUMMON_MAP_BOUNDARY_NOT_INDOORS" 391 "GOAL_NEAR_SUMMON_MAP_BOUNDARY_NOT_INDOORS" 390 "GRADE_TOO_HIGH_WITHOUT_REDUNDANT_BRAKING_LOW_MU" 389 "NAV_DESTINATION_OUTSIDE_GEOFENCE" 388 "RCM_COLLISION_SEVERITY_TRIGGERED" 387 "EPB_PARKING_AVAILABILITY_TOO_STEEP" 386 "REVERSE_GEAR_NOT_AVAILABLE" 385 "DESTINATION_OUTSIDE_GEOFENCE_AP" 384 "SSD_CLIP_LOGGING_CRITICAL" 383 "DRIVE_GEAR_NOT_AVAILABLE" 382 "SIDE_VISIBILITY_DEGRADED_PARKED_DOORS_CLOSED" 381 "PERSISTENT_FRAME_DROPS" 380 "PERSISTENT_HANDS_ON_NOT_ALLOWED" 379 "NAV_ROUTE_EXCEEDS_GEOFENCE_BUFFER" 378 "RANKER_OUTPUT_STALE" 377 "VISION_PLANNER_STALE" 376 "AUTO_WIPERS_OFF" 375 "COUNTRY_NOT_ALLOWED_FOR_OPERATION" 374 "OUTSIDE_TRACK_TEST_GEOFENCE" 373 "TEMPERATURE_EXCEEDS_ODD" 372 "RIDESHARE_NAV_GOAL_NOT_IN_SYNC" 371 "HV_BATTERY_AC_CHARGING_UNHEALTHY" 370 "HV_BATTERY_DC_CHARGING_UNHEALTHY" 369 "UI_RIDE_SETUP_IN_PROGRESS" 368 "AUTO_HEADLIGHTS_OFF" 367 "IMMOBILIZER_AUTH_AUTONOMY" 366 "DI_RESTRICTED_DRIVING_MANUAL_RECOVERY" 365 "SUMMON_ACTIVE_DURATION_EXCEEDED" 364 "ESKF_SPEED_SOURCE_ACTIVE" 363 "IMU_DATA_NOT_RELIABLE_WITH_FLEET_CONFIG_ENABLED" 362 "FASCIA_VISION_OCCLUSION_AT_LONG_STOP" 361 "HIGH_SPEED_ROAD_ON_ROUTE" 360 "EGO_ON_HIGH_SPEED_ROAD" 359 "UNACCOMPANIED_UNDERAGE_RIDER_DETECTED" 358 "AEB_FAULTED" 357 "AUDIO_HARDWARE_ODIN_FAILED" 356 "FASCIA_VISION_FAILSAFE_PARKED" 355 "APS_B_EPLANNER_NO_VALID_TRAJECTORY" 354 "APS_A_EPLANNER_NO_VALID_TRAJECTORY" 353 "FASCIA_CAM_INTEGRATED_HEATER_FAULT" 352 "BACKUP_CAM_INTEGRATED_HEATER_FAULT" 351 "RIGHT_REPEATER_CAM_INTEGRATED_HEATER_FAULT" 350 "LEFT_REPEATER_CAM_INTEGRATED_HEATER_FAULT" 349 "RIGHT_PILLAR_CAM_INTEGRATED_HEATER_FAULT" 348 "LEFT_PILLAR_CAM_INTEGRATED_HEATER_FAULT" 347 "RIGHT_PILLAR_CAM_WIRE_HEATER_FAULT" 346 "LEFT_PILLAR_CAM_WIRE_HEATER_FAULT" 345 "WINDSHIELD_CAM_WIRE_HEATER_FAULT" 344 "CONTROLLER_EPLANNER_UNHEALTHY" 343 "VEHICLE_COLLISION_DETECTED" 342 "VRU_COLLISION_DETECTED" 341 "MAJOR_COLLISION_DETECTED" 340 "ONGOING_COLLISION_DETECTED" 339 "INTEGRATOR_ACCELERATION_INVALID" 338 "CABIN_CAM_DRIVER_MONITORING_SYSTEM_UNAVAILABLE" 337 "DCAS_DRIVER_ATTENTION_STATE_DETERMINATION_DEGRADED" 336 "NON_MAIN_FRONT_CAMERAS_STREAM_LOST" 335 "MAIN_CAMERA_STREAM_LOST" 334 "DRIVER_WIPER_WASH_HEALTH_DEGRADED" 333 "EPB_AUTONOMY_BEHAVIOR_MISMATCH" 332 "DI_AUTONOMY_BEHAVIOR_MISMATCH" 331 "VC_AUTONOMY_BEHAVIOR_MISMATCH" 330 "DCAS_EXITED_REGION_TIMEOUT" 329 "WASHER_PUMP_NOT_HEALTHY" 328 "AP_B_SOC_UNHEALTHY" 327 "RCM_AIR_BAG_DEPLOY" 326 "RCM_NEAR_DEPLOY" 325 "AP_A_SOC_UNHEALTHY" 324 "ROUTE_EXCEEDS_SPEED_LIMIT" 323 "PERSISTENT_INVALID_NAV_ROUTE" 322 "NAV_ROUTE_EXITS_GEOFENCE" 321 "NAV_AVOID_HIGH_SPEED_ROADS_DISABLED" 320 "NAV_WHITELIST_ROUTING_DISABLED" 319 "NAV_ROUTE_RANKER_DISABLED" 318 "NAV_AVOID_SHORT_LANE_CHANGE_DISABLED" 317 "NAV_AVOID_UNPROTECTED_TURN_DISABLED" 316 "HIGHWAY_ON_ROUTE" 315 "EGO_ON_HIGHWAY" 314 "INVALID_VEHICLE_OPERATION_MODE" 313 "STEERING_ANGLE_OFFSET_HIGH" 312 "SAFETY_DRIVER_INATTENTIVE" 311 "TRACK_MODE_ACTIVE" 310 "EXT_TEMP_LOW_CERAMIC_BRAKES" 309 "GOAL_NEAR_SUMMON_MAP_BOUNDARY" 308 "SUMMON_HEARTBEAT_MISSING" 307 "EGO_NEAR_SUMMON_MAP_BOUNDARY" 306 "EGO_OUTSIDE_SUMMON_MAP_RADIUS" 305 "SUMMON_MAP_INVALID" 304 "RAW_UI_SUMMON_GOAL_INVALID" 303 "SUMMON_GOAL_INVALID" 302 "SYSTEM_CDP_UNAVAILABLE" 301 "SUMMON_COLLISION_DETECTION_ACTIVE" 300 "PHONE_TOO_FAR" 299 "PHONE_GPS_INVALID" 298 "GRADE_TOO_HIGH_WITHOUT_REDUNDANT_BRAKING" 297 "CABIN_CAM_DRIVER_MONITORING_UNAVAILABLE" 296 "CABIN_CAMERA_STREAM_FAILURE" 295 "DRIVER_PRESENCE_VISION_UNAVAILABLE" 294 "PEDAL_OVERRIDE_EXCEEDS_CONTROLLER_LIMITS" 293 "UPCOMING_FERRY_CROSSING" 292 "DRIVER_PARTIALLY_OCCLUDED" 291 "DRIVER_REQUIREMENTS_NOT_MET_VC" 290 "DRIVER_AGE_REQUIREMENTS_NOT_MET_VISION" 289 "GPS_DEGRADED" 288 "PILLARS_SWAP_DETECTED" 287 "NARROW_FISHEYE_SWAP_DETECTED" 286 "SCCM_MIA" 285 "RECENT_STALK_GEAR_SHIFT" 284 "IBOOSTER_MIA" 283 "PARKING_SPOT_SELECTED" 282 "SCROLL_WHEEL_INTERACTION" 281 "PEDAL_OVERRIDE_STRIKEOUT_FOR_DRIVE" 280 "PEDAL_OVERRIDE_STRIKEOUT" 279 "ABOVE_MAX_ACTIVATION_SPEED" 278 "DRIVER_MONITOR_SUSPENSION_ACTIVE" 277 "DRIVER_MONITOR_STRUCK_OUT_FOR_DRIVE" 276 "VC_CAMERA_AIR_CLEANING_STATUS_MIA" 275 "VC_CAMERA_FLUID_CLEANING_STATUS_MIA" 274 "INVALID_DI_PEDAL_POS" 273 "CABIN_CAMERA_FAN_RPM_FAULT" 272 "SELF_NETWORK_DECRYPTION_NOT_READY" 271 "OFF_ROAD_MODE_ACTIVE" 270 "SSD_CLIP_LOGGING_INACTIVE" 269 "CAMERA_EXPOSURE_INACTIVE" 268 "CAMERA_EXPOSURE_MISMATCH" 267 "CABIN_CAMERA_IR_LED_FAULTED" 266 "TAMPERING_DETECTED" 265 "NO_IMU_SOURCES_AVAILABLE" 264 "IMU_REDUNDANCY_LOST" 263 "DI_AUTONOMY_HEALTH_CAN_MESSAGE_MIA" 262 "ALL_WHEEL_SPEEDS_SENSORS_FAULTED" 261 "WHEEL_SPEEDS_CAN_MESSAGE_MIA" 260 "AP_THERMAL_MODEL_FAULT_DETECTED" 259 "SGK_AUTONOMY_MODE_NOT_IN_SYNC" 258 "SGK_AUTONOMY_STATE_NOT_IN_SYNC" 257 "ANY_RIGHT_DOOR_OPEN_BUTTON_FAULTED" 256 "ANY_LEFT_DOOR_OPEN_BUTTON_FAULTED" 255 "VCRIGHT_DOOR_STATUS_CAN_MESSAGE_MIA" 254 "VCLEFT_DOOR_STATUS_CAN_MESSAGE_MIA" 253 "BB_STATUS_CAN_MESSAGE_MIA" 252 "GTW_CAR_CONFIG_CAN_MESSAGE_MIA" 251 "TRAILER_MODE_ACTIVE" 250 "UI_LIMIT_MODE_ACTIVE" 249 "UI_QT_CAR_UNAVAILABLE" 248 "UI_CONNECTIVITY_HW_UNHEALTHY" 247 "UI_CONNECTIVITY_OFFLINE" 246 "UI_CENTER_DISPLAY_UNAVAILABLE" 245 "UI_HEALTH_STATUS_CAN_MESSAGE_MIA" 244 "ANY_LV_HEALTH_CAN_MESSAGE_INVALID" 243 "ANY_LV_HEALTH_CAN_MESSAGE_MIA" 242 "AP_SYSTEM_ISSUE_PENDING_REBOOT" 241 "AP_TASK_PENDING_REBOOT" 240 "APS_DUAL_CAMERA_POWER_FAILURE" 239 "APS_SINGLE_CAMERA_POWER_FAILURE" 238 "APS_ETH_BRIDGE_DOWN" 237 "APS_PEER_PMIC_FAULTED" 236 "APS_SELF_PMIC_FAULTED" 235 "APS_PEER_VRM_FAULTED" 234 "APS_SELF_VRM_FAULTED" 233 "APS_PEER_IMEM_FAULTED" 232 "APS_SELF_IMEM_FAULTED" 231 "APS_PEER_CAN_FAULTED" 230 "APS_SELF_CAN_FAULTED" 229 "APS_B_UNHEALTHY" 228 "APS_A_UNHEALTHY" 227 "PEER_VISION_FAILOVER_ACTIVE" 226 "ARBITER_SELECTED_BEHAVIOR_OUT_OF_DATE" 225 "ARBITER_SELECTED_BEHAVIOR_NOT_E2E" 224 "MISSION_PLANNER_DESIRED_BEHAVIOR_NOT_E2E" 223 "AUTONOMY_CONTROLLING_AND_NOT_PARKED" 222 "NO_VALID_SGK_STATUS" 221 "AUTONOMOUS_BEHAVIORS_LINK_NOT_ESTABLISHED" 220 "GNSS_PPS_MIA" 219 "GNSS_ANTENNA_DISCONNECTED" 218 "GNSS_UART_FAULTED" 217 "AP_THERMAL_DEGRADED_PULLOVER_REQ" 216 "AP_THERMAL_DEGRADED_BLOCK_ACTIVATION" 215 "DRIVER_PRESENT_NOT_ALLOWED" 214 "UNSUPERVISED_OPERATION_NOT_ALLOWED" 213 "NOT_IN_RT_NO_TAKEOVER_FLEET" 212 "SAFETY_OPERATOR_NOT_PRESENT" 211 "CAMERA_PRECONDITIONING_REQUIRED" 210 "BMS_CAN_MESSAGES_MIA" 209 "VEHICLE_LOSING_HV" 208 "HV_DRIVE_NO_RESTART" 207 "AUTONOMOUS_BEHAVIORS_TASK_SUSPENDING" 206 "AUDIO_BUS_DOWN" 205 "CAMERA_REDUNDANCY_NOT_READY" 204 "NO_VEHICLE_SPEED_SOURCE_AVAILABLE" 203 "DI_PRIMARY_SPEED_SOURCE_UNAVAILABLE" 202 "DI_SPEED_CAN_MESSAGE_MIA" 201 "DEFOG_SYSTEM_UNHEALTHY" 200 "COOLANT_SYSTEM_UNHEALTHY" 199 "DEFOG_SYSTEM_NOT_READY" 198 "COOLANT_SYSTEM_NOT_READY" 197 "NOT_AUTHENTICATED_FOR_DRIVE" 196 "UNASSIGNED_PASSENGER_UNBUCKLED" 195 "WAITING_FOR_PASSENGER_EGRESS" 194 "PASSENGER_UNEXPECTED_RIDE_INACTIVE" 193 "DRIVER_NOT_PRESENT_PRE_ACTIVATION" 192 "NARROW_WASH_NOT_AVAILABLE" 191 "REDUNDANT_IMU_CAN_MESSAGES_MIA" 190 "IMU_CAN_MESSAGES_MIA" 189 "BRAKING_CAN_MESSAGES_MIA" 188 "EPB_AUTONOMY_CAN_MESSAGES_MIA" 187 "PARK_BRAKE_CAN_MESSAGES_MIA" 186 "STEERING_CAN_MESSAGES_MIA" 185 "DI_SYSTEM_STATUS_CAN_MESSAGES_MIA" 184 "DI_CHASSIS_CONTROL_CAN_MESSAGE_MIA" 183 "APS_CAN_MESSAGES_MIA" 182 "POOR_LOCALIZATION_ACCURACY" 181 "VISION_FAILOVER_ACTIVE" 180 "SEAT_OCCUPANCY_STATUS_UNHEALTHY" 179 "TO_STREAMS_UNHEALTHY" 178 "SEATBELT_STATUS_UNHEALTHY" 177 "RCM_WARNING_INDICATOR_ON" 176 "REDUNDANT_BRAKES_FAIL_OPERATIONAL" 175 "REDUNDANT_BRAKES_REDUNDANCY_LOST" 174 "REDUNDANT_BRAKES_NOT_ARMED" 173 "REDUNDANT_BRAKES_NOT_READY" 172 "REDUNDANT_BRAKE_PATH_ACTIVE" 171 "RANKER_NOT_HEALTHY" 170 "PARKED_A_PEDAL_PRESSED" 169 "ANY_CANCEL_ACTIVE" 168 "BRAKE_CONFIRM_PENDING_PARK" 167 "BRAKE_APPLIED_D_R_N" 166 "BRAKE_RELEASE_PENDING_PARK" 165 "ENFORCED_UNPARK_DELAY_ACTIVE" 164 "WIPER_NOT_HEALTHY" 163 "RIGHT_PILLAR_CAM_HEATER_FAULT" 162 "LEFT_PILLAR_CAM_HEATER_FAULT" 161 "WINDSHIELD_CAM_HEATER_FAULT" 160 "ALL_TAIL_LIGHTS_FAULTED_IN_LOW_VIS" 159 "TAIL_LIGHT_FAULTED" 158 "REVERSE_LIGHT_FAULTED" 157 "RIGHT_TURN_LIGHT_FAULTED" 156 "LEFT_TURN_LIGHT_FAULTED" 155 "ALL_BRAKE_LIGHTS_FAULTED" 154 "BRAKE_LIGHT_FAULTED" 153 "HIGH_BEAM_LIGHT_FAULTED_IN_LOW_VIS" 152 "LOW_BEAM_LIGHT_FAULTED_IN_LOW_VIS" 151 "HIGH_BEAM_LIGHT_FAULTED" 150 "LOW_BEAM_LIGHT_FAULTED" 149 "HEADLIGHTS_NOT_AIMED" 148 "HEADLIGHTS_OFF_AT_NIGHT" 147 "AP_REDUNDANCY_UNAVAILABLE" 146 "DI_BRAKING_DECELERATION_UNAVAILABLE" 145 "DI_VDC_ACTIVE" 144 "DI_TC_ACTIVE" 143 "DI_VDC_STATE_NOT_NORMAL" 142 "DI_LOSING_PROPULSION" 141 "EPB_STATUS_NOT_PARKED" 140 "EPB_PARKING_AVAILABILITY_UNKNOWN" 139 "EPB_PARKING_AVAILABILITY_REQUEST_PATH_DEGRADED" 138 "EPB_PARKING_AVAILABILITY_SPEED_INVALID" 137 "EPB_PARKING_AVAILABILITY_FAULTED" 136 "TIRE_PRESSURE_SENSOR_FAULT" 135 "FLAT_TIRE" 134 "INTEGRATOR_HEALTH_CRITICAL" 133 "IMU_DATA_NOT_RELIABLE" 132 "FASCIA_FLUID_CLEAN_CRITICAL" 131 "BACKUP_FLUID_CLEAN_CRITICAL" 130 "RIGHT_REPEATER_FLUID_CLEAN_CRITICAL" 129 "LEFT_REPEATER_FLUID_CLEAN_CRITICAL" 128 "FASCIA_AIR_CLEAN_CRITICAL" 127 "BACKUP_AIR_CLEAN_CRITICAL" 126 "RIGHT_REPEATER_AIR_CLEAN_CRITICAL" 125 "LEFT_REPEATER_AIR_CLEAN_CRITICAL" 124 "FASCIA_FLUID_CLEAN_DEGRADED" 123 "BACKUP_FLUID_CLEAN_DEGRADED" 122 "RIGHT_REPEATER_FLUID_CLEAN_DEGRADED" 121 "LEFT_REPEATER_FLUID_CLEAN_DEGRADED" 120 "FASCIA_AIR_CLEAN_DEGRADED" 119 "BACKUP_AIR_CLEAN_DEGRADED" 118 "RIGHT_REPEATER_AIR_CLEAN_DEGRADED" 117 "LEFT_REPEATER_AIR_CLEAN_DEGRADED" 116 "TERTIARY_WASHER_FLUID_LOW" 115 "SECONDARY_WASHER_FLUID_LOW" 114 "WASHER_FLUID_LOW" 113 "ELEVATED_TIRE_PRESSURE_READING" 112 "LOW_TIRE_PRESSURE_READING" 111 "VISION_CABIN_OCCUPANCY_UNAVAILABLE" 110 "SGK_AUTOSTEER_MONITOR_ACTIVE" 109 "SGK_PLANNER_ACTIVE_D_R_N" 108 "FLEET_MAINTENANCE_EXPIRING_SOON" 107 "FLEET_MAINTENANCE_REQUIRED" 106 "CHARGE_CABLE_CONNECTED_OR_STATUS_UNKNOWN" 105 "PASSENGER_UNBUCKLED_ACTIVE_RIDE" 104 "PASSENGER_UNBUCKLED" 103 "SYSTEM_UNHEALTHY_DEV_OVERRIDE" 102 "SINGLE_SOC_HEALTHY_EXCEPTION" 101 "IMU_REPLICATION_NOT_READY" 100 "STATE_MACHINE_DISABLED" 99 "INCOMPATIBLE_SYSTEM_HEALTH" 98 "CABIN_CAM_BLINDED" 97 "RIDESHARE_INGRESS_NO_NAV_ROUTE" 96 "PASSENGER_EXPECTED" 95 "DRIVER_MONITOR_STRIKEOUT" 94 "DRIVER_NOT_PRESENT" 93 "CONTROLLER_SOLVER_CRITICAL" 92 "CONTROLLER_SOLVER_DEGRADED" 91 "CONTROLLER_DEGRADED_PEDAL_OVERRIDE" 90 "CONTROLLER_SOLVER_FAILURE" 89 "LV_CRITICAL_STATE" 88 "LV_DEGRADED_STATE" 87 "VEHICLE_AUTONOMY_BEHAVIOR_MISMATCH" 86 "CRUISE_STACK_MISMATCH" 85 "EPB_REDUNDANT_BRAKING_STATUS" 84 "EXTENDED_COMPUTE_INACTIVE_OTHER" 83 "EXTENDED_COMPUTE_TIME_SYNC_CRITICAL_DEGRADED" 82 "EXTENDED_COMPUTE_OTHER_SOC_STATE_UNKNOWN" 81 "EXTENDED_COMPUTE_OTHER_SOC_STATE_INACTIVE" 80 "EXTENDED_COMPUTE_PCIE_LINK_HEALTH" 79 "EXTENDED_COMPUTE_ETHERNET_LINK_HEALTH" 78 "EXTENDED_COMPUTE_OTHER_SOC_HEALTH_CRITICAL" 77 "EXTENDED_COMPUTE_OTHER_SOC_HEALTH_UNKNOWN" 76 "EXTENDED_COMPUTE_SOC_HEALTH_CRITICAL" 75 "EXTENDED_COMPUTE_SOC_HEALTH_UNKNOWN" 74 "FSD_FROM_PARK_DISABLED" 73 "NOT_IN_PARK_NO_TAKEOVER" 72 "NO_FIXED_ROUTE" 71 "NAV_GOAL_INVALID" 70 "ANY_EPAS_FAULT" 69 "EPAS_SYSTEM_TORQUE_REDUCED" 68 "EPAS_SECONDARY_MASTER" 67 "EPAS_REDUNDANCY_LOST" 66 "EPAS_DRIVERLESS_MODE_NOT_ACTIVE" 65 "EPAS_EAC_NOT_ACTIVE" 64 "EPAS_EAC_UNAVAILABLE" 63 "STEERING_ANGLE_INVALID" 62 "CRUISE_FAULT" 61 "CRUISE_NOT_ACTIVE_OTHER" 60 "CRUISE_NOT_ACTIVE_ESTOP" 59 "CRUISE_UNAVAILABLE_OTHER" 58 "CRUISE_UNAVAILABLE_BRAKE_APPLIED" 57 "NOT_POWER_STATE_DRIVE" 56 "FRUNK_OPEN" 55 "TRUNK_OPEN" 54 "PASSENGER_DOOR_OPEN" 53 "DRIVER_DOOR_OPEN" 52 "VISION_FPS_LOW_CAMERA_DROPS" 51 "VISION_LATENCY_HIGH" 50 "SAFETY_DRIVER_UNBUCKLED" 49 "FASCIA_VISION_OCCLUSION_AT_STOP" 48 "SEVERE_RIGHT_VISION_OCCLUSION_REVERSE" 47 "SEVERE_LEFT_VISION_OCCLUSION_REVERSE" 46 "SEVERE_BACKUP_VISION_OCCLUSION_REVERSE" 45 "SEVERE_RIGHT_VISION_OCCLUSION_MANEUVER" 44 "SEVERE_LEFT_VISION_OCCLUSION_MANEUVER" 43 "SEVERE_RIGHT_VISION_OCCLUSION" 42 "SEVERE_LEFT_VISION_OCCLUSION" 41 "SEVERE_MULTIPLE_FRONT_VISION_OCCLUSION" 40 "SEVERE_SINGLE_FRONT_VISION_OCCLUSION" 39 "CAMERA_HEALTH_METRICS_UNHEALTHY" 38 "VISION_SCENETAGS_UNHEALTHY" 37 "VISION_AUTOWIPER_UNHEALTHY" 36 "VISION_AUTOHIGHBEAM_UNHEALTHY" 35 "VISION_FAILSAFES_UNHEALTHY" 34 "RIGHT_VISION_FAILSAFE_PARKED" 33 "LEFT_VISION_FAILSAFE_PARKED" 32 "FRONT_VISION_FAILSAFE_PARKED" 31 "REAR_VISION_FAILSAFE_PARKED" 30 "CAMERA_OFFGASSING" 29 "CAMERA_OFFGASSING_PRE_ALERT" 28 "INTERMITTENT_FRAME_DROPS" 27 "CAMERA_AUTOEXPOSURE_LOST" 26 "OUT_OF_SYNC_CAMERA_STREAMS" 25 "FASCIA_CAMERA_STREAM_LOST" 24 "BACKUP_CAMERA_STREAM_LOST" 23 "RIGHT_CAMERAS_STREAM_LOST" 22 "LEFT_CAMERAS_STREAM_LOST" 21 "FRONT_CAMERAS_STREAM_LOST" 20 "CAMERA_MCU_FW_MISMATCH" 19 "FACTORY_CALIBRATION" 18 "CAMERA_PITCH_OUT_OF_BOUNDS" 17 "CAMERA_CALIBRATION" 16 "GNSS_DEGRADED_SIGNAL_STRENGTH" 15 "AP_POWER_REQUEST_NOT_NOMINAL" 14 "SENTRY_ACTIVE" 13 "NO_REDUNDANT_BRAKING" 12 "HK_RESTRICTED" 11 "OUTSIDE_GEOFENCE" 10 "RUN_MODE_NOT_FSD" 9 "AEB_ACTIVE" 8 "SUMMON_ACTIVE" 7 "AUTOPARK_ACTIVE" 6 "FSD_DISABLED" 5 "CAR_WASH_MODE" 4 "DELIVERED" 3 "NO_AUTONOMY_MODE_ACTIVE" 2 "NEUTRAL_GEAR" 1 "NONE" 0 "UNKNOWN" ;
VAL_ 1513 APP_sw457_reason3 414 "TRAJECTORY_ON_PUBLIC_ROAD_NOT_INDOORS" 413 "STOP_IN_LANE_NOT_HONORED" 412 "SIMPLE_SUMMON_OBSTACLE_BLOCKED" 411 "SEVERE_SINGLE_FRONT_VISION_OCCLUSION_AFTER_WIPE" 410 "PHONE_TOO_FAR_TO_START" 409 "MAX_SPEED_LIMIT_FOR_MODE_EXCEEDED" 408 "EPB_REDUNDANT_BRAKING_UNAVAILABLE" 407 "EGO_GEAR_NOT_ALLOWED" 406 "EGO_EXCEEDED_MAX_SUMMON_DISTANCE" 405 "DUAL_EPB_UNAVAILABLE" 404 "COMPRESSOR_FRAME_DROP_RATE_HIGH" 403 "CAN_RX_VALIDATION_ERROR" 402 "BRAKE_APPLIED_PARKED" 401 "ALARM_ACTIVE" 400 "SAFETY_DRIVER_UNBUCKLED_PRE_ACTIVATION" 399 "NOT_FACTORY_SCHEDULE" 398 "FSD_REGION_NOT_ALLOWED" 397 "FSD_QUIZ_REQUIRED" 396 "EPAS_EAC_NOT_ACTIVE_OTHER" 395 "EPAS_EAC_NOT_ACTIVE_HANDS_ON" 394 "DI_CONTROL_INTEGRATOR_WINDUP" 393 "SEVERE_SINGLE_FRONT_VISION_OCCLUSION_HIGH_FOGGING_RISK" 392 "EGO_NEAR_SUMMON_MAP_BOUNDARY_NOT_INDOORS" 391 "GOAL_NEAR_SUMMON_MAP_BOUNDARY_NOT_INDOORS" 390 "GRADE_TOO_HIGH_WITHOUT_REDUNDANT_BRAKING_LOW_MU" 389 "NAV_DESTINATION_OUTSIDE_GEOFENCE" 388 "RCM_COLLISION_SEVERITY_TRIGGERED" 387 "EPB_PARKING_AVAILABILITY_TOO_STEEP" 386 "REVERSE_GEAR_NOT_AVAILABLE" 385 "DESTINATION_OUTSIDE_GEOFENCE_AP" 384 "SSD_CLIP_LOGGING_CRITICAL" 383 "DRIVE_GEAR_NOT_AVAILABLE" 382 "SIDE_VISIBILITY_DEGRADED_PARKED_DOORS_CLOSED" 381 "PERSISTENT_FRAME_DROPS" 380 "PERSISTENT_HANDS_ON_NOT_ALLOWED" 379 "NAV_ROUTE_EXCEEDS_GEOFENCE_BUFFER" 378 "RANKER_OUTPUT_STALE" 377 "VISION_PLANNER_STALE" 376 "AUTO_WIPERS_OFF" 375 "COUNTRY_NOT_ALLOWED_FOR_OPERATION" 374 "OUTSIDE_TRACK_TEST_GEOFENCE" 373 "TEMPERATURE_EXCEEDS_ODD" 372 "RIDESHARE_NAV_GOAL_NOT_IN_SYNC" 371 "HV_BATTERY_AC_CHARGING_UNHEALTHY" 370 "HV_BATTERY_DC_CHARGING_UNHEALTHY" 369 "UI_RIDE_SETUP_IN_PROGRESS" 368 "AUTO_HEADLIGHTS_OFF" 367 "IMMOBILIZER_AUTH_AUTONOMY" 366 "DI_RESTRICTED_DRIVING_MANUAL_RECOVERY" 365 "SUMMON_ACTIVE_DURATION_EXCEEDED" 364 "ESKF_SPEED_SOURCE_ACTIVE" 363 "IMU_DATA_NOT_RELIABLE_WITH_FLEET_CONFIG_ENABLED" 362 "FASCIA_VISION_OCCLUSION_AT_LONG_STOP" 361 "HIGH_SPEED_ROAD_ON_ROUTE" 360 "EGO_ON_HIGH_SPEED_ROAD" 359 "UNACCOMPANIED_UNDERAGE_RIDER_DETECTED" 358 "AEB_FAULTED" 357 "AUDIO_HARDWARE_ODIN_FAILED" 356 "FASCIA_VISION_FAILSAFE_PARKED" 355 "APS_B_EPLANNER_NO_VALID_TRAJECTORY" 354 "APS_A_EPLANNER_NO_VALID_TRAJECTORY" 353 "FASCIA_CAM_INTEGRATED_HEATER_FAULT" 352 "BACKUP_CAM_INTEGRATED_HEATER_FAULT" 351 "RIGHT_REPEATER_CAM_INTEGRATED_HEATER_FAULT" 350 "LEFT_REPEATER_CAM_INTEGRATED_HEATER_FAULT" 349 "RIGHT_PILLAR_CAM_INTEGRATED_HEATER_FAULT" 348 "LEFT_PILLAR_CAM_INTEGRATED_HEATER_FAULT" 347 "RIGHT_PILLAR_CAM_WIRE_HEATER_FAULT" 346 "LEFT_PILLAR_CAM_WIRE_HEATER_FAULT" 345 "WINDSHIELD_CAM_WIRE_HEATER_FAULT" 344 "CONTROLLER_EPLANNER_UNHEALTHY" 343 "VEHICLE_COLLISION_DETECTED" 342 "VRU_COLLISION_DETECTED" 341 "MAJOR_COLLISION_DETECTED" 340 "ONGOING_COLLISION_DETECTED" 339 "INTEGRATOR_ACCELERATION_INVALID" 338 "CABIN_CAM_DRIVER_MONITORING_SYSTEM_UNAVAILABLE" 337 "DCAS_DRIVER_ATTENTION_STATE_DETERMINATION_DEGRADED" 336 "NON_MAIN_FRONT_CAMERAS_STREAM_LOST" 335 "MAIN_CAMERA_STREAM_LOST" 334 "DRIVER_WIPER_WASH_HEALTH_DEGRADED" 333 "EPB_AUTONOMY_BEHAVIOR_MISMATCH" 332 "DI_AUTONOMY_BEHAVIOR_MISMATCH" 331 "VC_AUTONOMY_BEHAVIOR_MISMATCH" 330 "DCAS_EXITED_REGION_TIMEOUT" 329 "WASHER_PUMP_NOT_HEALTHY" 328 "AP_B_SOC_UNHEALTHY" 327 "RCM_AIR_BAG_DEPLOY" 326 "RCM_NEAR_DEPLOY" 325 "AP_A_SOC_UNHEALTHY" 324 "ROUTE_EXCEEDS_SPEED_LIMIT" 323 "PERSISTENT_INVALID_NAV_ROUTE" 322 "NAV_ROUTE_EXITS_GEOFENCE" 321 "NAV_AVOID_HIGH_SPEED_ROADS_DISABLED" 320 "NAV_WHITELIST_ROUTING_DISABLED" 319 "NAV_ROUTE_RANKER_DISABLED" 318 "NAV_AVOID_SHORT_LANE_CHANGE_DISABLED" 317 "NAV_AVOID_UNPROTECTED_TURN_DISABLED" 316 "HIGHWAY_ON_ROUTE" 315 "EGO_ON_HIGHWAY" 314 "INVALID_VEHICLE_OPERATION_MODE" 313 "STEERING_ANGLE_OFFSET_HIGH" 312 "SAFETY_DRIVER_INATTENTIVE" 311 "TRACK_MODE_ACTIVE" 310 "EXT_TEMP_LOW_CERAMIC_BRAKES" 309 "GOAL_NEAR_SUMMON_MAP_BOUNDARY" 308 "SUMMON_HEARTBEAT_MISSING" 307 "EGO_NEAR_SUMMON_MAP_BOUNDARY" 306 "EGO_OUTSIDE_SUMMON_MAP_RADIUS" 305 "SUMMON_MAP_INVALID" 304 "RAW_UI_SUMMON_GOAL_INVALID" 303 "SUMMON_GOAL_INVALID" 302 "SYSTEM_CDP_UNAVAILABLE" 301 "SUMMON_COLLISION_DETECTION_ACTIVE" 300 "PHONE_TOO_FAR" 299 "PHONE_GPS_INVALID" 298 "GRADE_TOO_HIGH_WITHOUT_REDUNDANT_BRAKING" 297 "CABIN_CAM_DRIVER_MONITORING_UNAVAILABLE" 296 "CABIN_CAMERA_STREAM_FAILURE" 295 "DRIVER_PRESENCE_VISION_UNAVAILABLE" 294 "PEDAL_OVERRIDE_EXCEEDS_CONTROLLER_LIMITS" 293 "UPCOMING_FERRY_CROSSING" 292 "DRIVER_PARTIALLY_OCCLUDED" 291 "DRIVER_REQUIREMENTS_NOT_MET_VC" 290 "DRIVER_AGE_REQUIREMENTS_NOT_MET_VISION" 289 "GPS_DEGRADED" 288 "PILLARS_SWAP_DETECTED" 287 "NARROW_FISHEYE_SWAP_DETECTED" 286 "SCCM_MIA" 285 "RECENT_STALK_GEAR_SHIFT" 284 "IBOOSTER_MIA" 283 "PARKING_SPOT_SELECTED" 282 "SCROLL_WHEEL_INTERACTION" 281 "PEDAL_OVERRIDE_STRIKEOUT_FOR_DRIVE" 280 "PEDAL_OVERRIDE_STRIKEOUT" 279 "ABOVE_MAX_ACTIVATION_SPEED" 278 "DRIVER_MONITOR_SUSPENSION_ACTIVE" 277 "DRIVER_MONITOR_STRUCK_OUT_FOR_DRIVE" 276 "VC_CAMERA_AIR_CLEANING_STATUS_MIA" 275 "VC_CAMERA_FLUID_CLEANING_STATUS_MIA" 274 "INVALID_DI_PEDAL_POS" 273 "CABIN_CAMERA_FAN_RPM_FAULT" 272 "SELF_NETWORK_DECRYPTION_NOT_READY" 271 "OFF_ROAD_MODE_ACTIVE" 270 "SSD_CLIP_LOGGING_INACTIVE" 269 "CAMERA_EXPOSURE_INACTIVE" 268 "CAMERA_EXPOSURE_MISMATCH" 267 "CABIN_CAMERA_IR_LED_FAULTED" 266 "TAMPERING_DETECTED" 265 "NO_IMU_SOURCES_AVAILABLE" 264 "IMU_REDUNDANCY_LOST" 263 "DI_AUTONOMY_HEALTH_CAN_MESSAGE_MIA" 262 "ALL_WHEEL_SPEEDS_SENSORS_FAULTED" 261 "WHEEL_SPEEDS_CAN_MESSAGE_MIA" 260 "AP_THERMAL_MODEL_FAULT_DETECTED" 259 "SGK_AUTONOMY_MODE_NOT_IN_SYNC" 258 "SGK_AUTONOMY_STATE_NOT_IN_SYNC" 257 "ANY_RIGHT_DOOR_OPEN_BUTTON_FAULTED" 256 "ANY_LEFT_DOOR_OPEN_BUTTON_FAULTED" 255 "VCRIGHT_DOOR_STATUS_CAN_MESSAGE_MIA" 254 "VCLEFT_DOOR_STATUS_CAN_MESSAGE_MIA" 253 "BB_STATUS_CAN_MESSAGE_MIA" 252 "GTW_CAR_CONFIG_CAN_MESSAGE_MIA" 251 "TRAILER_MODE_ACTIVE" 250 "UI_LIMIT_MODE_ACTIVE" 249 "UI_QT_CAR_UNAVAILABLE" 248 "UI_CONNECTIVITY_HW_UNHEALTHY" 247 "UI_CONNECTIVITY_OFFLINE" 246 "UI_CENTER_DISPLAY_UNAVAILABLE" 245 "UI_HEALTH_STATUS_CAN_MESSAGE_MIA" 244 "ANY_LV_HEALTH_CAN_MESSAGE_INVALID" 243 "ANY_LV_HEALTH_CAN_MESSAGE_MIA" 242 "AP_SYSTEM_ISSUE_PENDING_REBOOT" 241 "AP_TASK_PENDING_REBOOT" 240 "APS_DUAL_CAMERA_POWER_FAILURE" 239 "APS_SINGLE_CAMERA_POWER_FAILURE" 238 "APS_ETH_BRIDGE_DOWN" 237 "APS_PEER_PMIC_FAULTED" 236 "APS_SELF_PMIC_FAULTED" 235 "APS_PEER_VRM_FAULTED" 234 "APS_SELF_VRM_FAULTED" 233 "APS_PEER_IMEM_FAULTED" 232 "APS_SELF_IMEM_FAULTED" 231 "APS_PEER_CAN_FAULTED" 230 "APS_SELF_CAN_FAULTED" 229 "APS_B_UNHEALTHY" 228 "APS_A_UNHEALTHY" 227 "PEER_VISION_FAILOVER_ACTIVE" 226 "ARBITER_SELECTED_BEHAVIOR_OUT_OF_DATE" 225 "ARBITER_SELECTED_BEHAVIOR_NOT_E2E" 224 "MISSION_PLANNER_DESIRED_BEHAVIOR_NOT_E2E" 223 "AUTONOMY_CONTROLLING_AND_NOT_PARKED" 222 "NO_VALID_SGK_STATUS" 221 "AUTONOMOUS_BEHAVIORS_LINK_NOT_ESTABLISHED" 220 "GNSS_PPS_MIA" 219 "GNSS_ANTENNA_DISCONNECTED" 218 "GNSS_UART_FAULTED" 217 "AP_THERMAL_DEGRADED_PULLOVER_REQ" 216 "AP_THERMAL_DEGRADED_BLOCK_ACTIVATION" 215 "DRIVER_PRESENT_NOT_ALLOWED" 214 "UNSUPERVISED_OPERATION_NOT_ALLOWED" 213 "NOT_IN_RT_NO_TAKEOVER_FLEET" 212 "SAFETY_OPERATOR_NOT_PRESENT" 211 "CAMERA_PRECONDITIONING_REQUIRED" 210 "BMS_CAN_MESSAGES_MIA" 209 "VEHICLE_LOSING_HV" 208 "HV_DRIVE_NO_RESTART" 207 "AUTONOMOUS_BEHAVIORS_TASK_SUSPENDING" 206 "AUDIO_BUS_DOWN" 205 "CAMERA_REDUNDANCY_NOT_READY" 204 "NO_VEHICLE_SPEED_SOURCE_AVAILABLE" 203 "DI_PRIMARY_SPEED_SOURCE_UNAVAILABLE" 202 "DI_SPEED_CAN_MESSAGE_MIA" 201 "DEFOG_SYSTEM_UNHEALTHY" 200 "COOLANT_SYSTEM_UNHEALTHY" 199 "DEFOG_SYSTEM_NOT_READY" 198 "COOLANT_SYSTEM_NOT_READY" 197 "NOT_AUTHENTICATED_FOR_DRIVE" 196 "UNASSIGNED_PASSENGER_UNBUCKLED" 195 "WAITING_FOR_PASSENGER_EGRESS" 194 "PASSENGER_UNEXPECTED_RIDE_INACTIVE" 193 "DRIVER_NOT_PRESENT_PRE_ACTIVATION" 192 "NARROW_WASH_NOT_AVAILABLE" 191 "REDUNDANT_IMU_CAN_MESSAGES_MIA" 190 "IMU_CAN_MESSAGES_MIA" 189 "BRAKING_CAN_MESSAGES_MIA" 188 "EPB_AUTONOMY_CAN_MESSAGES_MIA" 187 "PARK_BRAKE_CAN_MESSAGES_MIA" 186 "STEERING_CAN_MESSAGES_MIA" 185 "DI_SYSTEM_STATUS_CAN_MESSAGES_MIA" 184 "DI_CHASSIS_CONTROL_CAN_MESSAGE_MIA" 183 "APS_CAN_MESSAGES_MIA" 182 "POOR_LOCALIZATION_ACCURACY" 181 "VISION_FAILOVER_ACTIVE" 180 "SEAT_OCCUPANCY_STATUS_UNHEALTHY" 179 "TO_STREAMS_UNHEALTHY" 178 "SEATBELT_STATUS_UNHEALTHY" 177 "RCM_WARNING_INDICATOR_ON" 176 "REDUNDANT_BRAKES_FAIL_OPERATIONAL" 175 "REDUNDANT_BRAKES_REDUNDANCY_LOST" 174 "REDUNDANT_BRAKES_NOT_ARMED" 173 "REDUNDANT_BRAKES_NOT_READY" 172 "REDUNDANT_BRAKE_PATH_ACTIVE" 171 "RANKER_NOT_HEALTHY" 170 "PARKED_A_PEDAL_PRESSED" 169 "ANY_CANCEL_ACTIVE" 168 "BRAKE_CONFIRM_PENDING_PARK" 167 "BRAKE_APPLIED_D_R_N" 166 "BRAKE_RELEASE_PENDING_PARK" 165 "ENFORCED_UNPARK_DELAY_ACTIVE" 164 "WIPER_NOT_HEALTHY" 163 "RIGHT_PILLAR_CAM_HEATER_FAULT" 162 "LEFT_PILLAR_CAM_HEATER_FAULT" 161 "WINDSHIELD_CAM_HEATER_FAULT" 160 "ALL_TAIL_LIGHTS_FAULTED_IN_LOW_VIS" 159 "TAIL_LIGHT_FAULTED" 158 "REVERSE_LIGHT_FAULTED" 157 "RIGHT_TURN_LIGHT_FAULTED" 156 "LEFT_TURN_LIGHT_FAULTED" 155 "ALL_BRAKE_LIGHTS_FAULTED" 154 "BRAKE_LIGHT_FAULTED" 153 "HIGH_BEAM_LIGHT_FAULTED_IN_LOW_VIS" 152 "LOW_BEAM_LIGHT_FAULTED_IN_LOW_VIS" 151 "HIGH_BEAM_LIGHT_FAULTED" 150 "LOW_BEAM_LIGHT_FAULTED" 149 "HEADLIGHTS_NOT_AIMED" 148 "HEADLIGHTS_OFF_AT_NIGHT" 147 "AP_REDUNDANCY_UNAVAILABLE" 146 "DI_BRAKING_DECELERATION_UNAVAILABLE" 145 "DI_VDC_ACTIVE" 144 "DI_TC_ACTIVE" 143 "DI_VDC_STATE_NOT_NORMAL" 142 "DI_LOSING_PROPULSION" 141 "EPB_STATUS_NOT_PARKED" 140 "EPB_PARKING_AVAILABILITY_UNKNOWN" 139 "EPB_PARKING_AVAILABILITY_REQUEST_PATH_DEGRADED" 138 "EPB_PARKING_AVAILABILITY_SPEED_INVALID" 137 "EPB_PARKING_AVAILABILITY_FAULTED" 136 "TIRE_PRESSURE_SENSOR_FAULT" 135 "FLAT_TIRE" 134 "INTEGRATOR_HEALTH_CRITICAL" 133 "IMU_DATA_NOT_RELIABLE" 132 "FASCIA_FLUID_CLEAN_CRITICAL" 131 "BACKUP_FLUID_CLEAN_CRITICAL" 130 "RIGHT_REPEATER_FLUID_CLEAN_CRITICAL" 129 "LEFT_REPEATER_FLUID_CLEAN_CRITICAL" 128 "FASCIA_AIR_CLEAN_CRITICAL" 127 "BACKUP_AIR_CLEAN_CRITICAL" 126 "RIGHT_REPEATER_AIR_CLEAN_CRITICAL" 125 "LEFT_REPEATER_AIR_CLEAN_CRITICAL" 124 "FASCIA_FLUID_CLEAN_DEGRADED" 123 "BACKUP_FLUID_CLEAN_DEGRADED" 122 "RIGHT_REPEATER_FLUID_CLEAN_DEGRADED" 121 "LEFT_REPEATER_FLUID_CLEAN_DEGRADED" 120 "FASCIA_AIR_CLEAN_DEGRADED" 119 "BACKUP_AIR_CLEAN_DEGRADED" 118 "RIGHT_REPEATER_AIR_CLEAN_DEGRADED" 117 "LEFT_REPEATER_AIR_CLEAN_DEGRADED" 116 "TERTIARY_WASHER_FLUID_LOW" 115 "SECONDARY_WASHER_FLUID_LOW" 114 "WASHER_FLUID_LOW" 113 "ELEVATED_TIRE_PRESSURE_READING" 112 "LOW_TIRE_PRESSURE_READING" 111 "VISION_CABIN_OCCUPANCY_UNAVAILABLE" 110 "SGK_AUTOSTEER_MONITOR_ACTIVE" 109 "SGK_PLANNER_ACTIVE_D_R_N" 108 "FLEET_MAINTENANCE_EXPIRING_SOON" 107 "FLEET_MAINTENANCE_REQUIRED" 106 "CHARGE_CABLE_CONNECTED_OR_STATUS_UNKNOWN" 105 "PASSENGER_UNBUCKLED_ACTIVE_RIDE" 104 "PASSENGER_UNBUCKLED" 103 "SYSTEM_UNHEALTHY_DEV_OVERRIDE" 102 "SINGLE_SOC_HEALTHY_EXCEPTION" 101 "IMU_REPLICATION_NOT_READY" 100 "STATE_MACHINE_DISABLED" 99 "INCOMPATIBLE_SYSTEM_HEALTH" 98 "CABIN_CAM_BLINDED" 97 "RIDESHARE_INGRESS_NO_NAV_ROUTE" 96 "PASSENGER_EXPECTED" 95 "DRIVER_MONITOR_STRIKEOUT" 94 "DRIVER_NOT_PRESENT" 93 "CONTROLLER_SOLVER_CRITICAL" 92 "CONTROLLER_SOLVER_DEGRADED" 91 "CONTROLLER_DEGRADED_PEDAL_OVERRIDE" 90 "CONTROLLER_SOLVER_FAILURE" 89 "LV_CRITICAL_STATE" 88 "LV_DEGRADED_STATE" 87 "VEHICLE_AUTONOMY_BEHAVIOR_MISMATCH" 86 "CRUISE_STACK_MISMATCH" 85 "EPB_REDUNDANT_BRAKING_STATUS" 84 "EXTENDED_COMPUTE_INACTIVE_OTHER" 83 "EXTENDED_COMPUTE_TIME_SYNC_CRITICAL_DEGRADED" 82 "EXTENDED_COMPUTE_OTHER_SOC_STATE_UNKNOWN" 81 "EXTENDED_COMPUTE_OTHER_SOC_STATE_INACTIVE" 80 "EXTENDED_COMPUTE_PCIE_LINK_HEALTH" 79 "EXTENDED_COMPUTE_ETHERNET_LINK_HEALTH" 78 "EXTENDED_COMPUTE_OTHER_SOC_HEALTH_CRITICAL" 77 "EXTENDED_COMPUTE_OTHER_SOC_HEALTH_UNKNOWN" 76 "EXTENDED_COMPUTE_SOC_HEALTH_CRITICAL" 75 "EXTENDED_COMPUTE_SOC_HEALTH_UNKNOWN" 74 "FSD_FROM_PARK_DISABLED" 73 "NOT_IN_PARK_NO_TAKEOVER" 72 "NO_FIXED_ROUTE" 71 "NAV_GOAL_INVALID" 70 "ANY_EPAS_FAULT" 69 "EPAS_SYSTEM_TORQUE_REDUCED" 68 "EPAS_SECONDARY_MASTER" 67 "EPAS_REDUNDANCY_LOST" 66 "EPAS_DRIVERLESS_MODE_NOT_ACTIVE" 65 "EPAS_EAC_NOT_ACTIVE" 64 "EPAS_EAC_UNAVAILABLE" 63 "STEERING_ANGLE_INVALID" 62 "CRUISE_FAULT" 61 "CRUISE_NOT_ACTIVE_OTHER" 60 "CRUISE_NOT_ACTIVE_ESTOP" 59 "CRUISE_UNAVAILABLE_OTHER" 58 "CRUISE_UNAVAILABLE_BRAKE_APPLIED" 57 "NOT_POWER_STATE_DRIVE" 56 "FRUNK_OPEN" 55 "TRUNK_OPEN" 54 "PASSENGER_DOOR_OPEN" 53 "DRIVER_DOOR_OPEN" 52 "VISION_FPS_LOW_CAMERA_DROPS" 51 "VISION_LATENCY_HIGH" 50 "SAFETY_DRIVER_UNBUCKLED" 49 "FASCIA_VISION_OCCLUSION_AT_STOP" 48 "SEVERE_RIGHT_VISION_OCCLUSION_REVERSE" 47 "SEVERE_LEFT_VISION_OCCLUSION_REVERSE" 46 "SEVERE_BACKUP_VISION_OCCLUSION_REVERSE" 45 "SEVERE_RIGHT_VISION_OCCLUSION_MANEUVER" 44 "SEVERE_LEFT_VISION_OCCLUSION_MANEUVER" 43 "SEVERE_RIGHT_VISION_OCCLUSION" 42 "SEVERE_LEFT_VISION_OCCLUSION" 41 "SEVERE_MULTIPLE_FRONT_VISION_OCCLUSION" 40 "SEVERE_SINGLE_FRONT_VISION_OCCLUSION" 39 "CAMERA_HEALTH_METRICS_UNHEALTHY" 38 "VISION_SCENETAGS_UNHEALTHY" 37 "VISION_AUTOWIPER_UNHEALTHY" 36 "VISION_AUTOHIGHBEAM_UNHEALTHY" 35 "VISION_FAILSAFES_UNHEALTHY" 34 "RIGHT_VISION_FAILSAFE_PARKED" 33 "LEFT_VISION_FAILSAFE_PARKED" 32 "FRONT_VISION_FAILSAFE_PARKED" 31 "REAR_VISION_FAILSAFE_PARKED" 30 "CAMERA_OFFGASSING" 29 "CAMERA_OFFGASSING_PRE_ALERT" 28 "INTERMITTENT_FRAME_DROPS" 27 "CAMERA_AUTOEXPOSURE_LOST" 26 "OUT_OF_SYNC_CAMERA_STREAMS" 25 "FASCIA_CAMERA_STREAM_LOST" 24 "BACKUP_CAMERA_STREAM_LOST" 23 "RIGHT_CAMERAS_STREAM_LOST" 22 "LEFT_CAMERAS_STREAM_LOST" 21 "FRONT_CAMERAS_STREAM_LOST" 20 "CAMERA_MCU_FW_MISMATCH" 19 "FACTORY_CALIBRATION" 18 "CAMERA_PITCH_OUT_OF_BOUNDS" 17 "CAMERA_CALIBRATION" 16 "GNSS_DEGRADED_SIGNAL_STRENGTH" 15 "AP_POWER_REQUEST_NOT_NOMINAL" 14 "SENTRY_ACTIVE" 13 "NO_REDUNDANT_BRAKING" 12 "HK_RESTRICTED" 11 "OUTSIDE_GEOFENCE" 10 "RUN_MODE_NOT_FSD" 9 "AEB_ACTIVE" 8 "SUMMON_ACTIVE" 7 "AUTOPARK_ACTIVE" 6 "FSD_DISABLED" 5 "CAR_WASH_MODE" 4 "DELIVERED" 3 "NO_AUTONOMY_MODE_ACTIVE" 2 "NEUTRAL_GEAR" 1 "NONE" 0 "UNKNOWN" ;
VAL_ 1513 APP_sw457_safeStateManeuver 2 "STOP_IN_LANE" 1 "PULLOVER" 0 "NONE" ;
VAL_ 1513 APP_sw461_rerouteRequest 2 "COMPLETE_TRIP" 1 "IMMEDIATELY" 0 "NONE" ;
VAL_ 1513 APP_sw461_rerouteReason 414 "TRAJECTORY_ON_PUBLIC_ROAD_NOT_INDOORS" 413 "STOP_IN_LANE_NOT_HONORED" 412 "SIMPLE_SUMMON_OBSTACLE_BLOCKED" 411 "SEVERE_SINGLE_FRONT_VISION_OCCLUSION_AFTER_WIPE" 410 "PHONE_TOO_FAR_TO_START" 409 "MAX_SPEED_LIMIT_FOR_MODE_EXCEEDED" 408 "EPB_REDUNDANT_BRAKING_UNAVAILABLE" 407 "EGO_GEAR_NOT_ALLOWED" 406 "EGO_EXCEEDED_MAX_SUMMON_DISTANCE" 405 "DUAL_EPB_UNAVAILABLE" 404 "COMPRESSOR_FRAME_DROP_RATE_HIGH" 403 "CAN_RX_VALIDATION_ERROR" 402 "BRAKE_APPLIED_PARKED" 401 "ALARM_ACTIVE" 400 "SAFETY_DRIVER_UNBUCKLED_PRE_ACTIVATION" 399 "NOT_FACTORY_SCHEDULE" 398 "FSD_REGION_NOT_ALLOWED" 397 "FSD_QUIZ_REQUIRED" 396 "EPAS_EAC_NOT_ACTIVE_OTHER" 395 "EPAS_EAC_NOT_ACTIVE_HANDS_ON" 394 "DI_CONTROL_INTEGRATOR_WINDUP" 393 "SEVERE_SINGLE_FRONT_VISION_OCCLUSION_HIGH_FOGGING_RISK" 392 "EGO_NEAR_SUMMON_MAP_BOUNDARY_NOT_INDOORS" 391 "GOAL_NEAR_SUMMON_MAP_BOUNDARY_NOT_INDOORS" 390 "GRADE_TOO_HIGH_WITHOUT_REDUNDANT_BRAKING_LOW_MU" 389 "NAV_DESTINATION_OUTSIDE_GEOFENCE" 388 "RCM_COLLISION_SEVERITY_TRIGGERED" 387 "EPB_PARKING_AVAILABILITY_TOO_STEEP" 386 "REVERSE_GEAR_NOT_AVAILABLE" 385 "DESTINATION_OUTSIDE_GEOFENCE_AP" 384 "SSD_CLIP_LOGGING_CRITICAL" 383 "DRIVE_GEAR_NOT_AVAILABLE" 382 "SIDE_VISIBILITY_DEGRADED_PARKED_DOORS_CLOSED" 381 "PERSISTENT_FRAME_DROPS" 380 "PERSISTENT_HANDS_ON_NOT_ALLOWED" 379 "NAV_ROUTE_EXCEEDS_GEOFENCE_BUFFER" 378 "RANKER_OUTPUT_STALE" 377 "VISION_PLANNER_STALE" 376 "AUTO_WIPERS_OFF" 375 "COUNTRY_NOT_ALLOWED_FOR_OPERATION" 374 "OUTSIDE_TRACK_TEST_GEOFENCE" 373 "TEMPERATURE_EXCEEDS_ODD" 372 "RIDESHARE_NAV_GOAL_NOT_IN_SYNC" 371 "HV_BATTERY_AC_CHARGING_UNHEALTHY" 370 "HV_BATTERY_DC_CHARGING_UNHEALTHY" 369 "UI_RIDE_SETUP_IN_PROGRESS" 368 "AUTO_HEADLIGHTS_OFF" 367 "IMMOBILIZER_AUTH_AUTONOMY" 366 "DI_RESTRICTED_DRIVING_MANUAL_RECOVERY" 365 "SUMMON_ACTIVE_DURATION_EXCEEDED" 364 "ESKF_SPEED_SOURCE_ACTIVE" 363 "IMU_DATA_NOT_RELIABLE_WITH_FLEET_CONFIG_ENABLED" 362 "FASCIA_VISION_OCCLUSION_AT_LONG_STOP" 361 "HIGH_SPEED_ROAD_ON_ROUTE" 360 "EGO_ON_HIGH_SPEED_ROAD" 359 "UNACCOMPANIED_UNDERAGE_RIDER_DETECTED" 358 "AEB_FAULTED" 357 "AUDIO_HARDWARE_ODIN_FAILED" 356 "FASCIA_VISION_FAILSAFE_PARKED" 355 "APS_B_EPLANNER_NO_VALID_TRAJECTORY" 354 "APS_A_EPLANNER_NO_VALID_TRAJECTORY" 353 "FASCIA_CAM_INTEGRATED_HEATER_FAULT" 352 "BACKUP_CAM_INTEGRATED_HEATER_FAULT" 351 "RIGHT_REPEATER_CAM_INTEGRATED_HEATER_FAULT" 350 "LEFT_REPEATER_CAM_INTEGRATED_HEATER_FAULT" 349 "RIGHT_PILLAR_CAM_INTEGRATED_HEATER_FAULT" 348 "LEFT_PILLAR_CAM_INTEGRATED_HEATER_FAULT" 347 "RIGHT_PILLAR_CAM_WIRE_HEATER_FAULT" 346 "LEFT_PILLAR_CAM_WIRE_HEATER_FAULT" 345 "WINDSHIELD_CAM_WIRE_HEATER_FAULT" 344 "CONTROLLER_EPLANNER_UNHEALTHY" 343 "VEHICLE_COLLISION_DETECTED" 342 "VRU_COLLISION_DETECTED" 341 "MAJOR_COLLISION_DETECTED" 340 "ONGOING_COLLISION_DETECTED" 339 "INTEGRATOR_ACCELERATION_INVALID" 338 "CABIN_CAM_DRIVER_MONITORING_SYSTEM_UNAVAILABLE" 337 "DCAS_DRIVER_ATTENTION_STATE_DETERMINATION_DEGRADED" 336 "NON_MAIN_FRONT_CAMERAS_STREAM_LOST" 335 "MAIN_CAMERA_STREAM_LOST" 334 "DRIVER_WIPER_WASH_HEALTH_DEGRADED" 333 "EPB_AUTONOMY_BEHAVIOR_MISMATCH" 332 "DI_AUTONOMY_BEHAVIOR_MISMATCH" 331 "VC_AUTONOMY_BEHAVIOR_MISMATCH" 330 "DCAS_EXITED_REGION_TIMEOUT" 329 "WASHER_PUMP_NOT_HEALTHY" 328 "AP_B_SOC_UNHEALTHY" 327 "RCM_AIR_BAG_DEPLOY" 326 "RCM_NEAR_DEPLOY" 325 "AP_A_SOC_UNHEALTHY" 324 "ROUTE_EXCEEDS_SPEED_LIMIT" 323 "PERSISTENT_INVALID_NAV_ROUTE" 322 "NAV_ROUTE_EXITS_GEOFENCE" 321 "NAV_AVOID_HIGH_SPEED_ROADS_DISABLED" 320 "NAV_WHITELIST_ROUTING_DISABLED" 319 "NAV_ROUTE_RANKER_DISABLED" 318 "NAV_AVOID_SHORT_LANE_CHANGE_DISABLED" 317 "NAV_AVOID_UNPROTECTED_TURN_DISABLED" 316 "HIGHWAY_ON_ROUTE" 315 "EGO_ON_HIGHWAY" 314 "INVALID_VEHICLE_OPERATION_MODE" 313 "STEERING_ANGLE_OFFSET_HIGH" 312 "SAFETY_DRIVER_INATTENTIVE" 311 "TRACK_MODE_ACTIVE" 310 "EXT_TEMP_LOW_CERAMIC_BRAKES" 309 "GOAL_NEAR_SUMMON_MAP_BOUNDARY" 308 "SUMMON_HEARTBEAT_MISSING" 307 "EGO_NEAR_SUMMON_MAP_BOUNDARY" 306 "EGO_OUTSIDE_SUMMON_MAP_RADIUS" 305 "SUMMON_MAP_INVALID" 304 "RAW_UI_SUMMON_GOAL_INVALID" 303 "SUMMON_GOAL_INVALID" 302 "SYSTEM_CDP_UNAVAILABLE" 301 "SUMMON_COLLISION_DETECTION_ACTIVE" 300 "PHONE_TOO_FAR" 299 "PHONE_GPS_INVALID" 298 "GRADE_TOO_HIGH_WITHOUT_REDUNDANT_BRAKING" 297 "CABIN_CAM_DRIVER_MONITORING_UNAVAILABLE" 296 "CABIN_CAMERA_STREAM_FAILURE" 295 "DRIVER_PRESENCE_VISION_UNAVAILABLE" 294 "PEDAL_OVERRIDE_EXCEEDS_CONTROLLER_LIMITS" 293 "UPCOMING_FERRY_CROSSING" 292 "DRIVER_PARTIALLY_OCCLUDED" 291 "DRIVER_REQUIREMENTS_NOT_MET_VC" 290 "DRIVER_AGE_REQUIREMENTS_NOT_MET_VISION" 289 "GPS_DEGRADED" 288 "PILLARS_SWAP_DETECTED" 287 "NARROW_FISHEYE_SWAP_DETECTED" 286 "SCCM_MIA" 285 "RECENT_STALK_GEAR_SHIFT" 284 "IBOOSTER_MIA" 283 "PARKING_SPOT_SELECTED" 282 "SCROLL_WHEEL_INTERACTION" 281 "PEDAL_OVERRIDE_STRIKEOUT_FOR_DRIVE" 280 "PEDAL_OVERRIDE_STRIKEOUT" 279 "ABOVE_MAX_ACTIVATION_SPEED" 278 "DRIVER_MONITOR_SUSPENSION_ACTIVE" 277 "DRIVER_MONITOR_STRUCK_OUT_FOR_DRIVE" 276 "VC_CAMERA_AIR_CLEANING_STATUS_MIA" 275 "VC_CAMERA_FLUID_CLEANING_STATUS_MIA" 274 "INVALID_DI_PEDAL_POS" 273 "CABIN_CAMERA_FAN_RPM_FAULT" 272 "SELF_NETWORK_DECRYPTION_NOT_READY" 271 "OFF_ROAD_MODE_ACTIVE" 270 "SSD_CLIP_LOGGING_INACTIVE" 269 "CAMERA_EXPOSURE_INACTIVE" 268 "CAMERA_EXPOSURE_MISMATCH" 267 "CABIN_CAMERA_IR_LED_FAULTED" 266 "TAMPERING_DETECTED" 265 "NO_IMU_SOURCES_AVAILABLE" 264 "IMU_REDUNDANCY_LOST" 263 "DI_AUTONOMY_HEALTH_CAN_MESSAGE_MIA" 262 "ALL_WHEEL_SPEEDS_SENSORS_FAULTED" 261 "WHEEL_SPEEDS_CAN_MESSAGE_MIA" 260 "AP_THERMAL_MODEL_FAULT_DETECTED" 259 "SGK_AUTONOMY_MODE_NOT_IN_SYNC" 258 "SGK_AUTONOMY_STATE_NOT_IN_SYNC" 257 "ANY_RIGHT_DOOR_OPEN_BUTTON_FAULTED" 256 "ANY_LEFT_DOOR_OPEN_BUTTON_FAULTED" 255 "VCRIGHT_DOOR_STATUS_CAN_MESSAGE_MIA" 254 "VCLEFT_DOOR_STATUS_CAN_MESSAGE_MIA" 253 "BB_STATUS_CAN_MESSAGE_MIA" 252 "GTW_CAR_CONFIG_CAN_MESSAGE_MIA" 251 "TRAILER_MODE_ACTIVE" 250 "UI_LIMIT_MODE_ACTIVE" 249 "UI_QT_CAR_UNAVAILABLE" 248 "UI_CONNECTIVITY_HW_UNHEALTHY" 247 "UI_CONNECTIVITY_OFFLINE" 246 "UI_CENTER_DISPLAY_UNAVAILABLE" 245 "UI_HEALTH_STATUS_CAN_MESSAGE_MIA" 244 "ANY_LV_HEALTH_CAN_MESSAGE_INVALID" 243 "ANY_LV_HEALTH_CAN_MESSAGE_MIA" 242 "AP_SYSTEM_ISSUE_PENDING_REBOOT" 241 "AP_TASK_PENDING_REBOOT" 240 "APS_DUAL_CAMERA_POWER_FAILURE" 239 "APS_SINGLE_CAMERA_POWER_FAILURE" 238 "APS_ETH_BRIDGE_DOWN" 237 "APS_PEER_PMIC_FAULTED" 236 "APS_SELF_PMIC_FAULTED" 235 "APS_PEER_VRM_FAULTED" 234 "APS_SELF_VRM_FAULTED" 233 "APS_PEER_IMEM_FAULTED" 232 "APS_SELF_IMEM_FAULTED" 231 "APS_PEER_CAN_FAULTED" 230 "APS_SELF_CAN_FAULTED" 229 "APS_B_UNHEALTHY" 228 "APS_A_UNHEALTHY" 227 "PEER_VISION_FAILOVER_ACTIVE" 226 "ARBITER_SELECTED_BEHAVIOR_OUT_OF_DATE" 225 "ARBITER_SELECTED_BEHAVIOR_NOT_E2E" 224 "MISSION_PLANNER_DESIRED_BEHAVIOR_NOT_E2E" 223 "AUTONOMY_CONTROLLING_AND_NOT_PARKED" 222 "NO_VALID_SGK_STATUS" 221 "AUTONOMOUS_BEHAVIORS_LINK_NOT_ESTABLISHED" 220 "GNSS_PPS_MIA" 219 "GNSS_ANTENNA_DISCONNECTED" 218 "GNSS_UART_FAULTED" 217 "AP_THERMAL_DEGRADED_PULLOVER_REQ" 216 "AP_THERMAL_DEGRADED_BLOCK_ACTIVATION" 215 "DRIVER_PRESENT_NOT_ALLOWED" 214 "UNSUPERVISED_OPERATION_NOT_ALLOWED" 213 "NOT_IN_RT_NO_TAKEOVER_FLEET" 212 "SAFETY_OPERATOR_NOT_PRESENT" 211 "CAMERA_PRECONDITIONING_REQUIRED" 210 "BMS_CAN_MESSAGES_MIA" 209 "VEHICLE_LOSING_HV" 208 "HV_DRIVE_NO_RESTART" 207 "AUTONOMOUS_BEHAVIORS_TASK_SUSPENDING" 206 "AUDIO_BUS_DOWN" 205 "CAMERA_REDUNDANCY_NOT_READY" 204 "NO_VEHICLE_SPEED_SOURCE_AVAILABLE" 203 "DI_PRIMARY_SPEED_SOURCE_UNAVAILABLE" 202 "DI_SPEED_CAN_MESSAGE_MIA" 201 "DEFOG_SYSTEM_UNHEALTHY" 200 "COOLANT_SYSTEM_UNHEALTHY" 199 "DEFOG_SYSTEM_NOT_READY" 198 "COOLANT_SYSTEM_NOT_READY" 197 "NOT_AUTHENTICATED_FOR_DRIVE" 196 "UNASSIGNED_PASSENGER_UNBUCKLED" 195 "WAITING_FOR_PASSENGER_EGRESS" 194 "PASSENGER_UNEXPECTED_RIDE_INACTIVE" 193 "DRIVER_NOT_PRESENT_PRE_ACTIVATION" 192 "NARROW_WASH_NOT_AVAILABLE" 191 "REDUNDANT_IMU_CAN_MESSAGES_MIA" 190 "IMU_CAN_MESSAGES_MIA" 189 "BRAKING_CAN_MESSAGES_MIA" 188 "EPB_AUTONOMY_CAN_MESSAGES_MIA" 187 "PARK_BRAKE_CAN_MESSAGES_MIA" 186 "STEERING_CAN_MESSAGES_MIA" 185 "DI_SYSTEM_STATUS_CAN_MESSAGES_MIA" 184 "DI_CHASSIS_CONTROL_CAN_MESSAGE_MIA" 183 "APS_CAN_MESSAGES_MIA" 182 "POOR_LOCALIZATION_ACCURACY" 181 "VISION_FAILOVER_ACTIVE" 180 "SEAT_OCCUPANCY_STATUS_UNHEALTHY" 179 "TO_STREAMS_UNHEALTHY" 178 "SEATBELT_STATUS_UNHEALTHY" 177 "RCM_WARNING_INDICATOR_ON" 176 "REDUNDANT_BRAKES_FAIL_OPERATIONAL" 175 "REDUNDANT_BRAKES_REDUNDANCY_LOST" 174 "REDUNDANT_BRAKES_NOT_ARMED" 173 "REDUNDANT_BRAKES_NOT_READY" 172 "REDUNDANT_BRAKE_PATH_ACTIVE" 171 "RANKER_NOT_HEALTHY" 170 "PARKED_A_PEDAL_PRESSED" 169 "ANY_CANCEL_ACTIVE" 168 "BRAKE_CONFIRM_PENDING_PARK" 167 "BRAKE_APPLIED_D_R_N" 166 "BRAKE_RELEASE_PENDING_PARK" 165 "ENFORCED_UNPARK_DELAY_ACTIVE" 164 "WIPER_NOT_HEALTHY" 163 "RIGHT_PILLAR_CAM_HEATER_FAULT" 162 "LEFT_PILLAR_CAM_HEATER_FAULT" 161 "WINDSHIELD_CAM_HEATER_FAULT" 160 "ALL_TAIL_LIGHTS_FAULTED_IN_LOW_VIS" 159 "TAIL_LIGHT_FAULTED" 158 "REVERSE_LIGHT_FAULTED" 157 "RIGHT_TURN_LIGHT_FAULTED" 156 "LEFT_TURN_LIGHT_FAULTED" 155 "ALL_BRAKE_LIGHTS_FAULTED" 154 "BRAKE_LIGHT_FAULTED" 153 "HIGH_BEAM_LIGHT_FAULTED_IN_LOW_VIS" 152 "LOW_BEAM_LIGHT_FAULTED_IN_LOW_VIS" 151 "HIGH_BEAM_LIGHT_FAULTED" 150 "LOW_BEAM_LIGHT_FAULTED" 149 "HEADLIGHTS_NOT_AIMED" 148 "HEADLIGHTS_OFF_AT_NIGHT" 147 "AP_REDUNDANCY_UNAVAILABLE" 146 "DI_BRAKING_DECELERATION_UNAVAILABLE" 145 "DI_VDC_ACTIVE" 144 "DI_TC_ACTIVE" 143 "DI_VDC_STATE_NOT_NORMAL" 142 "DI_LOSING_PROPULSION" 141 "EPB_STATUS_NOT_PARKED" 140 "EPB_PARKING_AVAILABILITY_UNKNOWN" 139 "EPB_PARKING_AVAILABILITY_REQUEST_PATH_DEGRADED" 138 "EPB_PARKING_AVAILABILITY_SPEED_INVALID" 137 "EPB_PARKING_AVAILABILITY_FAULTED" 136 "TIRE_PRESSURE_SENSOR_FAULT" 135 "FLAT_TIRE" 134 "INTEGRATOR_HEALTH_CRITICAL" 133 "IMU_DATA_NOT_RELIABLE" 132 "FASCIA_FLUID_CLEAN_CRITICAL" 131 "BACKUP_FLUID_CLEAN_CRITICAL" 130 "RIGHT_REPEATER_FLUID_CLEAN_CRITICAL" 129 "LEFT_REPEATER_FLUID_CLEAN_CRITICAL" 128 "FASCIA_AIR_CLEAN_CRITICAL" 127 "BACKUP_AIR_CLEAN_CRITICAL" 126 "RIGHT_REPEATER_AIR_CLEAN_CRITICAL" 125 "LEFT_REPEATER_AIR_CLEAN_CRITICAL" 124 "FASCIA_FLUID_CLEAN_DEGRADED" 123 "BACKUP_FLUID_CLEAN_DEGRADED" 122 "RIGHT_REPEATER_FLUID_CLEAN_DEGRADED" 121 "LEFT_REPEATER_FLUID_CLEAN_DEGRADED" 120 "FASCIA_AIR_CLEAN_DEGRADED" 119 "BACKUP_AIR_CLEAN_DEGRADED" 118 "RIGHT_REPEATER_AIR_CLEAN_DEGRADED" 117 "LEFT_REPEATER_AIR_CLEAN_DEGRADED" 116 "TERTIARY_WASHER_FLUID_LOW" 115 "SECONDARY_WASHER_FLUID_LOW" 114 "WASHER_FLUID_LOW" 113 "ELEVATED_TIRE_PRESSURE_READING" 112 "LOW_TIRE_PRESSURE_READING" 111 "VISION_CABIN_OCCUPANCY_UNAVAILABLE" 110 "SGK_AUTOSTEER_MONITOR_ACTIVE" 109 "SGK_PLANNER_ACTIVE_D_R_N" 108 "FLEET_MAINTENANCE_EXPIRING_SOON" 107 "FLEET_MAINTENANCE_REQUIRED" 106 "CHARGE_CABLE_CONNECTED_OR_STATUS_UNKNOWN" 105 "PASSENGER_UNBUCKLED_ACTIVE_RIDE" 104 "PASSENGER_UNBUCKLED" 103 "SYSTEM_UNHEALTHY_DEV_OVERRIDE" 102 "SINGLE_SOC_HEALTHY_EXCEPTION" 101 "IMU_REPLICATION_NOT_READY" 100 "STATE_MACHINE_DISABLED" 99 "INCOMPATIBLE_SYSTEM_HEALTH" 98 "CABIN_CAM_BLINDED" 97 "RIDESHARE_INGRESS_NO_NAV_ROUTE" 96 "PASSENGER_EXPECTED" 95 "DRIVER_MONITOR_STRIKEOUT" 94 "DRIVER_NOT_PRESENT" 93 "CONTROLLER_SOLVER_CRITICAL" 92 "CONTROLLER_SOLVER_DEGRADED" 91 "CONTROLLER_DEGRADED_PEDAL_OVERRIDE" 90 "CONTROLLER_SOLVER_FAILURE" 89 "LV_CRITICAL_STATE" 88 "LV_DEGRADED_STATE" 87 "VEHICLE_AUTONOMY_BEHAVIOR_MISMATCH" 86 "CRUISE_STACK_MISMATCH" 85 "EPB_REDUNDANT_BRAKING_STATUS" 84 "EXTENDED_COMPUTE_INACTIVE_OTHER" 83 "EXTENDED_COMPUTE_TIME_SYNC_CRITICAL_DEGRADED" 82 "EXTENDED_COMPUTE_OTHER_SOC_STATE_UNKNOWN" 81 "EXTENDED_COMPUTE_OTHER_SOC_STATE_INACTIVE" 80 "EXTENDED_COMPUTE_PCIE_LINK_HEALTH" 79 "EXTENDED_COMPUTE_ETHERNET_LINK_HEALTH" 78 "EXTENDED_COMPUTE_OTHER_SOC_HEALTH_CRITICAL" 77 "EXTENDED_COMPUTE_OTHER_SOC_HEALTH_UNKNOWN" 76 "EXTENDED_COMPUTE_SOC_HEALTH_CRITICAL" 75 "EXTENDED_COMPUTE_SOC_HEALTH_UNKNOWN" 74 "FSD_FROM_PARK_DISABLED" 73 "NOT_IN_PARK_NO_TAKEOVER" 72 "NO_FIXED_ROUTE" 71 "NAV_GOAL_INVALID" 70 "ANY_EPAS_FAULT" 69 "EPAS_SYSTEM_TORQUE_REDUCED" 68 "EPAS_SECONDARY_MASTER" 67 "EPAS_REDUNDANCY_LOST" 66 "EPAS_DRIVERLESS_MODE_NOT_ACTIVE" 65 "EPAS_EAC_NOT_ACTIVE" 64 "EPAS_EAC_UNAVAILABLE" 63 "STEERING_ANGLE_INVALID" 62 "CRUISE_FAULT" 61 "CRUISE_NOT_ACTIVE_OTHER" 60 "CRUISE_NOT_ACTIVE_ESTOP" 59 "CRUISE_UNAVAILABLE_OTHER" 58 "CRUISE_UNAVAILABLE_BRAKE_APPLIED" 57 "NOT_POWER_STATE_DRIVE" 56 "FRUNK_OPEN" 55 "TRUNK_OPEN" 54 "PASSENGER_DOOR_OPEN" 53 "DRIVER_DOOR_OPEN" 52 "VISION_FPS_LOW_CAMERA_DROPS" 51 "VISION_LATENCY_HIGH" 50 "SAFETY_DRIVER_UNBUCKLED" 49 "FASCIA_VISION_OCCLUSION_AT_STOP" 48 "SEVERE_RIGHT_VISION_OCCLUSION_REVERSE" 47 "SEVERE_LEFT_VISION_OCCLUSION_REVERSE" 46 "SEVERE_BACKUP_VISION_OCCLUSION_REVERSE" 45 "SEVERE_RIGHT_VISION_OCCLUSION_MANEUVER" 44 "SEVERE_LEFT_VISION_OCCLUSION_MANEUVER" 43 "SEVERE_RIGHT_VISION_OCCLUSION" 42 "SEVERE_LEFT_VISION_OCCLUSION" 41 "SEVERE_MULTIPLE_FRONT_VISION_OCCLUSION" 40 "SEVERE_SINGLE_FRONT_VISION_OCCLUSION" 39 "CAMERA_HEALTH_METRICS_UNHEALTHY" 38 "VISION_SCENETAGS_UNHEALTHY" 37 "VISION_AUTOWIPER_UNHEALTHY" 36 "VISION_AUTOHIGHBEAM_UNHEALTHY" 35 "VISION_FAILSAFES_UNHEALTHY" 34 "RIGHT_VISION_FAILSAFE_PARKED" 33 "LEFT_VISION_FAILSAFE_PARKED" 32 "FRONT_VISION_FAILSAFE_PARKED" 31 "REAR_VISION_FAILSAFE_PARKED" 30 "CAMERA_OFFGASSING" 29 "CAMERA_OFFGASSING_PRE_ALERT" 28 "INTERMITTENT_FRAME_DROPS" 27 "CAMERA_AUTOEXPOSURE_LOST" 26 "OUT_OF_SYNC_CAMERA_STREAMS" 25 "FASCIA_CAMERA_STREAM_LOST" 24 "BACKUP_CAMERA_STREAM_LOST" 23 "RIGHT_CAMERAS_STREAM_LOST" 22 "LEFT_CAMERAS_STREAM_LOST" 21 "FRONT_CAMERAS_STREAM_LOST" 20 "CAMERA_MCU_FW_MISMATCH" 19 "FACTORY_CALIBRATION" 18 "CAMERA_PITCH_OUT_OF_BOUNDS" 17 "CAMERA_CALIBRATION" 16 "GNSS_DEGRADED_SIGNAL_STRENGTH" 15 "AP_POWER_REQUEST_NOT_NOMINAL" 14 "SENTRY_ACTIVE" 13 "NO_REDUNDANT_BRAKING" 12 "HK_RESTRICTED" 11 "OUTSIDE_GEOFENCE" 10 "RUN_MODE_NOT_FSD" 9 "AEB_ACTIVE" 8 "SUMMON_ACTIVE" 7 "AUTOPARK_ACTIVE" 6 "FSD_DISABLED" 5 "CAR_WASH_MODE" 4 "DELIVERED" 3 "NO_AUTONOMY_MODE_ACTIVE" 2 "NEUTRAL_GEAR" 1 "NONE" 0 "UNKNOWN" ;
VAL_ 1513 APP_sw465_reason1 414 "TRAJECTORY_ON_PUBLIC_ROAD_NOT_INDOORS" 413 "STOP_IN_LANE_NOT_HONORED" 412 "SIMPLE_SUMMON_OBSTACLE_BLOCKED" 411 "SEVERE_SINGLE_FRONT_VISION_OCCLUSION_AFTER_WIPE" 410 "PHONE_TOO_FAR_TO_START" 409 "MAX_SPEED_LIMIT_FOR_MODE_EXCEEDED" 408 "EPB_REDUNDANT_BRAKING_UNAVAILABLE" 407 "EGO_GEAR_NOT_ALLOWED" 406 "EGO_EXCEEDED_MAX_SUMMON_DISTANCE" 405 "DUAL_EPB_UNAVAILABLE" 404 "COMPRESSOR_FRAME_DROP_RATE_HIGH" 403 "CAN_RX_VALIDATION_ERROR" 402 "BRAKE_APPLIED_PARKED" 401 "ALARM_ACTIVE" 400 "SAFETY_DRIVER_UNBUCKLED_PRE_ACTIVATION" 399 "NOT_FACTORY_SCHEDULE" 398 "FSD_REGION_NOT_ALLOWED" 397 "FSD_QUIZ_REQUIRED" 396 "EPAS_EAC_NOT_ACTIVE_OTHER" 395 "EPAS_EAC_NOT_ACTIVE_HANDS_ON" 394 "DI_CONTROL_INTEGRATOR_WINDUP" 393 "SEVERE_SINGLE_FRONT_VISION_OCCLUSION_HIGH_FOGGING_RISK" 392 "EGO_NEAR_SUMMON_MAP_BOUNDARY_NOT_INDOORS" 391 "GOAL_NEAR_SUMMON_MAP_BOUNDARY_NOT_INDOORS" 390 "GRADE_TOO_HIGH_WITHOUT_REDUNDANT_BRAKING_LOW_MU" 389 "NAV_DESTINATION_OUTSIDE_GEOFENCE" 388 "RCM_COLLISION_SEVERITY_TRIGGERED" 387 "EPB_PARKING_AVAILABILITY_TOO_STEEP" 386 "REVERSE_GEAR_NOT_AVAILABLE" 385 "DESTINATION_OUTSIDE_GEOFENCE_AP" 384 "SSD_CLIP_LOGGING_CRITICAL" 383 "DRIVE_GEAR_NOT_AVAILABLE" 382 "SIDE_VISIBILITY_DEGRADED_PARKED_DOORS_CLOSED" 381 "PERSISTENT_FRAME_DROPS" 380 "PERSISTENT_HANDS_ON_NOT_ALLOWED" 379 "NAV_ROUTE_EXCEEDS_GEOFENCE_BUFFER" 378 "RANKER_OUTPUT_STALE" 377 "VISION_PLANNER_STALE" 376 "AUTO_WIPERS_OFF" 375 "COUNTRY_NOT_ALLOWED_FOR_OPERATION" 374 "OUTSIDE_TRACK_TEST_GEOFENCE" 373 "TEMPERATURE_EXCEEDS_ODD" 372 "RIDESHARE_NAV_GOAL_NOT_IN_SYNC" 371 "HV_BATTERY_AC_CHARGING_UNHEALTHY" 370 "HV_BATTERY_DC_CHARGING_UNHEALTHY" 369 "UI_RIDE_SETUP_IN_PROGRESS" 368 "AUTO_HEADLIGHTS_OFF" 367 "IMMOBILIZER_AUTH_AUTONOMY" 366 "DI_RESTRICTED_DRIVING_MANUAL_RECOVERY" 365 "SUMMON_ACTIVE_DURATION_EXCEEDED" 364 "ESKF_SPEED_SOURCE_ACTIVE" 363 "IMU_DATA_NOT_RELIABLE_WITH_FLEET_CONFIG_ENABLED" 362 "FASCIA_VISION_OCCLUSION_AT_LONG_STOP" 361 "HIGH_SPEED_ROAD_ON_ROUTE" 360 "EGO_ON_HIGH_SPEED_ROAD" 359 "UNACCOMPANIED_UNDERAGE_RIDER_DETECTED" 358 "AEB_FAULTED" 357 "AUDIO_HARDWARE_ODIN_FAILED" 356 "FASCIA_VISION_FAILSAFE_PARKED" 355 "APS_B_EPLANNER_NO_VALID_TRAJECTORY" 354 "APS_A_EPLANNER_NO_VALID_TRAJECTORY" 353 "FASCIA_CAM_INTEGRATED_HEATER_FAULT" 352 "BACKUP_CAM_INTEGRATED_HEATER_FAULT" 351 "RIGHT_REPEATER_CAM_INTEGRATED_HEATER_FAULT" 350 "LEFT_REPEATER_CAM_INTEGRATED_HEATER_FAULT" 349 "RIGHT_PILLAR_CAM_INTEGRATED_HEATER_FAULT" 348 "LEFT_PILLAR_CAM_INTEGRATED_HEATER_FAULT" 347 "RIGHT_PILLAR_CAM_WIRE_HEATER_FAULT" 346 "LEFT_PILLAR_CAM_WIRE_HEATER_FAULT" 345 "WINDSHIELD_CAM_WIRE_HEATER_FAULT" 344 "CONTROLLER_EPLANNER_UNHEALTHY" 343 "VEHICLE_COLLISION_DETECTED" 342 "VRU_COLLISION_DETECTED" 341 "MAJOR_COLLISION_DETECTED" 340 "ONGOING_COLLISION_DETECTED" 339 "INTEGRATOR_ACCELERATION_INVALID" 338 "CABIN_CAM_DRIVER_MONITORING_SYSTEM_UNAVAILABLE" 337 "DCAS_DRIVER_ATTENTION_STATE_DETERMINATION_DEGRADED" 336 "NON_MAIN_FRONT_CAMERAS_STREAM_LOST" 335 "MAIN_CAMERA_STREAM_LOST" 334 "DRIVER_WIPER_WASH_HEALTH_DEGRADED" 333 "EPB_AUTONOMY_BEHAVIOR_MISMATCH" 332 "DI_AUTONOMY_BEHAVIOR_MISMATCH" 331 "VC_AUTONOMY_BEHAVIOR_MISMATCH" 330 "DCAS_EXITED_REGION_TIMEOUT" 329 "WASHER_PUMP_NOT_HEALTHY" 328 "AP_B_SOC_UNHEALTHY" 327 "RCM_AIR_BAG_DEPLOY" 326 "RCM_NEAR_DEPLOY" 325 "AP_A_SOC_UNHEALTHY" 324 "ROUTE_EXCEEDS_SPEED_LIMIT" 323 "PERSISTENT_INVALID_NAV_ROUTE" 322 "NAV_ROUTE_EXITS_GEOFENCE" 321 "NAV_AVOID_HIGH_SPEED_ROADS_DISABLED" 320 "NAV_WHITELIST_ROUTING_DISABLED" 319 "NAV_ROUTE_RANKER_DISABLED" 318 "NAV_AVOID_SHORT_LANE_CHANGE_DISABLED" 317 "NAV_AVOID_UNPROTECTED_TURN_DISABLED" 316 "HIGHWAY_ON_ROUTE" 315 "EGO_ON_HIGHWAY" 314 "INVALID_VEHICLE_OPERATION_MODE" 313 "STEERING_ANGLE_OFFSET_HIGH" 312 "SAFETY_DRIVER_INATTENTIVE" 311 "TRACK_MODE_ACTIVE" 310 "EXT_TEMP_LOW_CERAMIC_BRAKES" 309 "GOAL_NEAR_SUMMON_MAP_BOUNDARY" 308 "SUMMON_HEARTBEAT_MISSING" 307 "EGO_NEAR_SUMMON_MAP_BOUNDARY" 306 "EGO_OUTSIDE_SUMMON_MAP_RADIUS" 305 "SUMMON_MAP_INVALID" 304 "RAW_UI_SUMMON_GOAL_INVALID" 303 "SUMMON_GOAL_INVALID" 302 "SYSTEM_CDP_UNAVAILABLE" 301 "SUMMON_COLLISION_DETECTION_ACTIVE" 300 "PHONE_TOO_FAR" 299 "PHONE_GPS_INVALID" 298 "GRADE_TOO_HIGH_WITHOUT_REDUNDANT_BRAKING" 297 "CABIN_CAM_DRIVER_MONITORING_UNAVAILABLE" 296 "CABIN_CAMERA_STREAM_FAILURE" 295 "DRIVER_PRESENCE_VISION_UNAVAILABLE" 294 "PEDAL_OVERRIDE_EXCEEDS_CONTROLLER_LIMITS" 293 "UPCOMING_FERRY_CROSSING" 292 "DRIVER_PARTIALLY_OCCLUDED" 291 "DRIVER_REQUIREMENTS_NOT_MET_VC" 290 "DRIVER_AGE_REQUIREMENTS_NOT_MET_VISION" 289 "GPS_DEGRADED" 288 "PILLARS_SWAP_DETECTED" 287 "NARROW_FISHEYE_SWAP_DETECTED" 286 "SCCM_MIA" 285 "RECENT_STALK_GEAR_SHIFT" 284 "IBOOSTER_MIA" 283 "PARKING_SPOT_SELECTED" 282 "SCROLL_WHEEL_INTERACTION" 281 "PEDAL_OVERRIDE_STRIKEOUT_FOR_DRIVE" 280 "PEDAL_OVERRIDE_STRIKEOUT" 279 "ABOVE_MAX_ACTIVATION_SPEED" 278 "DRIVER_MONITOR_SUSPENSION_ACTIVE" 277 "DRIVER_MONITOR_STRUCK_OUT_FOR_DRIVE" 276 "VC_CAMERA_AIR_CLEANING_STATUS_MIA" 275 "VC_CAMERA_FLUID_CLEANING_STATUS_MIA" 274 "INVALID_DI_PEDAL_POS" 273 "CABIN_CAMERA_FAN_RPM_FAULT" 272 "SELF_NETWORK_DECRYPTION_NOT_READY" 271 "OFF_ROAD_MODE_ACTIVE" 270 "SSD_CLIP_LOGGING_INACTIVE" 269 "CAMERA_EXPOSURE_INACTIVE" 268 "CAMERA_EXPOSURE_MISMATCH" 267 "CABIN_CAMERA_IR_LED_FAULTED" 266 "TAMPERING_DETECTED" 265 "NO_IMU_SOURCES_AVAILABLE" 264 "IMU_REDUNDANCY_LOST" 263 "DI_AUTONOMY_HEALTH_CAN_MESSAGE_MIA" 262 "ALL_WHEEL_SPEEDS_SENSORS_FAULTED" 261 "WHEEL_SPEEDS_CAN_MESSAGE_MIA" 260 "AP_THERMAL_MODEL_FAULT_DETECTED" 259 "SGK_AUTONOMY_MODE_NOT_IN_SYNC" 258 "SGK_AUTONOMY_STATE_NOT_IN_SYNC" 257 "ANY_RIGHT_DOOR_OPEN_BUTTON_FAULTED" 256 "ANY_LEFT_DOOR_OPEN_BUTTON_FAULTED" 255 "VCRIGHT_DOOR_STATUS_CAN_MESSAGE_MIA" 254 "VCLEFT_DOOR_STATUS_CAN_MESSAGE_MIA" 253 "BB_STATUS_CAN_MESSAGE_MIA" 252 "GTW_CAR_CONFIG_CAN_MESSAGE_MIA" 251 "TRAILER_MODE_ACTIVE" 250 "UI_LIMIT_MODE_ACTIVE" 249 "UI_QT_CAR_UNAVAILABLE" 248 "UI_CONNECTIVITY_HW_UNHEALTHY" 247 "UI_CONNECTIVITY_OFFLINE" 246 "UI_CENTER_DISPLAY_UNAVAILABLE" 245 "UI_HEALTH_STATUS_CAN_MESSAGE_MIA" 244 "ANY_LV_HEALTH_CAN_MESSAGE_INVALID" 243 "ANY_LV_HEALTH_CAN_MESSAGE_MIA" 242 "AP_SYSTEM_ISSUE_PENDING_REBOOT" 241 "AP_TASK_PENDING_REBOOT" 240 "APS_DUAL_CAMERA_POWER_FAILURE" 239 "APS_SINGLE_CAMERA_POWER_FAILURE" 238 "APS_ETH_BRIDGE_DOWN" 237 "APS_PEER_PMIC_FAULTED" 236 "APS_SELF_PMIC_FAULTED" 235 "APS_PEER_VRM_FAULTED" 234 "APS_SELF_VRM_FAULTED" 233 "APS_PEER_IMEM_FAULTED" 232 "APS_SELF_IMEM_FAULTED" 231 "APS_PEER_CAN_FAULTED" 230 "APS_SELF_CAN_FAULTED" 229 "APS_B_UNHEALTHY" 228 "APS_A_UNHEALTHY" 227 "PEER_VISION_FAILOVER_ACTIVE" 226 "ARBITER_SELECTED_BEHAVIOR_OUT_OF_DATE" 225 "ARBITER_SELECTED_BEHAVIOR_NOT_E2E" 224 "MISSION_PLANNER_DESIRED_BEHAVIOR_NOT_E2E" 223 "AUTONOMY_CONTROLLING_AND_NOT_PARKED" 222 "NO_VALID_SGK_STATUS" 221 "AUTONOMOUS_BEHAVIORS_LINK_NOT_ESTABLISHED" 220 "GNSS_PPS_MIA" 219 "GNSS_ANTENNA_DISCONNECTED" 218 "GNSS_UART_FAULTED" 217 "AP_THERMAL_DEGRADED_PULLOVER_REQ" 216 "AP_THERMAL_DEGRADED_BLOCK_ACTIVATION" 215 "DRIVER_PRESENT_NOT_ALLOWED" 214 "UNSUPERVISED_OPERATION_NOT_ALLOWED" 213 "NOT_IN_RT_NO_TAKEOVER_FLEET" 212 "SAFETY_OPERATOR_NOT_PRESENT" 211 "CAMERA_PRECONDITIONING_REQUIRED" 210 "BMS_CAN_MESSAGES_MIA" 209 "VEHICLE_LOSING_HV" 208 "HV_DRIVE_NO_RESTART" 207 "AUTONOMOUS_BEHAVIORS_TASK_SUSPENDING" 206 "AUDIO_BUS_DOWN" 205 "CAMERA_REDUNDANCY_NOT_READY" 204 "NO_VEHICLE_SPEED_SOURCE_AVAILABLE" 203 "DI_PRIMARY_SPEED_SOURCE_UNAVAILABLE" 202 "DI_SPEED_CAN_MESSAGE_MIA" 201 "DEFOG_SYSTEM_UNHEALTHY" 200 "COOLANT_SYSTEM_UNHEALTHY" 199 "DEFOG_SYSTEM_NOT_READY" 198 "COOLANT_SYSTEM_NOT_READY" 197 "NOT_AUTHENTICATED_FOR_DRIVE" 196 "UNASSIGNED_PASSENGER_UNBUCKLED" 195 "WAITING_FOR_PASSENGER_EGRESS" 194 "PASSENGER_UNEXPECTED_RIDE_INACTIVE" 193 "DRIVER_NOT_PRESENT_PRE_ACTIVATION" 192 "NARROW_WASH_NOT_AVAILABLE" 191 "REDUNDANT_IMU_CAN_MESSAGES_MIA" 190 "IMU_CAN_MESSAGES_MIA" 189 "BRAKING_CAN_MESSAGES_MIA" 188 "EPB_AUTONOMY_CAN_MESSAGES_MIA" 187 "PARK_BRAKE_CAN_MESSAGES_MIA" 186 "STEERING_CAN_MESSAGES_MIA" 185 "DI_SYSTEM_STATUS_CAN_MESSAGES_MIA" 184 "DI_CHASSIS_CONTROL_CAN_MESSAGE_MIA" 183 "APS_CAN_MESSAGES_MIA" 182 "POOR_LOCALIZATION_ACCURACY" 181 "VISION_FAILOVER_ACTIVE" 180 "SEAT_OCCUPANCY_STATUS_UNHEALTHY" 179 "TO_STREAMS_UNHEALTHY" 178 "SEATBELT_STATUS_UNHEALTHY" 177 "RCM_WARNING_INDICATOR_ON" 176 "REDUNDANT_BRAKES_FAIL_OPERATIONAL" 175 "REDUNDANT_BRAKES_REDUNDANCY_LOST" 174 "REDUNDANT_BRAKES_NOT_ARMED" 173 "REDUNDANT_BRAKES_NOT_READY" 172 "REDUNDANT_BRAKE_PATH_ACTIVE" 171 "RANKER_NOT_HEALTHY" 170 "PARKED_A_PEDAL_PRESSED" 169 "ANY_CANCEL_ACTIVE" 168 "BRAKE_CONFIRM_PENDING_PARK" 167 "BRAKE_APPLIED_D_R_N" 166 "BRAKE_RELEASE_PENDING_PARK" 165 "ENFORCED_UNPARK_DELAY_ACTIVE" 164 "WIPER_NOT_HEALTHY" 163 "RIGHT_PILLAR_CAM_HEATER_FAULT" 162 "LEFT_PILLAR_CAM_HEATER_FAULT" 161 "WINDSHIELD_CAM_HEATER_FAULT" 160 "ALL_TAIL_LIGHTS_FAULTED_IN_LOW_VIS" 159 "TAIL_LIGHT_FAULTED" 158 "REVERSE_LIGHT_FAULTED" 157 "RIGHT_TURN_LIGHT_FAULTED" 156 "LEFT_TURN_LIGHT_FAULTED" 155 "ALL_BRAKE_LIGHTS_FAULTED" 154 "BRAKE_LIGHT_FAULTED" 153 "HIGH_BEAM_LIGHT_FAULTED_IN_LOW_VIS" 152 "LOW_BEAM_LIGHT_FAULTED_IN_LOW_VIS" 151 "HIGH_BEAM_LIGHT_FAULTED" 150 "LOW_BEAM_LIGHT_FAULTED" 149 "HEADLIGHTS_NOT_AIMED" 148 "HEADLIGHTS_OFF_AT_NIGHT" 147 "AP_REDUNDANCY_UNAVAILABLE" 146 "DI_BRAKING_DECELERATION_UNAVAILABLE" 145 "DI_VDC_ACTIVE" 144 "DI_TC_ACTIVE" 143 "DI_VDC_STATE_NOT_NORMAL" 142 "DI_LOSING_PROPULSION" 141 "EPB_STATUS_NOT_PARKED" 140 "EPB_PARKING_AVAILABILITY_UNKNOWN" 139 "EPB_PARKING_AVAILABILITY_REQUEST_PATH_DEGRADED" 138 "EPB_PARKING_AVAILABILITY_SPEED_INVALID" 137 "EPB_PARKING_AVAILABILITY_FAULTED" 136 "TIRE_PRESSURE_SENSOR_FAULT" 135 "FLAT_TIRE" 134 "INTEGRATOR_HEALTH_CRITICAL" 133 "IMU_DATA_NOT_RELIABLE" 132 "FASCIA_FLUID_CLEAN_CRITICAL" 131 "BACKUP_FLUID_CLEAN_CRITICAL" 130 "RIGHT_REPEATER_FLUID_CLEAN_CRITICAL" 129 "LEFT_REPEATER_FLUID_CLEAN_CRITICAL" 128 "FASCIA_AIR_CLEAN_CRITICAL" 127 "BACKUP_AIR_CLEAN_CRITICAL" 126 "RIGHT_REPEATER_AIR_CLEAN_CRITICAL" 125 "LEFT_REPEATER_AIR_CLEAN_CRITICAL" 124 "FASCIA_FLUID_CLEAN_DEGRADED" 123 "BACKUP_FLUID_CLEAN_DEGRADED" 122 "RIGHT_REPEATER_FLUID_CLEAN_DEGRADED" 121 "LEFT_REPEATER_FLUID_CLEAN_DEGRADED" 120 "FASCIA_AIR_CLEAN_DEGRADED" 119 "BACKUP_AIR_CLEAN_DEGRADED" 118 "RIGHT_REPEATER_AIR_CLEAN_DEGRADED" 117 "LEFT_REPEATER_AIR_CLEAN_DEGRADED" 116 "TERTIARY_WASHER_FLUID_LOW" 115 "SECONDARY_WASHER_FLUID_LOW" 114 "WASHER_FLUID_LOW" 113 "ELEVATED_TIRE_PRESSURE_READING" 112 "LOW_TIRE_PRESSURE_READING" 111 "VISION_CABIN_OCCUPANCY_UNAVAILABLE" 110 "SGK_AUTOSTEER_MONITOR_ACTIVE" 109 "SGK_PLANNER_ACTIVE_D_R_N" 108 "FLEET_MAINTENANCE_EXPIRING_SOON" 107 "FLEET_MAINTENANCE_REQUIRED" 106 "CHARGE_CABLE_CONNECTED_OR_STATUS_UNKNOWN" 105 "PASSENGER_UNBUCKLED_ACTIVE_RIDE" 104 "PASSENGER_UNBUCKLED" 103 "SYSTEM_UNHEALTHY_DEV_OVERRIDE" 102 "SINGLE_SOC_HEALTHY_EXCEPTION" 101 "IMU_REPLICATION_NOT_READY" 100 "STATE_MACHINE_DISABLED" 99 "INCOMPATIBLE_SYSTEM_HEALTH" 98 "CABIN_CAM_BLINDED" 97 "RIDESHARE_INGRESS_NO_NAV_ROUTE" 96 "PASSENGER_EXPECTED" 95 "DRIVER_MONITOR_STRIKEOUT" 94 "DRIVER_NOT_PRESENT" 93 "CONTROLLER_SOLVER_CRITICAL" 92 "CONTROLLER_SOLVER_DEGRADED" 91 "CONTROLLER_DEGRADED_PEDAL_OVERRIDE" 90 "CONTROLLER_SOLVER_FAILURE" 89 "LV_CRITICAL_STATE" 88 "LV_DEGRADED_STATE" 87 "VEHICLE_AUTONOMY_BEHAVIOR_MISMATCH" 86 "CRUISE_STACK_MISMATCH" 85 "EPB_REDUNDANT_BRAKING_STATUS" 84 "EXTENDED_COMPUTE_INACTIVE_OTHER" 83 "EXTENDED_COMPUTE_TIME_SYNC_CRITICAL_DEGRADED" 82 "EXTENDED_COMPUTE_OTHER_SOC_STATE_UNKNOWN" 81 "EXTENDED_COMPUTE_OTHER_SOC_STATE_INACTIVE" 80 "EXTENDED_COMPUTE_PCIE_LINK_HEALTH" 79 "EXTENDED_COMPUTE_ETHERNET_LINK_HEALTH" 78 "EXTENDED_COMPUTE_OTHER_SOC_HEALTH_CRITICAL" 77 "EXTENDED_COMPUTE_OTHER_SOC_HEALTH_UNKNOWN" 76 "EXTENDED_COMPUTE_SOC_HEALTH_CRITICAL" 75 "EXTENDED_COMPUTE_SOC_HEALTH_UNKNOWN" 74 "FSD_FROM_PARK_DISABLED" 73 "NOT_IN_PARK_NO_TAKEOVER" 72 "NO_FIXED_ROUTE" 71 "NAV_GOAL_INVALID" 70 "ANY_EPAS_FAULT" 69 "EPAS_SYSTEM_TORQUE_REDUCED" 68 "EPAS_SECONDARY_MASTER" 67 "EPAS_REDUNDANCY_LOST" 66 "EPAS_DRIVERLESS_MODE_NOT_ACTIVE" 65 "EPAS_EAC_NOT_ACTIVE" 64 "EPAS_EAC_UNAVAILABLE" 63 "STEERING_ANGLE_INVALID" 62 "CRUISE_FAULT" 61 "CRUISE_NOT_ACTIVE_OTHER" 60 "CRUISE_NOT_ACTIVE_ESTOP" 59 "CRUISE_UNAVAILABLE_OTHER" 58 "CRUISE_UNAVAILABLE_BRAKE_APPLIED" 57 "NOT_POWER_STATE_DRIVE" 56 "FRUNK_OPEN" 55 "TRUNK_OPEN" 54 "PASSENGER_DOOR_OPEN" 53 "DRIVER_DOOR_OPEN" 52 "VISION_FPS_LOW_CAMERA_DROPS" 51 "VISION_LATENCY_HIGH" 50 "SAFETY_DRIVER_UNBUCKLED" 49 "FASCIA_VISION_OCCLUSION_AT_STOP" 48 "SEVERE_RIGHT_VISION_OCCLUSION_REVERSE" 47 "SEVERE_LEFT_VISION_OCCLUSION_REVERSE" 46 "SEVERE_BACKUP_VISION_OCCLUSION_REVERSE" 45 "SEVERE_RIGHT_VISION_OCCLUSION_MANEUVER" 44 "SEVERE_LEFT_VISION_OCCLUSION_MANEUVER" 43 "SEVERE_RIGHT_VISION_OCCLUSION" 42 "SEVERE_LEFT_VISION_OCCLUSION" 41 "SEVERE_MULTIPLE_FRONT_VISION_OCCLUSION" 40 "SEVERE_SINGLE_FRONT_VISION_OCCLUSION" 39 "CAMERA_HEALTH_METRICS_UNHEALTHY" 38 "VISION_SCENETAGS_UNHEALTHY" 37 "VISION_AUTOWIPER_UNHEALTHY" 36 "VISION_AUTOHIGHBEAM_UNHEALTHY" 35 "VISION_FAILSAFES_UNHEALTHY" 34 "RIGHT_VISION_FAILSAFE_PARKED" 33 "LEFT_VISION_FAILSAFE_PARKED" 32 "FRONT_VISION_FAILSAFE_PARKED" 31 "REAR_VISION_FAILSAFE_PARKED" 30 "CAMERA_OFFGASSING" 29 "CAMERA_OFFGASSING_PRE_ALERT" 28 "INTERMITTENT_FRAME_DROPS" 27 "CAMERA_AUTOEXPOSURE_LOST" 26 "OUT_OF_SYNC_CAMERA_STREAMS" 25 "FASCIA_CAMERA_STREAM_LOST" 24 "BACKUP_CAMERA_STREAM_LOST" 23 "RIGHT_CAMERAS_STREAM_LOST" 22 "LEFT_CAMERAS_STREAM_LOST" 21 "FRONT_CAMERAS_STREAM_LOST" 20 "CAMERA_MCU_FW_MISMATCH" 19 "FACTORY_CALIBRATION" 18 "CAMERA_PITCH_OUT_OF_BOUNDS" 17 "CAMERA_CALIBRATION" 16 "GNSS_DEGRADED_SIGNAL_STRENGTH" 15 "AP_POWER_REQUEST_NOT_NOMINAL" 14 "SENTRY_ACTIVE" 13 "NO_REDUNDANT_BRAKING" 12 "HK_RESTRICTED" 11 "OUTSIDE_GEOFENCE" 10 "RUN_MODE_NOT_FSD" 9 "AEB_ACTIVE" 8 "SUMMON_ACTIVE" 7 "AUTOPARK_ACTIVE" 6 "FSD_DISABLED" 5 "CAR_WASH_MODE" 4 "DELIVERED" 3 "NO_AUTONOMY_MODE_ACTIVE" 2 "NEUTRAL_GEAR" 1 "NONE" 0 "UNKNOWN" ;
VAL_ 1513 APP_sw465_reason2 414 "TRAJECTORY_ON_PUBLIC_ROAD_NOT_INDOORS" 413 "STOP_IN_LANE_NOT_HONORED" 412 "SIMPLE_SUMMON_OBSTACLE_BLOCKED" 411 "SEVERE_SINGLE_FRONT_VISION_OCCLUSION_AFTER_WIPE" 410 "PHONE_TOO_FAR_TO_START" 409 "MAX_SPEED_LIMIT_FOR_MODE_EXCEEDED" 408 "EPB_REDUNDANT_BRAKING_UNAVAILABLE" 407 "EGO_GEAR_NOT_ALLOWED" 406 "EGO_EXCEEDED_MAX_SUMMON_DISTANCE" 405 "DUAL_EPB_UNAVAILABLE" 404 "COMPRESSOR_FRAME_DROP_RATE_HIGH" 403 "CAN_RX_VALIDATION_ERROR" 402 "BRAKE_APPLIED_PARKED" 401 "ALARM_ACTIVE" 400 "SAFETY_DRIVER_UNBUCKLED_PRE_ACTIVATION" 399 "NOT_FACTORY_SCHEDULE" 398 "FSD_REGION_NOT_ALLOWED" 397 "FSD_QUIZ_REQUIRED" 396 "EPAS_EAC_NOT_ACTIVE_OTHER" 395 "EPAS_EAC_NOT_ACTIVE_HANDS_ON" 394 "DI_CONTROL_INTEGRATOR_WINDUP" 393 "SEVERE_SINGLE_FRONT_VISION_OCCLUSION_HIGH_FOGGING_RISK" 392 "EGO_NEAR_SUMMON_MAP_BOUNDARY_NOT_INDOORS" 391 "GOAL_NEAR_SUMMON_MAP_BOUNDARY_NOT_INDOORS" 390 "GRADE_TOO_HIGH_WITHOUT_REDUNDANT_BRAKING_LOW_MU" 389 "NAV_DESTINATION_OUTSIDE_GEOFENCE" 388 "RCM_COLLISION_SEVERITY_TRIGGERED" 387 "EPB_PARKING_AVAILABILITY_TOO_STEEP" 386 "REVERSE_GEAR_NOT_AVAILABLE" 385 "DESTINATION_OUTSIDE_GEOFENCE_AP" 384 "SSD_CLIP_LOGGING_CRITICAL" 383 "DRIVE_GEAR_NOT_AVAILABLE" 382 "SIDE_VISIBILITY_DEGRADED_PARKED_DOORS_CLOSED" 381 "PERSISTENT_FRAME_DROPS" 380 "PERSISTENT_HANDS_ON_NOT_ALLOWED" 379 "NAV_ROUTE_EXCEEDS_GEOFENCE_BUFFER" 378 "RANKER_OUTPUT_STALE" 377 "VISION_PLANNER_STALE" 376 "AUTO_WIPERS_OFF" 375 "COUNTRY_NOT_ALLOWED_FOR_OPERATION" 374 "OUTSIDE_TRACK_TEST_GEOFENCE" 373 "TEMPERATURE_EXCEEDS_ODD" 372 "RIDESHARE_NAV_GOAL_NOT_IN_SYNC" 371 "HV_BATTERY_AC_CHARGING_UNHEALTHY" 370 "HV_BATTERY_DC_CHARGING_UNHEALTHY" 369 "UI_RIDE_SETUP_IN_PROGRESS" 368 "AUTO_HEADLIGHTS_OFF" 367 "IMMOBILIZER_AUTH_AUTONOMY" 366 "DI_RESTRICTED_DRIVING_MANUAL_RECOVERY" 365 "SUMMON_ACTIVE_DURATION_EXCEEDED" 364 "ESKF_SPEED_SOURCE_ACTIVE" 363 "IMU_DATA_NOT_RELIABLE_WITH_FLEET_CONFIG_ENABLED" 362 "FASCIA_VISION_OCCLUSION_AT_LONG_STOP" 361 "HIGH_SPEED_ROAD_ON_ROUTE" 360 "EGO_ON_HIGH_SPEED_ROAD" 359 "UNACCOMPANIED_UNDERAGE_RIDER_DETECTED" 358 "AEB_FAULTED" 357 "AUDIO_HARDWARE_ODIN_FAILED" 356 "FASCIA_VISION_FAILSAFE_PARKED" 355 "APS_B_EPLANNER_NO_VALID_TRAJECTORY" 354 "APS_A_EPLANNER_NO_VALID_TRAJECTORY" 353 "FASCIA_CAM_INTEGRATED_HEATER_FAULT" 352 "BACKUP_CAM_INTEGRATED_HEATER_FAULT" 351 "RIGHT_REPEATER_CAM_INTEGRATED_HEATER_FAULT" 350 "LEFT_REPEATER_CAM_INTEGRATED_HEATER_FAULT" 349 "RIGHT_PILLAR_CAM_INTEGRATED_HEATER_FAULT" 348 "LEFT_PILLAR_CAM_INTEGRATED_HEATER_FAULT" 347 "RIGHT_PILLAR_CAM_WIRE_HEATER_FAULT" 346 "LEFT_PILLAR_CAM_WIRE_HEATER_FAULT" 345 "WINDSHIELD_CAM_WIRE_HEATER_FAULT" 344 "CONTROLLER_EPLANNER_UNHEALTHY" 343 "VEHICLE_COLLISION_DETECTED" 342 "VRU_COLLISION_DETECTED" 341 "MAJOR_COLLISION_DETECTED" 340 "ONGOING_COLLISION_DETECTED" 339 "INTEGRATOR_ACCELERATION_INVALID" 338 "CABIN_CAM_DRIVER_MONITORING_SYSTEM_UNAVAILABLE" 337 "DCAS_DRIVER_ATTENTION_STATE_DETERMINATION_DEGRADED" 336 "NON_MAIN_FRONT_CAMERAS_STREAM_LOST" 335 "MAIN_CAMERA_STREAM_LOST" 334 "DRIVER_WIPER_WASH_HEALTH_DEGRADED" 333 "EPB_AUTONOMY_BEHAVIOR_MISMATCH" 332 "DI_AUTONOMY_BEHAVIOR_MISMATCH" 331 "VC_AUTONOMY_BEHAVIOR_MISMATCH" 330 "DCAS_EXITED_REGION_TIMEOUT" 329 "WASHER_PUMP_NOT_HEALTHY" 328 "AP_B_SOC_UNHEALTHY" 327 "RCM_AIR_BAG_DEPLOY" 326 "RCM_NEAR_DEPLOY" 325 "AP_A_SOC_UNHEALTHY" 324 "ROUTE_EXCEEDS_SPEED_LIMIT" 323 "PERSISTENT_INVALID_NAV_ROUTE" 322 "NAV_ROUTE_EXITS_GEOFENCE" 321 "NAV_AVOID_HIGH_SPEED_ROADS_DISABLED" 320 "NAV_WHITELIST_ROUTING_DISABLED" 319 "NAV_ROUTE_RANKER_DISABLED" 318 "NAV_AVOID_SHORT_LANE_CHANGE_DISABLED" 317 "NAV_AVOID_UNPROTECTED_TURN_DISABLED" 316 "HIGHWAY_ON_ROUTE" 315 "EGO_ON_HIGHWAY" 314 "INVALID_VEHICLE_OPERATION_MODE" 313 "STEERING_ANGLE_OFFSET_HIGH" 312 "SAFETY_DRIVER_INATTENTIVE" 311 "TRACK_MODE_ACTIVE" 310 "EXT_TEMP_LOW_CERAMIC_BRAKES" 309 "GOAL_NEAR_SUMMON_MAP_BOUNDARY" 308 "SUMMON_HEARTBEAT_MISSING" 307 "EGO_NEAR_SUMMON_MAP_BOUNDARY" 306 "EGO_OUTSIDE_SUMMON_MAP_RADIUS" 305 "SUMMON_MAP_INVALID" 304 "RAW_UI_SUMMON_GOAL_INVALID" 303 "SUMMON_GOAL_INVALID" 302 "SYSTEM_CDP_UNAVAILABLE" 301 "SUMMON_COLLISION_DETECTION_ACTIVE" 300 "PHONE_TOO_FAR" 299 "PHONE_GPS_INVALID" 298 "GRADE_TOO_HIGH_WITHOUT_REDUNDANT_BRAKING" 297 "CABIN_CAM_DRIVER_MONITORING_UNAVAILABLE" 296 "CABIN_CAMERA_STREAM_FAILURE" 295 "DRIVER_PRESENCE_VISION_UNAVAILABLE" 294 "PEDAL_OVERRIDE_EXCEEDS_CONTROLLER_LIMITS" 293 "UPCOMING_FERRY_CROSSING" 292 "DRIVER_PARTIALLY_OCCLUDED" 291 "DRIVER_REQUIREMENTS_NOT_MET_VC" 290 "DRIVER_AGE_REQUIREMENTS_NOT_MET_VISION" 289 "GPS_DEGRADED" 288 "PILLARS_SWAP_DETECTED" 287 "NARROW_FISHEYE_SWAP_DETECTED" 286 "SCCM_MIA" 285 "RECENT_STALK_GEAR_SHIFT" 284 "IBOOSTER_MIA" 283 "PARKING_SPOT_SELECTED" 282 "SCROLL_WHEEL_INTERACTION" 281 "PEDAL_OVERRIDE_STRIKEOUT_FOR_DRIVE" 280 "PEDAL_OVERRIDE_STRIKEOUT" 279 "ABOVE_MAX_ACTIVATION_SPEED" 278 "DRIVER_MONITOR_SUSPENSION_ACTIVE" 277 "DRIVER_MONITOR_STRUCK_OUT_FOR_DRIVE" 276 "VC_CAMERA_AIR_CLEANING_STATUS_MIA" 275 "VC_CAMERA_FLUID_CLEANING_STATUS_MIA" 274 "INVALID_DI_PEDAL_POS" 273 "CABIN_CAMERA_FAN_RPM_FAULT" 272 "SELF_NETWORK_DECRYPTION_NOT_READY" 271 "OFF_ROAD_MODE_ACTIVE" 270 "SSD_CLIP_LOGGING_INACTIVE" 269 "CAMERA_EXPOSURE_INACTIVE" 268 "CAMERA_EXPOSURE_MISMATCH" 267 "CABIN_CAMERA_IR_LED_FAULTED" 266 "TAMPERING_DETECTED" 265 "NO_IMU_SOURCES_AVAILABLE" 264 "IMU_REDUNDANCY_LOST" 263 "DI_AUTONOMY_HEALTH_CAN_MESSAGE_MIA" 262 "ALL_WHEEL_SPEEDS_SENSORS_FAULTED" 261 "WHEEL_SPEEDS_CAN_MESSAGE_MIA" 260 "AP_THERMAL_MODEL_FAULT_DETECTED" 259 "SGK_AUTONOMY_MODE_NOT_IN_SYNC" 258 "SGK_AUTONOMY_STATE_NOT_IN_SYNC" 257 "ANY_RIGHT_DOOR_OPEN_BUTTON_FAULTED" 256 "ANY_LEFT_DOOR_OPEN_BUTTON_FAULTED" 255 "VCRIGHT_DOOR_STATUS_CAN_MESSAGE_MIA" 254 "VCLEFT_DOOR_STATUS_CAN_MESSAGE_MIA" 253 "BB_STATUS_CAN_MESSAGE_MIA" 252 "GTW_CAR_CONFIG_CAN_MESSAGE_MIA" 251 "TRAILER_MODE_ACTIVE" 250 "UI_LIMIT_MODE_ACTIVE" 249 "UI_QT_CAR_UNAVAILABLE" 248 "UI_CONNECTIVITY_HW_UNHEALTHY" 247 "UI_CONNECTIVITY_OFFLINE" 246 "UI_CENTER_DISPLAY_UNAVAILABLE" 245 "UI_HEALTH_STATUS_CAN_MESSAGE_MIA" 244 "ANY_LV_HEALTH_CAN_MESSAGE_INVALID" 243 "ANY_LV_HEALTH_CAN_MESSAGE_MIA" 242 "AP_SYSTEM_ISSUE_PENDING_REBOOT" 241 "AP_TASK_PENDING_REBOOT" 240 "APS_DUAL_CAMERA_POWER_FAILURE" 239 "APS_SINGLE_CAMERA_POWER_FAILURE" 238 "APS_ETH_BRIDGE_DOWN" 237 "APS_PEER_PMIC_FAULTED" 236 "APS_SELF_PMIC_FAULTED" 235 "APS_PEER_VRM_FAULTED" 234 "APS_SELF_VRM_FAULTED" 233 "APS_PEER_IMEM_FAULTED" 232 "APS_SELF_IMEM_FAULTED" 231 "APS_PEER_CAN_FAULTED" 230 "APS_SELF_CAN_FAULTED" 229 "APS_B_UNHEALTHY" 228 "APS_A_UNHEALTHY" 227 "PEER_VISION_FAILOVER_ACTIVE" 226 "ARBITER_SELECTED_BEHAVIOR_OUT_OF_DATE" 225 "ARBITER_SELECTED_BEHAVIOR_NOT_E2E" 224 "MISSION_PLANNER_DESIRED_BEHAVIOR_NOT_E2E" 223 "AUTONOMY_CONTROLLING_AND_NOT_PARKED" 222 "NO_VALID_SGK_STATUS" 221 "AUTONOMOUS_BEHAVIORS_LINK_NOT_ESTABLISHED" 220 "GNSS_PPS_MIA" 219 "GNSS_ANTENNA_DISCONNECTED" 218 "GNSS_UART_FAULTED" 217 "AP_THERMAL_DEGRADED_PULLOVER_REQ" 216 "AP_THERMAL_DEGRADED_BLOCK_ACTIVATION" 215 "DRIVER_PRESENT_NOT_ALLOWED" 214 "UNSUPERVISED_OPERATION_NOT_ALLOWED" 213 "NOT_IN_RT_NO_TAKEOVER_FLEET" 212 "SAFETY_OPERATOR_NOT_PRESENT" 211 "CAMERA_PRECONDITIONING_REQUIRED" 210 "BMS_CAN_MESSAGES_MIA" 209 "VEHICLE_LOSING_HV" 208 "HV_DRIVE_NO_RESTART" 207 "AUTONOMOUS_BEHAVIORS_TASK_SUSPENDING" 206 "AUDIO_BUS_DOWN" 205 "CAMERA_REDUNDANCY_NOT_READY" 204 "NO_VEHICLE_SPEED_SOURCE_AVAILABLE" 203 "DI_PRIMARY_SPEED_SOURCE_UNAVAILABLE" 202 "DI_SPEED_CAN_MESSAGE_MIA" 201 "DEFOG_SYSTEM_UNHEALTHY" 200 "COOLANT_SYSTEM_UNHEALTHY" 199 "DEFOG_SYSTEM_NOT_READY" 198 "COOLANT_SYSTEM_NOT_READY" 197 "NOT_AUTHENTICATED_FOR_DRIVE" 196 "UNASSIGNED_PASSENGER_UNBUCKLED" 195 "WAITING_FOR_PASSENGER_EGRESS" 194 "PASSENGER_UNEXPECTED_RIDE_INACTIVE" 193 "DRIVER_NOT_PRESENT_PRE_ACTIVATION" 192 "NARROW_WASH_NOT_AVAILABLE" 191 "REDUNDANT_IMU_CAN_MESSAGES_MIA" 190 "IMU_CAN_MESSAGES_MIA" 189 "BRAKING_CAN_MESSAGES_MIA" 188 "EPB_AUTONOMY_CAN_MESSAGES_MIA" 187 "PARK_BRAKE_CAN_MESSAGES_MIA" 186 "STEERING_CAN_MESSAGES_MIA" 185 "DI_SYSTEM_STATUS_CAN_MESSAGES_MIA" 184 "DI_CHASSIS_CONTROL_CAN_MESSAGE_MIA" 183 "APS_CAN_MESSAGES_MIA" 182 "POOR_LOCALIZATION_ACCURACY" 181 "VISION_FAILOVER_ACTIVE" 180 "SEAT_OCCUPANCY_STATUS_UNHEALTHY" 179 "TO_STREAMS_UNHEALTHY" 178 "SEATBELT_STATUS_UNHEALTHY" 177 "RCM_WARNING_INDICATOR_ON" 176 "REDUNDANT_BRAKES_FAIL_OPERATIONAL" 175 "REDUNDANT_BRAKES_REDUNDANCY_LOST" 174 "REDUNDANT_BRAKES_NOT_ARMED" 173 "REDUNDANT_BRAKES_NOT_READY" 172 "REDUNDANT_BRAKE_PATH_ACTIVE" 171 "RANKER_NOT_HEALTHY" 170 "PARKED_A_PEDAL_PRESSED" 169 "ANY_CANCEL_ACTIVE" 168 "BRAKE_CONFIRM_PENDING_PARK" 167 "BRAKE_APPLIED_D_R_N" 166 "BRAKE_RELEASE_PENDING_PARK" 165 "ENFORCED_UNPARK_DELAY_ACTIVE" 164 "WIPER_NOT_HEALTHY" 163 "RIGHT_PILLAR_CAM_HEATER_FAULT" 162 "LEFT_PILLAR_CAM_HEATER_FAULT" 161 "WINDSHIELD_CAM_HEATER_FAULT" 160 "ALL_TAIL_LIGHTS_FAULTED_IN_LOW_VIS" 159 "TAIL_LIGHT_FAULTED" 158 "REVERSE_LIGHT_FAULTED" 157 "RIGHT_TURN_LIGHT_FAULTED" 156 "LEFT_TURN_LIGHT_FAULTED" 155 "ALL_BRAKE_LIGHTS_FAULTED" 154 "BRAKE_LIGHT_FAULTED" 153 "HIGH_BEAM_LIGHT_FAULTED_IN_LOW_VIS" 152 "LOW_BEAM_LIGHT_FAULTED_IN_LOW_VIS" 151 "HIGH_BEAM_LIGHT_FAULTED" 150 "LOW_BEAM_LIGHT_FAULTED" 149 "HEADLIGHTS_NOT_AIMED" 148 "HEADLIGHTS_OFF_AT_NIGHT" 147 "AP_REDUNDANCY_UNAVAILABLE" 146 "DI_BRAKING_DECELERATION_UNAVAILABLE" 145 "DI_VDC_ACTIVE" 144 "DI_TC_ACTIVE" 143 "DI_VDC_STATE_NOT_NORMAL" 142 "DI_LOSING_PROPULSION" 141 "EPB_STATUS_NOT_PARKED" 140 "EPB_PARKING_AVAILABILITY_UNKNOWN" 139 "EPB_PARKING_AVAILABILITY_REQUEST_PATH_DEGRADED" 138 "EPB_PARKING_AVAILABILITY_SPEED_INVALID" 137 "EPB_PARKING_AVAILABILITY_FAULTED" 136 "TIRE_PRESSURE_SENSOR_FAULT" 135 "FLAT_TIRE" 134 "INTEGRATOR_HEALTH_CRITICAL" 133 "IMU_DATA_NOT_RELIABLE" 132 "FASCIA_FLUID_CLEAN_CRITICAL" 131 "BACKUP_FLUID_CLEAN_CRITICAL" 130 "RIGHT_REPEATER_FLUID_CLEAN_CRITICAL" 129 "LEFT_REPEATER_FLUID_CLEAN_CRITICAL" 128 "FASCIA_AIR_CLEAN_CRITICAL" 127 "BACKUP_AIR_CLEAN_CRITICAL" 126 "RIGHT_REPEATER_AIR_CLEAN_CRITICAL" 125 "LEFT_REPEATER_AIR_CLEAN_CRITICAL" 124 "FASCIA_FLUID_CLEAN_DEGRADED" 123 "BACKUP_FLUID_CLEAN_DEGRADED" 122 "RIGHT_REPEATER_FLUID_CLEAN_DEGRADED" 121 "LEFT_REPEATER_FLUID_CLEAN_DEGRADED" 120 "FASCIA_AIR_CLEAN_DEGRADED" 119 "BACKUP_AIR_CLEAN_DEGRADED" 118 "RIGHT_REPEATER_AIR_CLEAN_DEGRADED" 117 "LEFT_REPEATER_AIR_CLEAN_DEGRADED" 116 "TERTIARY_WASHER_FLUID_LOW" 115 "SECONDARY_WASHER_FLUID_LOW" 114 "WASHER_FLUID_LOW" 113 "ELEVATED_TIRE_PRESSURE_READING" 112 "LOW_TIRE_PRESSURE_READING" 111 "VISION_CABIN_OCCUPANCY_UNAVAILABLE" 110 "SGK_AUTOSTEER_MONITOR_ACTIVE" 109 "SGK_PLANNER_ACTIVE_D_R_N" 108 "FLEET_MAINTENANCE_EXPIRING_SOON" 107 "FLEET_MAINTENANCE_REQUIRED" 106 "CHARGE_CABLE_CONNECTED_OR_STATUS_UNKNOWN" 105 "PASSENGER_UNBUCKLED_ACTIVE_RIDE" 104 "PASSENGER_UNBUCKLED" 103 "SYSTEM_UNHEALTHY_DEV_OVERRIDE" 102 "SINGLE_SOC_HEALTHY_EXCEPTION" 101 "IMU_REPLICATION_NOT_READY" 100 "STATE_MACHINE_DISABLED" 99 "INCOMPATIBLE_SYSTEM_HEALTH" 98 "CABIN_CAM_BLINDED" 97 "RIDESHARE_INGRESS_NO_NAV_ROUTE" 96 "PASSENGER_EXPECTED" 95 "DRIVER_MONITOR_STRIKEOUT" 94 "DRIVER_NOT_PRESENT" 93 "CONTROLLER_SOLVER_CRITICAL" 92 "CONTROLLER_SOLVER_DEGRADED" 91 "CONTROLLER_DEGRADED_PEDAL_OVERRIDE" 90 "CONTROLLER_SOLVER_FAILURE" 89 "LV_CRITICAL_STATE" 88 "LV_DEGRADED_STATE" 87 "VEHICLE_AUTONOMY_BEHAVIOR_MISMATCH" 86 "CRUISE_STACK_MISMATCH" 85 "EPB_REDUNDANT_BRAKING_STATUS" 84 "EXTENDED_COMPUTE_INACTIVE_OTHER" 83 "EXTENDED_COMPUTE_TIME_SYNC_CRITICAL_DEGRADED" 82 "EXTENDED_COMPUTE_OTHER_SOC_STATE_UNKNOWN" 81 "EXTENDED_COMPUTE_OTHER_SOC_STATE_INACTIVE" 80 "EXTENDED_COMPUTE_PCIE_LINK_HEALTH" 79 "EXTENDED_COMPUTE_ETHERNET_LINK_HEALTH" 78 "EXTENDED_COMPUTE_OTHER_SOC_HEALTH_CRITICAL" 77 "EXTENDED_COMPUTE_OTHER_SOC_HEALTH_UNKNOWN" 76 "EXTENDED_COMPUTE_SOC_HEALTH_CRITICAL" 75 "EXTENDED_COMPUTE_SOC_HEALTH_UNKNOWN" 74 "FSD_FROM_PARK_DISABLED" 73 "NOT_IN_PARK_NO_TAKEOVER" 72 "NO_FIXED_ROUTE" 71 "NAV_GOAL_INVALID" 70 "ANY_EPAS_FAULT" 69 "EPAS_SYSTEM_TORQUE_REDUCED" 68 "EPAS_SECONDARY_MASTER" 67 "EPAS_REDUNDANCY_LOST" 66 "EPAS_DRIVERLESS_MODE_NOT_ACTIVE" 65 "EPAS_EAC_NOT_ACTIVE" 64 "EPAS_EAC_UNAVAILABLE" 63 "STEERING_ANGLE_INVALID" 62 "CRUISE_FAULT" 61 "CRUISE_NOT_ACTIVE_OTHER" 60 "CRUISE_NOT_ACTIVE_ESTOP" 59 "CRUISE_UNAVAILABLE_OTHER" 58 "CRUISE_UNAVAILABLE_BRAKE_APPLIED" 57 "NOT_POWER_STATE_DRIVE" 56 "FRUNK_OPEN" 55 "TRUNK_OPEN" 54 "PASSENGER_DOOR_OPEN" 53 "DRIVER_DOOR_OPEN" 52 "VISION_FPS_LOW_CAMERA_DROPS" 51 "VISION_LATENCY_HIGH" 50 "SAFETY_DRIVER_UNBUCKLED" 49 "FASCIA_VISION_OCCLUSION_AT_STOP" 48 "SEVERE_RIGHT_VISION_OCCLUSION_REVERSE" 47 "SEVERE_LEFT_VISION_OCCLUSION_REVERSE" 46 "SEVERE_BACKUP_VISION_OCCLUSION_REVERSE" 45 "SEVERE_RIGHT_VISION_OCCLUSION_MANEUVER" 44 "SEVERE_LEFT_VISION_OCCLUSION_MANEUVER" 43 "SEVERE_RIGHT_VISION_OCCLUSION" 42 "SEVERE_LEFT_VISION_OCCLUSION" 41 "SEVERE_MULTIPLE_FRONT_VISION_OCCLUSION" 40 "SEVERE_SINGLE_FRONT_VISION_OCCLUSION" 39 "CAMERA_HEALTH_METRICS_UNHEALTHY" 38 "VISION_SCENETAGS_UNHEALTHY" 37 "VISION_AUTOWIPER_UNHEALTHY" 36 "VISION_AUTOHIGHBEAM_UNHEALTHY" 35 "VISION_FAILSAFES_UNHEALTHY" 34 "RIGHT_VISION_FAILSAFE_PARKED" 33 "LEFT_VISION_FAILSAFE_PARKED" 32 "FRONT_VISION_FAILSAFE_PARKED" 31 "REAR_VISION_FAILSAFE_PARKED" 30 "CAMERA_OFFGASSING" 29 "CAMERA_OFFGASSING_PRE_ALERT" 28 "INTERMITTENT_FRAME_DROPS" 27 "CAMERA_AUTOEXPOSURE_LOST" 26 "OUT_OF_SYNC_CAMERA_STREAMS" 25 "FASCIA_CAMERA_STREAM_LOST" 24 "BACKUP_CAMERA_STREAM_LOST" 23 "RIGHT_CAMERAS_STREAM_LOST" 22 "LEFT_CAMERAS_STREAM_LOST" 21 "FRONT_CAMERAS_STREAM_LOST" 20 "CAMERA_MCU_FW_MISMATCH" 19 "FACTORY_CALIBRATION" 18 "CAMERA_PITCH_OUT_OF_BOUNDS" 17 "CAMERA_CALIBRATION" 16 "GNSS_DEGRADED_SIGNAL_STRENGTH" 15 "AP_POWER_REQUEST_NOT_NOMINAL" 14 "SENTRY_ACTIVE" 13 "NO_REDUNDANT_BRAKING" 12 "HK_RESTRICTED" 11 "OUTSIDE_GEOFENCE" 10 "RUN_MODE_NOT_FSD" 9 "AEB_ACTIVE" 8 "SUMMON_ACTIVE" 7 "AUTOPARK_ACTIVE" 6 "FSD_DISABLED" 5 "CAR_WASH_MODE" 4 "DELIVERED" 3 "NO_AUTONOMY_MODE_ACTIVE" 2 "NEUTRAL_GEAR" 1 "NONE" 0 "UNKNOWN" ;
VAL_ 1513 APP_sw465_reason3 414 "TRAJECTORY_ON_PUBLIC_ROAD_NOT_INDOORS" 413 "STOP_IN_LANE_NOT_HONORED" 412 "SIMPLE_SUMMON_OBSTACLE_BLOCKED" 411 "SEVERE_SINGLE_FRONT_VISION_OCCLUSION_AFTER_WIPE" 410 "PHONE_TOO_FAR_TO_START" 409 "MAX_SPEED_LIMIT_FOR_MODE_EXCEEDED" 408 "EPB_REDUNDANT_BRAKING_UNAVAILABLE" 407 "EGO_GEAR_NOT_ALLOWED" 406 "EGO_EXCEEDED_MAX_SUMMON_DISTANCE" 405 "DUAL_EPB_UNAVAILABLE" 404 "COMPRESSOR_FRAME_DROP_RATE_HIGH" 403 "CAN_RX_VALIDATION_ERROR" 402 "BRAKE_APPLIED_PARKED" 401 "ALARM_ACTIVE" 400 "SAFETY_DRIVER_UNBUCKLED_PRE_ACTIVATION" 399 "NOT_FACTORY_SCHEDULE" 398 "FSD_REGION_NOT_ALLOWED" 397 "FSD_QUIZ_REQUIRED" 396 "EPAS_EAC_NOT_ACTIVE_OTHER" 395 "EPAS_EAC_NOT_ACTIVE_HANDS_ON" 394 "DI_CONTROL_INTEGRATOR_WINDUP" 393 "SEVERE_SINGLE_FRONT_VISION_OCCLUSION_HIGH_FOGGING_RISK" 392 "EGO_NEAR_SUMMON_MAP_BOUNDARY_NOT_INDOORS" 391 "GOAL_NEAR_SUMMON_MAP_BOUNDARY_NOT_INDOORS" 390 "GRADE_TOO_HIGH_WITHOUT_REDUNDANT_BRAKING_LOW_MU" 389 "NAV_DESTINATION_OUTSIDE_GEOFENCE" 388 "RCM_COLLISION_SEVERITY_TRIGGERED" 387 "EPB_PARKING_AVAILABILITY_TOO_STEEP" 386 "REVERSE_GEAR_NOT_AVAILABLE" 385 "DESTINATION_OUTSIDE_GEOFENCE_AP" 384 "SSD_CLIP_LOGGING_CRITICAL" 383 "DRIVE_GEAR_NOT_AVAILABLE" 382 "SIDE_VISIBILITY_DEGRADED_PARKED_DOORS_CLOSED" 381 "PERSISTENT_FRAME_DROPS" 380 "PERSISTENT_HANDS_ON_NOT_ALLOWED" 379 "NAV_ROUTE_EXCEEDS_GEOFENCE_BUFFER" 378 "RANKER_OUTPUT_STALE" 377 "VISION_PLANNER_STALE" 376 "AUTO_WIPERS_OFF" 375 "COUNTRY_NOT_ALLOWED_FOR_OPERATION" 374 "OUTSIDE_TRACK_TEST_GEOFENCE" 373 "TEMPERATURE_EXCEEDS_ODD" 372 "RIDESHARE_NAV_GOAL_NOT_IN_SYNC" 371 "HV_BATTERY_AC_CHARGING_UNHEALTHY" 370 "HV_BATTERY_DC_CHARGING_UNHEALTHY" 369 "UI_RIDE_SETUP_IN_PROGRESS" 368 "AUTO_HEADLIGHTS_OFF" 367 "IMMOBILIZER_AUTH_AUTONOMY" 366 "DI_RESTRICTED_DRIVING_MANUAL_RECOVERY" 365 "SUMMON_ACTIVE_DURATION_EXCEEDED" 364 "ESKF_SPEED_SOURCE_ACTIVE" 363 "IMU_DATA_NOT_RELIABLE_WITH_FLEET_CONFIG_ENABLED" 362 "FASCIA_VISION_OCCLUSION_AT_LONG_STOP" 361 "HIGH_SPEED_ROAD_ON_ROUTE" 360 "EGO_ON_HIGH_SPEED_ROAD" 359 "UNACCOMPANIED_UNDERAGE_RIDER_DETECTED" 358 "AEB_FAULTED" 357 "AUDIO_HARDWARE_ODIN_FAILED" 356 "FASCIA_VISION_FAILSAFE_PARKED" 355 "APS_B_EPLANNER_NO_VALID_TRAJECTORY" 354 "APS_A_EPLANNER_NO_VALID_TRAJECTORY" 353 "FASCIA_CAM_INTEGRATED_HEATER_FAULT" 352 "BACKUP_CAM_INTEGRATED_HEATER_FAULT" 351 "RIGHT_REPEATER_CAM_INTEGRATED_HEATER_FAULT" 350 "LEFT_REPEATER_CAM_INTEGRATED_HEATER_FAULT" 349 "RIGHT_PILLAR_CAM_INTEGRATED_HEATER_FAULT" 348 "LEFT_PILLAR_CAM_INTEGRATED_HEATER_FAULT" 347 "RIGHT_PILLAR_CAM_WIRE_HEATER_FAULT" 346 "LEFT_PILLAR_CAM_WIRE_HEATER_FAULT" 345 "WINDSHIELD_CAM_WIRE_HEATER_FAULT" 344 "CONTROLLER_EPLANNER_UNHEALTHY" 343 "VEHICLE_COLLISION_DETECTED" 342 "VRU_COLLISION_DETECTED" 341 "MAJOR_COLLISION_DETECTED" 340 "ONGOING_COLLISION_DETECTED" 339 "INTEGRATOR_ACCELERATION_INVALID" 338 "CABIN_CAM_DRIVER_MONITORING_SYSTEM_UNAVAILABLE" 337 "DCAS_DRIVER_ATTENTION_STATE_DETERMINATION_DEGRADED" 336 "NON_MAIN_FRONT_CAMERAS_STREAM_LOST" 335 "MAIN_CAMERA_STREAM_LOST" 334 "DRIVER_WIPER_WASH_HEALTH_DEGRADED" 333 "EPB_AUTONOMY_BEHAVIOR_MISMATCH" 332 "DI_AUTONOMY_BEHAVIOR_MISMATCH" 331 "VC_AUTONOMY_BEHAVIOR_MISMATCH" 330 "DCAS_EXITED_REGION_TIMEOUT" 329 "WASHER_PUMP_NOT_HEALTHY" 328 "AP_B_SOC_UNHEALTHY" 327 "RCM_AIR_BAG_DEPLOY" 326 "RCM_NEAR_DEPLOY" 325 "AP_A_SOC_UNHEALTHY" 324 "ROUTE_EXCEEDS_SPEED_LIMIT" 323 "PERSISTENT_INVALID_NAV_ROUTE" 322 "NAV_ROUTE_EXITS_GEOFENCE" 321 "NAV_AVOID_HIGH_SPEED_ROADS_DISABLED" 320 "NAV_WHITELIST_ROUTING_DISABLED" 319 "NAV_ROUTE_RANKER_DISABLED" 318 "NAV_AVOID_SHORT_LANE_CHANGE_DISABLED" 317 "NAV_AVOID_UNPROTECTED_TURN_DISABLED" 316 "HIGHWAY_ON_ROUTE" 315 "EGO_ON_HIGHWAY" 314 "INVALID_VEHICLE_OPERATION_MODE" 313 "STEERING_ANGLE_OFFSET_HIGH" 312 "SAFETY_DRIVER_INATTENTIVE" 311 "TRACK_MODE_ACTIVE" 310 "EXT_TEMP_LOW_CERAMIC_BRAKES" 309 "GOAL_NEAR_SUMMON_MAP_BOUNDARY" 308 "SUMMON_HEARTBEAT_MISSING" 307 "EGO_NEAR_SUMMON_MAP_BOUNDARY" 306 "EGO_OUTSIDE_SUMMON_MAP_RADIUS" 305 "SUMMON_MAP_INVALID" 304 "RAW_UI_SUMMON_GOAL_INVALID" 303 "SUMMON_GOAL_INVALID" 302 "SYSTEM_CDP_UNAVAILABLE" 301 "SUMMON_COLLISION_DETECTION_ACTIVE" 300 "PHONE_TOO_FAR" 299 "PHONE_GPS_INVALID" 298 "GRADE_TOO_HIGH_WITHOUT_REDUNDANT_BRAKING" 297 "CABIN_CAM_DRIVER_MONITORING_UNAVAILABLE" 296 "CABIN_CAMERA_STREAM_FAILURE" 295 "DRIVER_PRESENCE_VISION_UNAVAILABLE" 294 "PEDAL_OVERRIDE_EXCEEDS_CONTROLLER_LIMITS" 293 "UPCOMING_FERRY_CROSSING" 292 "DRIVER_PARTIALLY_OCCLUDED" 291 "DRIVER_REQUIREMENTS_NOT_MET_VC" 290 "DRIVER_AGE_REQUIREMENTS_NOT_MET_VISION" 289 "GPS_DEGRADED" 288 "PILLARS_SWAP_DETECTED" 287 "NARROW_FISHEYE_SWAP_DETECTED" 286 "SCCM_MIA" 285 "RECENT_STALK_GEAR_SHIFT" 284 "IBOOSTER_MIA" 283 "PARKING_SPOT_SELECTED" 282 "SCROLL_WHEEL_INTERACTION" 281 "PEDAL_OVERRIDE_STRIKEOUT_FOR_DRIVE" 280 "PEDAL_OVERRIDE_STRIKEOUT" 279 "ABOVE_MAX_ACTIVATION_SPEED" 278 "DRIVER_MONITOR_SUSPENSION_ACTIVE" 277 "DRIVER_MONITOR_STRUCK_OUT_FOR_DRIVE" 276 "VC_CAMERA_AIR_CLEANING_STATUS_MIA" 275 "VC_CAMERA_FLUID_CLEANING_STATUS_MIA" 274 "INVALID_DI_PEDAL_POS" 273 "CABIN_CAMERA_FAN_RPM_FAULT" 272 "SELF_NETWORK_DECRYPTION_NOT_READY" 271 "OFF_ROAD_MODE_ACTIVE" 270 "SSD_CLIP_LOGGING_INACTIVE" 269 "CAMERA_EXPOSURE_INACTIVE" 268 "CAMERA_EXPOSURE_MISMATCH" 267 "CABIN_CAMERA_IR_LED_FAULTED" 266 "TAMPERING_DETECTED" 265 "NO_IMU_SOURCES_AVAILABLE" 264 "IMU_REDUNDANCY_LOST" 263 "DI_AUTONOMY_HEALTH_CAN_MESSAGE_MIA" 262 "ALL_WHEEL_SPEEDS_SENSORS_FAULTED" 261 "WHEEL_SPEEDS_CAN_MESSAGE_MIA" 260 "AP_THERMAL_MODEL_FAULT_DETECTED" 259 "SGK_AUTONOMY_MODE_NOT_IN_SYNC" 258 "SGK_AUTONOMY_STATE_NOT_IN_SYNC" 257 "ANY_RIGHT_DOOR_OPEN_BUTTON_FAULTED" 256 "ANY_LEFT_DOOR_OPEN_BUTTON_FAULTED" 255 "VCRIGHT_DOOR_STATUS_CAN_MESSAGE_MIA" 254 "VCLEFT_DOOR_STATUS_CAN_MESSAGE_MIA" 253 "BB_STATUS_CAN_MESSAGE_MIA" 252 "GTW_CAR_CONFIG_CAN_MESSAGE_MIA" 251 "TRAILER_MODE_ACTIVE" 250 "UI_LIMIT_MODE_ACTIVE" 249 "UI_QT_CAR_UNAVAILABLE" 248 "UI_CONNECTIVITY_HW_UNHEALTHY" 247 "UI_CONNECTIVITY_OFFLINE" 246 "UI_CENTER_DISPLAY_UNAVAILABLE" 245 "UI_HEALTH_STATUS_CAN_MESSAGE_MIA" 244 "ANY_LV_HEALTH_CAN_MESSAGE_INVALID" 243 "ANY_LV_HEALTH_CAN_MESSAGE_MIA" 242 "AP_SYSTEM_ISSUE_PENDING_REBOOT" 241 "AP_TASK_PENDING_REBOOT" 240 "APS_DUAL_CAMERA_POWER_FAILURE" 239 "APS_SINGLE_CAMERA_POWER_FAILURE" 238 "APS_ETH_BRIDGE_DOWN" 237 "APS_PEER_PMIC_FAULTED" 236 "APS_SELF_PMIC_FAULTED" 235 "APS_PEER_VRM_FAULTED" 234 "APS_SELF_VRM_FAULTED" 233 "APS_PEER_IMEM_FAULTED" 232 "APS_SELF_IMEM_FAULTED" 231 "APS_PEER_CAN_FAULTED" 230 "APS_SELF_CAN_FAULTED" 229 "APS_B_UNHEALTHY" 228 "APS_A_UNHEALTHY" 227 "PEER_VISION_FAILOVER_ACTIVE" 226 "ARBITER_SELECTED_BEHAVIOR_OUT_OF_DATE" 225 "ARBITER_SELECTED_BEHAVIOR_NOT_E2E" 224 "MISSION_PLANNER_DESIRED_BEHAVIOR_NOT_E2E" 223 "AUTONOMY_CONTROLLING_AND_NOT_PARKED" 222 "NO_VALID_SGK_STATUS" 221 "AUTONOMOUS_BEHAVIORS_LINK_NOT_ESTABLISHED" 220 "GNSS_PPS_MIA" 219 "GNSS_ANTENNA_DISCONNECTED" 218 "GNSS_UART_FAULTED" 217 "AP_THERMAL_DEGRADED_PULLOVER_REQ" 216 "AP_THERMAL_DEGRADED_BLOCK_ACTIVATION" 215 "DRIVER_PRESENT_NOT_ALLOWED" 214 "UNSUPERVISED_OPERATION_NOT_ALLOWED" 213 "NOT_IN_RT_NO_TAKEOVER_FLEET" 212 "SAFETY_OPERATOR_NOT_PRESENT" 211 "CAMERA_PRECONDITIONING_REQUIRED" 210 "BMS_CAN_MESSAGES_MIA" 209 "VEHICLE_LOSING_HV" 208 "HV_DRIVE_NO_RESTART" 207 "AUTONOMOUS_BEHAVIORS_TASK_SUSPENDING" 206 "AUDIO_BUS_DOWN" 205 "CAMERA_REDUNDANCY_NOT_READY" 204 "NO_VEHICLE_SPEED_SOURCE_AVAILABLE" 203 "DI_PRIMARY_SPEED_SOURCE_UNAVAILABLE" 202 "DI_SPEED_CAN_MESSAGE_MIA" 201 "DEFOG_SYSTEM_UNHEALTHY" 200 "COOLANT_SYSTEM_UNHEALTHY" 199 "DEFOG_SYSTEM_NOT_READY" 198 "COOLANT_SYSTEM_NOT_READY" 197 "NOT_AUTHENTICATED_FOR_DRIVE" 196 "UNASSIGNED_PASSENGER_UNBUCKLED" 195 "WAITING_FOR_PASSENGER_EGRESS" 194 "PASSENGER_UNEXPECTED_RIDE_INACTIVE" 193 "DRIVER_NOT_PRESENT_PRE_ACTIVATION" 192 "NARROW_WASH_NOT_AVAILABLE" 191 "REDUNDANT_IMU_CAN_MESSAGES_MIA" 190 "IMU_CAN_MESSAGES_MIA" 189 "BRAKING_CAN_MESSAGES_MIA" 188 "EPB_AUTONOMY_CAN_MESSAGES_MIA" 187 "PARK_BRAKE_CAN_MESSAGES_MIA" 186 "STEERING_CAN_MESSAGES_MIA" 185 "DI_SYSTEM_STATUS_CAN_MESSAGES_MIA" 184 "DI_CHASSIS_CONTROL_CAN_MESSAGE_MIA" 183 "APS_CAN_MESSAGES_MIA" 182 "POOR_LOCALIZATION_ACCURACY" 181 "VISION_FAILOVER_ACTIVE" 180 "SEAT_OCCUPANCY_STATUS_UNHEALTHY" 179 "TO_STREAMS_UNHEALTHY" 178 "SEATBELT_STATUS_UNHEALTHY" 177 "RCM_WARNING_INDICATOR_ON" 176 "REDUNDANT_BRAKES_FAIL_OPERATIONAL" 175 "REDUNDANT_BRAKES_REDUNDANCY_LOST" 174 "REDUNDANT_BRAKES_NOT_ARMED" 173 "REDUNDANT_BRAKES_NOT_READY" 172 "REDUNDANT_BRAKE_PATH_ACTIVE" 171 "RANKER_NOT_HEALTHY" 170 "PARKED_A_PEDAL_PRESSED" 169 "ANY_CANCEL_ACTIVE" 168 "BRAKE_CONFIRM_PENDING_PARK" 167 "BRAKE_APPLIED_D_R_N" 166 "BRAKE_RELEASE_PENDING_PARK" 165 "ENFORCED_UNPARK_DELAY_ACTIVE" 164 "WIPER_NOT_HEALTHY" 163 "RIGHT_PILLAR_CAM_HEATER_FAULT" 162 "LEFT_PILLAR_CAM_HEATER_FAULT" 161 "WINDSHIELD_CAM_HEATER_FAULT" 160 "ALL_TAIL_LIGHTS_FAULTED_IN_LOW_VIS" 159 "TAIL_LIGHT_FAULTED" 158 "REVERSE_LIGHT_FAULTED" 157 "RIGHT_TURN_LIGHT_FAULTED" 156 "LEFT_TURN_LIGHT_FAULTED" 155 "ALL_BRAKE_LIGHTS_FAULTED" 154 "BRAKE_LIGHT_FAULTED" 153 "HIGH_BEAM_LIGHT_FAULTED_IN_LOW_VIS" 152 "LOW_BEAM_LIGHT_FAULTED_IN_LOW_VIS" 151 "HIGH_BEAM_LIGHT_FAULTED" 150 "LOW_BEAM_LIGHT_FAULTED" 149 "HEADLIGHTS_NOT_AIMED" 148 "HEADLIGHTS_OFF_AT_NIGHT" 147 "AP_REDUNDANCY_UNAVAILABLE" 146 "DI_BRAKING_DECELERATION_UNAVAILABLE" 145 "DI_VDC_ACTIVE" 144 "DI_TC_ACTIVE" 143 "DI_VDC_STATE_NOT_NORMAL" 142 "DI_LOSING_PROPULSION" 141 "EPB_STATUS_NOT_PARKED" 140 "EPB_PARKING_AVAILABILITY_UNKNOWN" 139 "EPB_PARKING_AVAILABILITY_REQUEST_PATH_DEGRADED" 138 "EPB_PARKING_AVAILABILITY_SPEED_INVALID" 137 "EPB_PARKING_AVAILABILITY_FAULTED" 136 "TIRE_PRESSURE_SENSOR_FAULT" 135 "FLAT_TIRE" 134 "INTEGRATOR_HEALTH_CRITICAL" 133 "IMU_DATA_NOT_RELIABLE" 132 "FASCIA_FLUID_CLEAN_CRITICAL" 131 "BACKUP_FLUID_CLEAN_CRITICAL" 130 "RIGHT_REPEATER_FLUID_CLEAN_CRITICAL" 129 "LEFT_REPEATER_FLUID_CLEAN_CRITICAL" 128 "FASCIA_AIR_CLEAN_CRITICAL" 127 "BACKUP_AIR_CLEAN_CRITICAL" 126 "RIGHT_REPEATER_AIR_CLEAN_CRITICAL" 125 "LEFT_REPEATER_AIR_CLEAN_CRITICAL" 124 "FASCIA_FLUID_CLEAN_DEGRADED" 123 "BACKUP_FLUID_CLEAN_DEGRADED" 122 "RIGHT_REPEATER_FLUID_CLEAN_DEGRADED" 121 "LEFT_REPEATER_FLUID_CLEAN_DEGRADED" 120 "FASCIA_AIR_CLEAN_DEGRADED" 119 "BACKUP_AIR_CLEAN_DEGRADED" 118 "RIGHT_REPEATER_AIR_CLEAN_DEGRADED" 117 "LEFT_REPEATER_AIR_CLEAN_DEGRADED" 116 "TERTIARY_WASHER_FLUID_LOW" 115 "SECONDARY_WASHER_FLUID_LOW" 114 "WASHER_FLUID_LOW" 113 "ELEVATED_TIRE_PRESSURE_READING" 112 "LOW_TIRE_PRESSURE_READING" 111 "VISION_CABIN_OCCUPANCY_UNAVAILABLE" 110 "SGK_AUTOSTEER_MONITOR_ACTIVE" 109 "SGK_PLANNER_ACTIVE_D_R_N" 108 "FLEET_MAINTENANCE_EXPIRING_SOON" 107 "FLEET_MAINTENANCE_REQUIRED" 106 "CHARGE_CABLE_CONNECTED_OR_STATUS_UNKNOWN" 105 "PASSENGER_UNBUCKLED_ACTIVE_RIDE" 104 "PASSENGER_UNBUCKLED" 103 "SYSTEM_UNHEALTHY_DEV_OVERRIDE" 102 "SINGLE_SOC_HEALTHY_EXCEPTION" 101 "IMU_REPLICATION_NOT_READY" 100 "STATE_MACHINE_DISABLED" 99 "INCOMPATIBLE_SYSTEM_HEALTH" 98 "CABIN_CAM_BLINDED" 97 "RIDESHARE_INGRESS_NO_NAV_ROUTE" 96 "PASSENGER_EXPECTED" 95 "DRIVER_MONITOR_STRIKEOUT" 94 "DRIVER_NOT_PRESENT" 93 "CONTROLLER_SOLVER_CRITICAL" 92 "CONTROLLER_SOLVER_DEGRADED" 91 "CONTROLLER_DEGRADED_PEDAL_OVERRIDE" 90 "CONTROLLER_SOLVER_FAILURE" 89 "LV_CRITICAL_STATE" 88 "LV_DEGRADED_STATE" 87 "VEHICLE_AUTONOMY_BEHAVIOR_MISMATCH" 86 "CRUISE_STACK_MISMATCH" 85 "EPB_REDUNDANT_BRAKING_STATUS" 84 "EXTENDED_COMPUTE_INACTIVE_OTHER" 83 "EXTENDED_COMPUTE_TIME_SYNC_CRITICAL_DEGRADED" 82 "EXTENDED_COMPUTE_OTHER_SOC_STATE_UNKNOWN" 81 "EXTENDED_COMPUTE_OTHER_SOC_STATE_INACTIVE" 80 "EXTENDED_COMPUTE_PCIE_LINK_HEALTH" 79 "EXTENDED_COMPUTE_ETHERNET_LINK_HEALTH" 78 "EXTENDED_COMPUTE_OTHER_SOC_HEALTH_CRITICAL" 77 "EXTENDED_COMPUTE_OTHER_SOC_HEALTH_UNKNOWN" 76 "EXTENDED_COMPUTE_SOC_HEALTH_CRITICAL" 75 "EXTENDED_COMPUTE_SOC_HEALTH_UNKNOWN" 74 "FSD_FROM_PARK_DISABLED" 73 "NOT_IN_PARK_NO_TAKEOVER" 72 "NO_FIXED_ROUTE" 71 "NAV_GOAL_INVALID" 70 "ANY_EPAS_FAULT" 69 "EPAS_SYSTEM_TORQUE_REDUCED" 68 "EPAS_SECONDARY_MASTER" 67 "EPAS_REDUNDANCY_LOST" 66 "EPAS_DRIVERLESS_MODE_NOT_ACTIVE" 65 "EPAS_EAC_NOT_ACTIVE" 64 "EPAS_EAC_UNAVAILABLE" 63 "STEERING_ANGLE_INVALID" 62 "CRUISE_FAULT" 61 "CRUISE_NOT_ACTIVE_OTHER" 60 "CRUISE_NOT_ACTIVE_ESTOP" 59 "CRUISE_UNAVAILABLE_OTHER" 58 "CRUISE_UNAVAILABLE_BRAKE_APPLIED" 57 "NOT_POWER_STATE_DRIVE" 56 "FRUNK_OPEN" 55 "TRUNK_OPEN" 54 "PASSENGER_DOOR_OPEN" 53 "DRIVER_DOOR_OPEN" 52 "VISION_FPS_LOW_CAMERA_DROPS" 51 "VISION_LATENCY_HIGH" 50 "SAFETY_DRIVER_UNBUCKLED" 49 "FASCIA_VISION_OCCLUSION_AT_STOP" 48 "SEVERE_RIGHT_VISION_OCCLUSION_REVERSE" 47 "SEVERE_LEFT_VISION_OCCLUSION_REVERSE" 46 "SEVERE_BACKUP_VISION_OCCLUSION_REVERSE" 45 "SEVERE_RIGHT_VISION_OCCLUSION_MANEUVER" 44 "SEVERE_LEFT_VISION_OCCLUSION_MANEUVER" 43 "SEVERE_RIGHT_VISION_OCCLUSION" 42 "SEVERE_LEFT_VISION_OCCLUSION" 41 "SEVERE_MULTIPLE_FRONT_VISION_OCCLUSION" 40 "SEVERE_SINGLE_FRONT_VISION_OCCLUSION" 39 "CAMERA_HEALTH_METRICS_UNHEALTHY" 38 "VISION_SCENETAGS_UNHEALTHY" 37 "VISION_AUTOWIPER_UNHEALTHY" 36 "VISION_AUTOHIGHBEAM_UNHEALTHY" 35 "VISION_FAILSAFES_UNHEALTHY" 34 "RIGHT_VISION_FAILSAFE_PARKED" 33 "LEFT_VISION_FAILSAFE_PARKED" 32 "FRONT_VISION_FAILSAFE_PARKED" 31 "REAR_VISION_FAILSAFE_PARKED" 30 "CAMERA_OFFGASSING" 29 "CAMERA_OFFGASSING_PRE_ALERT" 28 "INTERMITTENT_FRAME_DROPS" 27 "CAMERA_AUTOEXPOSURE_LOST" 26 "OUT_OF_SYNC_CAMERA_STREAMS" 25 "FASCIA_CAMERA_STREAM_LOST" 24 "BACKUP_CAMERA_STREAM_LOST" 23 "RIGHT_CAMERAS_STREAM_LOST" 22 "LEFT_CAMERAS_STREAM_LOST" 21 "FRONT_CAMERAS_STREAM_LOST" 20 "CAMERA_MCU_FW_MISMATCH" 19 "FACTORY_CALIBRATION" 18 "CAMERA_PITCH_OUT_OF_BOUNDS" 17 "CAMERA_CALIBRATION" 16 "GNSS_DEGRADED_SIGNAL_STRENGTH" 15 "AP_POWER_REQUEST_NOT_NOMINAL" 14 "SENTRY_ACTIVE" 13 "NO_REDUNDANT_BRAKING" 12 "HK_RESTRICTED" 11 "OUTSIDE_GEOFENCE" 10 "RUN_MODE_NOT_FSD" 9 "AEB_ACTIVE" 8 "SUMMON_ACTIVE" 7 "AUTOPARK_ACTIVE" 6 "FSD_DISABLED" 5 "CAR_WASH_MODE" 4 "DELIVERED" 3 "NO_AUTONOMY_MODE_ACTIVE" 2 "NEUTRAL_GEAR" 1 "NONE" 0 "UNKNOWN" ;
VAL_ 1513 APP_sw465_safeStateManeuver 2 "STOP_IN_LANE" 1 "PULLOVER" 0 "NONE" ;
VAL_ 1020 APP_decisionTemperature 0 "UNKNOWN" ;
VAL_ 1020 APP_pascalTemperature 0 "UNKNOWN" ;
VAL_ 1020 APP_parkerATemperature 0 "UNKNOWN" ;
VAL_ 1020 APP_parkerBTemperature 0 "UNKNOWN" ;
VAL_ 1020 APP_pascalExtTemperature 0 "UNKNOWN" ;
VAL_ 1020 APP_parkerExtTemperature 0 "UNKNOWN" ;
VAL_ 1020 APP_pascalHeaterDecision 1 "ON" 0 "OFF" ;
VAL_ 2046 APP_cameraPosition 10 "FASCIA" 9 "SELFIE" 8 "BACKUP" 7 "R_REPEATER" 6 "L_REPEATER" 5 "R_PILLAR" 4 "L_PILLAR" 3 "FISHEYE" 2 "NARROW" 1 "MAIN" 0 "INVALID" ;
VAL_ 2046 APP_mainCamExtPitchCal 511 "SNA" ;
VAL_ 2046 APP_mainCamExtYawCal 511 "SNA" ;
VAL_ 2046 APP_mainCalibTime 127 "SNA" ;
VAL_ 2046 APP_mainCalibProgress 127 "SNA" ;
VAL_ 2046 APP_narrowCamExtPitchCal 511 "SNA" ;
VAL_ 2046 APP_narrowCamExtYawCal 511 "SNA" ;
VAL_ 2046 APP_narrowCalibTime 127 "SNA" ;
VAL_ 2046 APP_narrowCalibProgress 127 "SNA" ;
VAL_ 2046 APP_fisheyeCamExtPitchCal 511 "SNA" ;
VAL_ 2046 APP_fisheyeCamExtYawCal 511 "SNA" ;
VAL_ 2046 APP_fisheyeCalibTime 127 "SNA" ;
VAL_ 2046 APP_fisheyeCalibProgress 127 "SNA" ;
VAL_ 2046 APP_lPillarCamExtPitchCal 511 "SNA" ;
VAL_ 2046 APP_lPillarCamExtYawCal 511 "SNA" ;
VAL_ 2046 APP_lPillarCalibTime 127 "SNA" ;
VAL_ 2046 APP_lPillarCalibProgress 127 "SNA" ;
VAL_ 2046 APP_rPillarCamExtPitchCal 511 "SNA" ;
VAL_ 2046 APP_rPillarCamExtYawCal 511 "SNA" ;
VAL_ 2046 APP_rPillarCalibTime 127 "SNA" ;
VAL_ 2046 APP_rPillarCalibProgress 127 "SNA" ;
VAL_ 2046 APP_lRepeatCamExtPitchCal 511 "SNA" ;
VAL_ 2046 APP_lRepeatCamExtYawCal 511 "SNA" ;
VAL_ 2046 APP_lRepeatCalibTime 127 "SNA" ;
VAL_ 2046 APP_lRepeatCalibProgress 127 "SNA" ;
VAL_ 2046 APP_rRepeatCamExtPitchCal 511 "SNA" ;
VAL_ 2046 APP_rRepeatCamExtYawCal 511 "SNA" ;
VAL_ 2046 APP_rRepeatCalibTime 127 "SNA" ;
VAL_ 2046 APP_rRepeatCalibProgress 127 "SNA" ;
VAL_ 2046 APP_backupCamExtPitchCal 511 "SNA" ;
VAL_ 2046 APP_backupCamExtYawCal 511 "SNA" ;
VAL_ 2046 APP_backupCalibTime 127 "SNA" ;
VAL_ 2046 APP_backupCalibProgress 127 "SNA" ;
VAL_ 2046 APP_fasciaCamExtPitchCal 511 "SNA" ;
VAL_ 2046 APP_fasciaCamExtYawCal 511 "SNA" ;
VAL_ 2046 APP_fasciaCalibTime 127 "SNA" ;
VAL_ 2046 APP_fasciaCalibProgress 127 "SNA" ;
VAL_ 1018 APP_mainCameraLUX 255 "SNA" 254 "SATURATED" ;
VAL_ 1018 APP_narrowCameraLUX 255 "SNA" 254 "SATURATED" ;
VAL_ 1018 APP_fisheyeCameraLUX 255 "SNA" 254 "SATURATED" ;
VAL_ 1018 APP_lRepeatCameraLUX 255 "SNA" 254 "SATURATED" ;
VAL_ 1018 APP_rRepeatCameraLUX 255 "SNA" 254 "SATURATED" ;
VAL_ 1018 APP_lPillarCameraLUX 255 "SNA" 254 "SATURATED" ;
VAL_ 1018 APP_rPillarCameraLUX 255 "SNA" 254 "SATURATED" ;
VAL_ 1018 APP_backupCameraLUX 255 "SNA" 254 "SATURATED" ;
VAL_ 1040 APP_fasciaCameraTemperature 255 "SNA" ;
VAL_ 1177 APP_rRepeaterCameraTemperature 255 "SNA" ;
VAL_ 1177 APP_lRepeaterCameraTemperature 255 "SNA" ;
VAL_ 2045 APP_cameraDefogMode 11 "CAMERA_DEFOG_DISABLE_START_FSD_BUTTON_NOT_ENABLED" 10 "CAMERA_DEFOG_DISABLE_NO_MIN_STANDBY_POWER" 9 "CAMERA_DEFOG_DISABLE_UNKNOWN" 8 "CAMERA_DEFOG_DISABLE_VEHICLE_NOT_DELIVERED" 7 "CAMERA_DEFOG_DISABLE_BAD_HW" 6 "CAMERA_DEFOG_DISABLE_FEATURE_FLAG_NOT_ENABLED" 5 "CAMERA_DEFOG_DISABLE_NOT_FSD_CAR" 4 "CAMERA_DEFOG_DISABLE_INDOORS" 3 "CAMERA_DEFOG_DISABLE_UI_FSD_NOT_ENABLED" 2 "CAMERA_DEFOG_DISABLE_LOW_SOC" 1 "CAMERA_DEFOG_ENABLE" 0 "CAMERA_DEFOG_SNA" ;
VAL_ 2045 APP_selfieCamFanRpm 65535 "SNA" ;
VAL_ 2045 APP_forceDefroster 3 "DEFROSTER_DEFROST" 2 "DEFROSTER_DEFOG" 1 "DEFROSTER_NONE" 0 "DEFROSTER_SNA" ;
VAL_ 2045 APP_checkThermalSysHealth 2 "EVAL_THERMAL" 1 "EVAL_NONE" 0 "EVAL_SNA" ;
VAL_ 2045 APP_hvacRequest 2 "ACTIVE" 1 "INACTIVE" 0 "SNA" ;
VAL_ 939 APP_attnMonitorVersion 7 "SNA" 1 "V1_1" 0 "V1_0" ;
VAL_ 939 APP_handsOnDetectedSource 7 "SNA" 3 "TORQUE_IGNORE_SELFIE_FOR_CAVEAT" 2 "TORQUE_AND_SELFIE" 1 "SELFIE" 0 "TORQUE" ;
VAL_ 939 APP_ADDWSystemStatus 3 "FAULTED" 2 "WARN" 1 "ACTIVE" 0 "INACTIVE" ;
VAL_ 939 APP_dmStrictness 3 "HIGH" 2 "MED" 1 "LOW" 0 "SNA" ;
VAL_ 939 APP_dmStrictnessReason 45 "UPCOMING_INTERSECTION" 44 "ON_HIGHWAY_CIPV_PRESENT" 43 "FAILSAFES_ACTIVE" 42 "LOW_SPEED_CIPV_PRESENT" 41 "RANKER_ACTIVATION" 40 "SPEED_BELOW_LOW_THRESHOLD_ON_CITY" 39 "UPCOMING_LATERAL_MANEUVER" 38 "WAITING_FOR_TRAFFIC_LIGHT" 37 "HIGH_LATERAL_ACCELERATION" 36 "DRIVER_FATIGUE_DETECTED" 35 "ON_INTERCHANGE" 34 "ON_RAMP" 33 "PERSISTED_OFFGASSING" 32 "AUTOHEADLIGHT_OFF" 31 "AUTOWIPER_OFF" 30 "CONSTRUCTION" 29 "ONCOMING_TRAFFIC_PRESENT" 28 "MED_STRICTNESS_SCENE_TAG_ACTIVE" 27 "REFERENCE_LATERAL_ERROR_WARNING" 26 "STEERING_ANGLE_OVER_THRESHOLD" 25 "SPEED_OVER_HIGH_THRESHOLD" 24 "SIDE_CAMERA_OCCLUSION" 23 "FSD_DEGRADED" 22 "INCLEMENT_WEATHER" 21 "SEVERE_RIGHT_VISION_OCCLUSION_REVERSE" 20 "SEVERE_LEFT_VISION_OCCLUSION_REVERSE" 19 "SEVERE_BACKUP_VISION_OCCLUSION_REVERSE" 18 "SEVERE_RIGHT_VISION_OCCLUSION_MANEUVER" 17 "SEVERE_LEFT_VISION_OCCLUSION_MANEUVER" 16 "SEVERE_SINGLE_FRONT_VISION_OCCLUSION" 15 "ESV_DETECTED" 14 "VRU_IN_DRIVABLE_SPACE" 13 "TOLLBOOTH" 12 "CAUTION_LIGHTS" 11 "ADVERSE_ROAD_CONDITIONS" 10 "HEAD_DOWN" 9 "HIGH_STRICTNESS_REQUIRED_FOR_DISTRACTION" 8 "PEDAL_OVERRIDE" 7 "HIGH_ACCEL_OR_DECEL" 6 "HIGH_STRICTNESS_DEV_CTRL" 5 "VISIBILITY_DEGRADED_OFFGASSING" 4 "FOLLOWING_CIPV_HIGH_DECEL" 3 "TRAFFIC_CONTROL_CONTEXT_RAILROAD" 2 "INCREASED_STRICTNESS_FOR_NON_REDUNDANT_EPAS" 1 "VISION_FAILSAFES_OVERRIDE_ACTIVE" 0 "SNA" ;
VAL_ 603 APP_offgassingSeverity 4 "APP_OFFGASSING_SEVERITY_HIGH_SEVERITY" 3 "APP_OFFGASSING_SEVERITY_MEDIUM_SEVERITY" 2 "APP_OFFGASSING_SEVERITY_LESS_SEVERITY" 1 "APP_OFFGASSING_SEVERITY_CLEAR" 0 "APP_OFFGASSING_SEVERITY_SNA" ;
VAL_ 603 APP_offgassingDetectionState 2 "APP_OFFGASSING_DETECTION_ACTIVE" 1 "APP_OFFGASSING_DETECTION_SKIPPED" 0 "APP_OFFGASSING_DETECTION_SNA" ;
VAL_ 603 APP_offgassingMaxProbabilityLong 12 "APP_OFFGASSING_DETECTION_PERCENT_16_PLUS" 11 "APP_OFFGASSING_DETECTION_PERCENT_16" 10 "APP_OFFGASSING_DETECTION_PERCENT_8" 9 "APP_OFFGASSING_DETECTION_PERCENT_4" 8 "APP_OFFGASSING_DETECTION_PERCENT_3" 7 "APP_OFFGASSING_DETECTION_PERCENT_2" 6 "APP_OFFGASSING_DETECTION_PERCENT_1_5" 5 "APP_OFFGASSING_DETECTION_PERCENT_1" 4 "APP_OFFGASSING_DETECTION_PERCENT_0_75" 3 "APP_OFFGASSING_DETECTION_PERCENT_0_5" 2 "APP_OFFGASSING_DETECTION_PERCENT_0_25" 1 "APP_OFFGASSING_DETECTION_PERCENT_0" 0 "APP_OFFGASSING_DETECTION_PERCENT_SNA" ;
VAL_ 603 APP_offgassingMaxProbabilityShor 12 "APP_OFFGASSING_DETECTION_PERCENT_16_PLUS" 11 "APP_OFFGASSING_DETECTION_PERCENT_16" 10 "APP_OFFGASSING_DETECTION_PERCENT_8" 9 "APP_OFFGASSING_DETECTION_PERCENT_4" 8 "APP_OFFGASSING_DETECTION_PERCENT_3" 7 "APP_OFFGASSING_DETECTION_PERCENT_2" 6 "APP_OFFGASSING_DETECTION_PERCENT_1_5" 5 "APP_OFFGASSING_DETECTION_PERCENT_1" 4 "APP_OFFGASSING_DETECTION_PERCENT_0_75" 3 "APP_OFFGASSING_DETECTION_PERCENT_0_5" 2 "APP_OFFGASSING_DETECTION_PERCENT_0_25" 1 "APP_OFFGASSING_DETECTION_PERCENT_0" 0 "APP_OFFGASSING_DETECTION_PERCENT_SNA" ;
VAL_ 603 APP_offgassingLongMaxCamera 3 "FISHEYE" 2 "NARROW" 1 "MAIN" 0 "SNA" ;
VAL_ 603 APP_offgassingShortMaxCamera 3 "FISHEYE" 2 "NARROW" 1 "MAIN" 0 "SNA" ;
VAL_ 603 APP_offgassingLongMaxDetector 2 "TRAFFIC_LIGHT" 1 "VEHICLE" 0 "SNA" ;
VAL_ 603 APP_offgassingShortMaxDetector 2 "TRAFFIC_LIGHT" 1 "VEHICLE" 0 "SNA" ;
VAL_ 843 APP_frontLeftParkAssist 255 "SNA" ;
VAL_ 843 APP_frontLeftMiddleParkAssist 255 "SNA" ;
VAL_ 843 APP_frontMiddleParkAssist 255 "SNA" ;
VAL_ 843 APP_frontRightMiddleParkAssist 255 "SNA" ;
VAL_ 843 APP_frontRightParkAssist 255 "SNA" ;
VAL_ 843 APP_parkAssistStatus 3 "SNA" 2 "TEMPORARY_FAILURE" 1 "ENABLED" 0 "DISABLED" ;
VAL_ 1353 APP_infoIndex 3 "AP_BOOT_COUNT" 2 "AP_GITHASH" 1 "FW_GITHASH" 0 "AP_BUILD_TYPE" ;
VAL_ 1353 APP_buildType 3 "AP_BUILDTYPE_REPO" 1 "AP_BUILDTYPE_LOCAL" 0 "AP_BUILDTYPE_SIGNED" ;
VAL_ 907 APP_rearLeftParkAssist 255 "SNA" ;
VAL_ 907 APP_rearLeftMiddleParkAssist 255 "SNA" ;
VAL_ 907 APP_rearMiddleParkAssist 255 "SNA" ;
VAL_ 907 APP_rearRightMiddleParkAssist 255 "SNA" ;
VAL_ 907 APP_rearRightParkAssist 255 "SNA" ;
